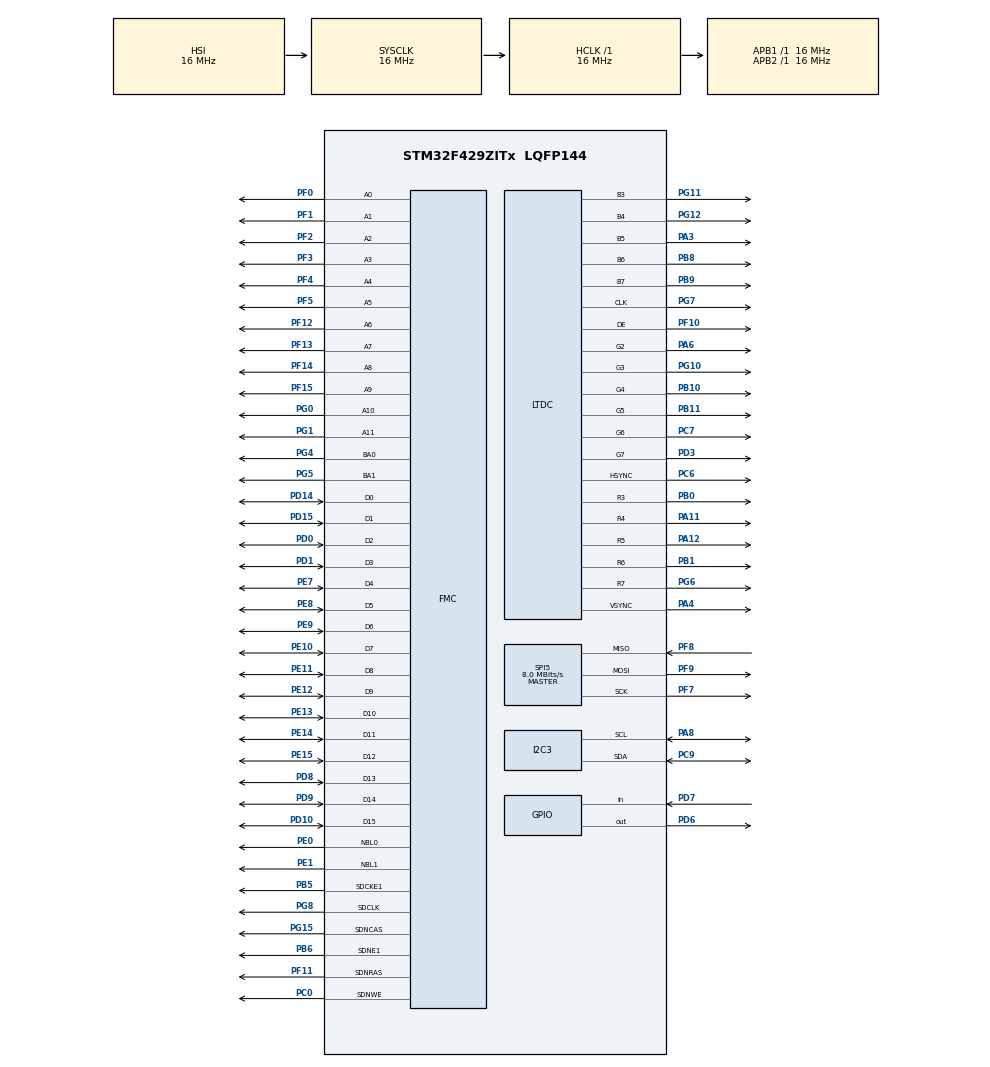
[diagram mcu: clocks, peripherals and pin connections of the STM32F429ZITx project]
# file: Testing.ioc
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DMA2D.ColorMode=DMA2D_OUTPUT_RGB565
LTDC.ActiveH=240
LTDC.ActiveW=320
Mcu.Family=STM32F4
Mcu.Name=STM32F429ZITx
Mcu.Package=LQFP144
NVIC.PriorityGroup=NVIC_PRIORITYGROUP_4
PA11.Mode=RGB565
PA11.Signal=LTDC_R4
PA12.Mode=RGB565
PA12.Signal=LTDC_R5
PA3.Mode=RGB565
PA3.Signal=LTDC_B5
PA4.Mode=RGB565
PA4.Signal=LTDC_VSYNC
PA6.Mode=RGB565
PA6.Signal=LTDC_G2
PA8.Mode=I2C
PA8.Signal=I2C3_SCL
PB0.Mode=RGB565
PB0.Signal=LTDC_R3
PB1.Mode=RGB565
PB1.Signal=LTDC_R6
PB10.Mode=RGB565
PB10.Signal=LTDC_G4
PB11.Mode=RGB565
PB11.Signal=LTDC_G5
PB5.Mode=SdramChipSelect2_1
PB5.Signal=FMC_SDCKE1
PB6.Mode=SdramChipSelect2_1
PB6.Signal=FMC_SDNE1
PB8.Mode=RGB565
PB8.Signal=LTDC_B6
PB9.Mode=RGB565
PB9.Signal=LTDC_B7
PC0.Signal=FMC_SDNWE
PC6.Mode=RGB565
PC6.Signal=LTDC_HSYNC
PC7.Mode=RGB565
PC7.Signal=LTDC_G6
PC9.Mode=I2C
PC9.Signal=I2C3_SDA
PD0.Signal=FMC_D2_DA2
PD1.Signal=FMC_D3_DA3
PD10.Signal=FMC_D15_DA15
PD14.Signal=FMC_D0_DA0
PD15.Signal=FMC_D1_DA1
PD3.Mode=RGB565
PD3.Signal=LTDC_G7
PD6.Signal=GPIO_Output
PD7.Signal=GPIO_Input
PD8.Signal=FMC_D13_DA13
PD9.Signal=FMC_D14_DA14
PE0.Signal=FMC_NBL0
PE1.Signal=FMC_NBL1
PE10.Signal=FMC_D7_DA7
PE11.Signal=FMC_D8_DA8
PE12.Signal=FMC_D9_DA9
PE13.Signal=FMC_D10_DA10
PE14.Signal=FMC_D11_DA11
PE15.Signal=FMC_D12_DA12
PE7.Signal=FMC_D4_DA4
PE8.Signal=FMC_D5_DA5
PE9.Signal=FMC_D6_DA6
PF0.Signal=FMC_A0
PF1.Signal=FMC_A1
PF10.Mode=RGB565
PF10.Signal=LTDC_DE
PF11.Signal=FMC_SDNRAS
PF12.Signal=FMC_A6
PF13.Signal=FMC_A7
PF14.Signal=FMC_A8
PF15.Signal=FMC_A9
PF2.Signal=FMC_A2
PF3.Signal=FMC_A3
PF4.Signal=FMC_A4
PF5.Signal=FMC_A5
PF7.Mode=Full_Duplex_Master
PF7.Signal=SPI5_SCK
PF8.Mode=Full_Duplex_Master
PF8.Signal=SPI5_MISO
PF9.Mode=Full_Duplex_Master
PF9.Signal=SPI5_MOSI
PG0.Signal=FMC_A10
PG1.Signal=FMC_A11
PG10.Mode=RGB565
PG10.Signal=LTDC_G3
PG11.Mode=RGB565
PG11.Signal=LTDC_B3
PG12.Mode=RGB565
PG12.Signal=LTDC_B4
PG15.Signal=FMC_SDNCAS
PG4.Signal=FMC_A14_BA0
PG5.Signal=FMC_A15_BA1
PG6.Mode=RGB565
PG6.Signal=LTDC_R7
PG7.Mode=RGB565
PG7.Signal=LTDC_CLK
PG8.Signal=FMC_SDCLK
ProjectManager.HeapSize=0x200
ProjectManager.StackSize=0x400
ProjectManager.TargetToolchain=STM32CubeIDE
RCC.48MHZClocksFreq_Value=90000000
RCC.AHBFreq_Value=16000000
RCC.APB1Freq_Value=16000000
RCC.APB2Freq_Value=16000000
RCC.CortexFreq_Value=16000000
RCC.HSE_VALUE=25000000
RCC.HSI_VALUE=16000000
RCC.LSE_VALUE=32768
RCC.PLLN=360
RCC.PLLSAIN=432
RCC.SYSCLKFreq_VALUE=16000000
RCC.VCOOutputFreq_Value=360000000
SH.FMC_A0.0=FMC_A0,12b-sda1
SH.FMC_A1.0=FMC_A1,12b-sda1
SH.FMC_A10.0=FMC_A10,12b-sda1
SH.FMC_A11.0=FMC_A11,12b-sda1
SH.FMC_A14_BA0.0=FMC_BA0,FourSdramBanks1
SH.FMC_A15_BA1.0=FMC_BA1,FourSdramBanks1
SH.FMC_A2.0=FMC_A2,12b-sda1
SH.FMC_A3.0=FMC_A3,12b-sda1
SH.FMC_A4.0=FMC_A4,12b-sda1
SH.FMC_A5.0=FMC_A5,12b-sda1
SH.FMC_A6.0=FMC_A6,12b-sda1
SH.FMC_A7.0=FMC_A7,12b-sda1
SH.FMC_A8.0=FMC_A8,12b-sda1
SH.FMC_A9.0=FMC_A9,12b-sda1
SH.FMC_D0_DA0.0=FMC_D0,sd-16b-d1
SH.FMC_D10_DA10.0=FMC_D10,sd-16b-d1
SH.FMC_D11_DA11.0=FMC_D11,sd-16b-d1
SH.FMC_D12_DA12.0=FMC_D12,sd-16b-d1
SH.FMC_D13_DA13.0=FMC_D13,sd-16b-d1
SH.FMC_D14_DA14.0=FMC_D14,sd-16b-d1
SH.FMC_D15_DA15.0=FMC_D15,sd-16b-d1
SH.FMC_D1_DA1.0=FMC_D1,sd-16b-d1
SH.FMC_D2_DA2.0=FMC_D2,sd-16b-d1
SH.FMC_D3_DA3.0=FMC_D3,sd-16b-d1
SH.FMC_D4_DA4.0=FMC_D4,sd-16b-d1
SH.FMC_D5_DA5.0=FMC_D5,sd-16b-d1
SH.FMC_D6_DA6.0=FMC_D6,sd-16b-d1
SH.FMC_D7_DA7.0=FMC_D7,sd-16b-d1
SH.FMC_D8_DA8.0=FMC_D8,sd-16b-d1
SH.FMC_D9_DA9.0=FMC_D9,sd-16b-d1
SH.FMC_NBL0.0=FMC_NBL0,Sd2ByteEnable1
SH.FMC_NBL1.0=FMC_NBL1,Sd2ByteEnable1
SH.FMC_SDCLK.0=FMC_SDCLK,12b-sda1
SH.FMC_SDNCAS.0=FMC_SDNCAS,12b-sda1
SH.FMC_SDNRAS.0=FMC_SDNRAS,12b-sda1
SH.FMC_SDNWE.0=FMC_SDNWE,12b-sda1
SPI5.CalculateBaudRate=8.0 MBits/s
SPI5.Direction=SPI_DIRECTION_2LINES
SPI5.Mode=SPI_MODE_MASTER
SPI5.VirtualType=VM_MASTER
VP_DMA2D_VS_DMA2D.Mode=DMA2D_Activate
board=custom

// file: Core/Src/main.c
/* USER CODE BEGIN Header */
/**
  ******************************************************************************
  * @file           : main.c
  * @brief          : Main program body
  ******************************************************************************
  * @attention
  *
  * <h2><center>&copy; Copyright (c) 2021 STMicroelectronics.
  * All rights reserved.</center></h2>
  *
  * This software component is licensed by ST under BSD 3-Clause license,
  * the "License"; You may not use this file except in compliance with the
  * License. You may obtain a copy of the License at:
  *                        opensource.org/licenses/BSD-3-Clause
  *
  ******************************************************************************
  */
/* USER CODE END Header */
#include "main.h"
#include "stm32f4xx_hal.h"
/* USER CODE BEGIN Includes */
#include "MA_ILI9341.h"
/* USER CODE END Includes */

DMA2D_HandleTypeDef hdma2d;

I2C_HandleTypeDef hi2c3;

LTDC_HandleTypeDef hltdc;

SPI_HandleTypeDef hspi5;

SDRAM_HandleTypeDef hsdram1;

void SystemClock_Config(void);
static void MX_GPIO_Init(void);
static void MX_DMA2D_Init(void);
static void MX_FMC_Init(void);
static void MX_I2C3_Init(void);
static void MX_LTDC_Init(void);
static void MX_SPI5_Init(void);

/* USER CODE BEGIN 0 */
uint8_t myImage[] =
{
	0xff,0xff,0xff,0xff,0xff,0xff,0xff,0xff,0xff,0xff,0xff,0xff,0xff,0xff,0xff,0xff,0xff,0xff,0xff,0xff,0xff,0xff,0xff,0xff,0xff,0xff,0xff,0xff,0xff,0xff,0xff,0xff,0xff,0xff,0xff,0xff,0xff,0xff,0xff,0xff,0xff,0xff,0xff,0xff,0xff,0xff,0xff,0xff,0xff,0xff,0xff,0xff,0xff,0xff,0xff,0xff,0xff,0xff,0xff,0xff,0xff,0xff,0xff,0xff,0xff,0xff,0xff,0xff,0xff,0xff,0xff,0xff,0x9c,0xb1,0x39,0x85,0x39,0xc6,0x39,0xc6,0x39,0xe6,0x4a,0x48,0x42,0x27,0x42,0x27,0x5a,0xe9,0xef,0x9d,0xff,0xff,0xff,0xff,0xff,0xff,0xff,0xff,0xff,0xff,0xff,0xff,0xff,0xff,0xff,0xff,0xff,0xff,0xff,0xff,0xff,0xff,0xff,0xff,0xff,0xff,0xff,0xff,0xff,0xff,0xff,0xff,0xff,0xff,0xff,0xff,0xff,0xff,0xff,0xff,0xff,0xff,0xff,0xff,0xff,0xff,0xff,0xff,0xff,0xff,0xff,0xff,0xff,0xff,0xff,0xff,0xff,0xff,0xff,0xff,0xff,0xff,0xff,0xff,0xff,0xff,0xff,0xff
,0xff,0xff,0xff,0xff,0xff,0xff,0xff,0xff,0xff,0xff,0xff,0xff,0xff,0xff,0xff,0xff,0xff,0xff,0xff,0xff,0xff,0xff,0xff,0xff,0xff,0xff,0xff,0xff,0xff,0xff,0xff,0xff,0xff,0xff,0xff,0xff,0xff,0xff,0xff,0xff,0xff,0xff,0xff,0xff,0xff,0xff,0xff,0xff,0xff,0xff,0xff,0xff,0xff,0xff,0xff,0xff,0xff,0xff,0xff,0xff,0xff,0xff,0xff,0xff,0xff,0xff,0xff,0xff,0xff,0xff,0xff,0xff,0x94,0x70,0x5a,0x88,0x41,0xe7,0x39,0xc6,0x29,0x44,0x31,0x84,0x39,0xa5,0x4a,0x27,0x52,0x68,0xf7,0x7d,0xff,0xff,0xff,0xff,0xff,0xff,0xff,0xff,0xff,0xff,0xff,0xff,0xff,0xff,0xff,0xff,0xff,0xff,0xff,0xff,0xff,0xff,0xff,0xff,0xff,0xff,0xff,0xff,0xff,0xff,0xff,0xff,0xff,0xff,0xff,0xff,0xff,0xff,0xff,0xff,0xff,0xff,0xff,0xff,0xff,0xff,0xff,0xff,0xff,0xff,0xff,0xff,0xff,0xff,0xff,0xff,0xff,0xff,0xff,0xff,0xff,0xff,0xff,0xff,0xff,0xff,0xff,0xff
,0x7e,0x32,0x65,0xb0,0x65,0xb0,0x65,0x90,0x65,0x90,0x65,0x90,0x65,0x90,0x65,0x90,0x6d,0x90,0x6d,0x90,0x6d,0x90,0x6d,0x90,0x6d,0x90,0x6d,0x90,0x6d,0x90,0x6d,0x90,0x6d,0x90,0x6d,0x90,0x6d,0x90,0x6d,0x90,0x65,0x90,0x65,0xb0,0x6d,0x90,0x65,0xb0,0x65,0x90,0x65,0x90,0x65,0x90,0x65,0x90,0x65,0x90,0x65,0x90,0x6d,0x90,0x6d,0x90,0x75,0x90,0xae,0x15,0xbd,0xd5,0xbd,0xb4,0x84,0x0e,0x6b,0x2a,0x4a,0x48,0x4a,0x27,0x31,0x65,0x41,0xe6,0x4a,0x27,0x6b,0x2a,0x5a,0xa8,0xd6,0x78,0xde,0xda,0xc6,0xd8,0x7d,0xd2,0x75,0xd2,0x75,0xd2,0x75,0xd2,0x75,0xf2,0x75,0xf2,0x75,0xf2,0x75,0xf2,0x75,0xf2,0x75,0xd2,0x7d,0xf2,0x7d,0xf2,0x7d,0xf2,0x7d,0xf2,0x7d,0xf2,0x7e,0x12,0x7e,0x12,0x7e,0x12,0x7d,0xf2,0x7d,0xf2,0x7d,0xf2,0x7d,0xf2,0x7d,0xf2,0x7d,0xf2,0x7d,0xf2,0x7d,0xf2,0x7d,0xf2,0x7d,0xf3,0x7d,0xf3,0x7e,0x13,0x7e,0x33,0x8e,0x74
,0x0c,0x68,0x04,0x06,0x03,0xe6,0x03,0xe6,0x03,0xe6,0x03,0xe6,0x03,0xc6,0x03,0xc6,0x03,0xe6,0x03,0xc6,0x03,0xe6,0x03,0xe6,0x03,0xe6,0x03,0xe6,0x03,0xe6,0x03,0xe6,0x03,0xe6,0x03,0xe6,0x03,0xe6,0x03,0xe6,0x03,0xe6,0x03,0xe6,0x03,0xe6,0x04,0x06,0x04,0x06,0x03,0xe6,0x03,0xe6,0x03,0xe6,0x03,0xe6,0x03,0xe6,0x03,0xe6,0x03,0xe6,0x03,0xc6,0x6c,0xee,0xe7,0x1a,0xc5,0xd4,0x83,0xed,0x52,0x68,0x52,0x68,0x6b,0x4b,0x42,0x26,0x6b,0x2a,0x5a,0xc9,0x7b,0xad,0x4a,0x47,0xbd,0xd4,0xef,0x7c,0xa6,0x14,0x03,0xc6,0x03,0xe7,0x03,0xe7,0x03,0xe6,0x03,0xc6,0x03,0xc6,0x03,0xc6,0x03,0xe6,0x03,0xe6,0x03,0xe6,0x03,0xe6,0x03,0xe6,0x03,0xe6,0x03,0xe6,0x03,0xe7,0x03,0xe7,0x03,0xe7,0x03,0xe7,0x03,0xe7,0x03,0xe7,0x03,0xe7,0x03,0xe7,0x03,0xe7,0x03,0xe7,0x03,0xe6,0x03,0xe6,0x03,0xe7,0x03,0xe7,0x03,0xe7,0x03,0xe7,0x04,0x07,0x0c,0x28
,0x04,0x48,0x04,0x07,0x04,0x07,0x03,0xe7,0x03,0xe6,0x03,0xc7,0x03,0xa6,0x03,0x86,0x03,0xa6,0x03,0xc6,0x03,0xc6,0x03,0xc6,0x03,0xc6,0x03,0xc6,0x03,0xc6,0x03,0xe6,0x03,0xe6,0x03,0xe6,0x03,0xc6,0x03,0xe6,0x03,0xe6,0x03,0xe7,0x03,0xc6,0x03,0xe6,0x04,0x06,0x03,0xe6,0x03,0xe6,0x03,0xe6,0x03,0xe6,0x03,0xc6,0x03,0xc6,0x03,0xc6,0x03,0xe6,0x5c,0x6c,0xa5,0x12,0x9c,0x8f,0x7b,0xac,0x5a,0x89,0x42,0x27,0x8c,0x2e,0xce,0x36,0xbd,0xb5,0x4a,0x47,0x73,0xac,0x4a,0x47,0x94,0x90,0xad,0x74,0x95,0x52,0x03,0xa7,0x03,0xc7,0x03,0xc7,0x03,0xe7,0x03,0xe7,0x03,0xe7,0x03,0x86,0x03,0x86,0x03,0xe6,0x03,0xe6,0x03,0xe6,0x03,0xc6,0x03,0xc6,0x03,0xe7,0x03,0xe7,0x03,0xe7,0x03,0xe7,0x03,0xe7,0x03,0xe7,0x03,0xe7,0x03,0xe7,0x03,0xe7,0x03,0xe7,0x03,0xc7,0x03,0xa7,0x03,0xa7,0x03,0xe7,0x03,0xe7,0x03,0xe7,0x03,0xe7,0x03,0xe7,0x0c,0x08
,0x04,0x27,0x03,0xe7,0x03,0xe7,0x03,0xe6,0x03,0xe6,0x03,0xe7,0x33,0x89,0x4b,0xca,0x33,0x69,0x03,0xc6,0x03,0xc6,0x03,0xc6,0x03,0xc6,0x03,0xc6,0x03,0xe6,0x03,0xe6,0x03,0xe6,0x03,0xe6,0x03,0xe6,0x03,0xe6,0x03,0xe6,0x03,0xe6,0x03,0xe6,0x03,0xe6,0x03,0xe6,0x03,0xe6,0x03,0xe6,0x03,0xe6,0x03,0xe6,0x03,0xe5,0x03,0xe6,0x03,0xc6,0x03,0xe6,0x5c,0x6c,0x94,0x90,0x7b,0xab,0x73,0x6b,0x41,0xe6,0x42,0x06,0x5a,0xa8,0x94,0x6f,0x7b,0xcd,0x42,0x06,0x4a,0x88,0x52,0x88,0x94,0x4e,0xa5,0x32,0x95,0x52,0x03,0x87,0x03,0xe7,0x03,0xc7,0x03,0xe7,0x03,0xe7,0x03,0xa6,0x64,0x49,0x6c,0x69,0x03,0xa6,0x03,0xc7,0x03,0xc6,0x03,0xc6,0x03,0xc6,0x03,0xe7,0x03,0xe7,0x03,0xe7,0x03,0xe7,0x03,0xe7,0x03,0xe7,0x03,0xe7,0x03,0xe7,0x03,0xe7,0x03,0xe7,0x23,0x68,0x2b,0x27,0x3b,0x88,0x03,0xa7,0x03,0xe7,0x03,0xe7,0x03,0xe7,0x03,0xe7,0x14,0x08
,0x04,0x27,0x03,0xe7,0x03,0xe7,0x03,0xe7,0x03,0xe7,0x03,0xe7,0x2b,0x07,0x74,0x0a,0x4b,0xca,0x03,0xa6,0x03,0xc6,0x03,0xc6,0x03,0xc6,0x03,0xa5,0x03,0xe6,0x03,0xe6,0x03,0xe6,0x1c,0x28,0x3c,0x4b,0x33,0xa9,0x44,0x2b,0x23,0xe8,0x03,0x45,0x03,0x46,0x03,0x26,0x03,0x46,0x03,0x45,0x03,0x25,0x03,0x45,0x03,0xa6,0x03,0xe6,0x03,0xe6,0x03,0xe6,0x74,0xcf,0xd6,0x98,0xa5,0x31,0x73,0x8b,0x10,0xc2,0x18,0xc2,0x29,0x44,0x29,0x03,0x29,0x44,0x21,0x03,0x20,0xe2,0x4a,0x47,0xad,0x73,0xef,0x5c,0xa5,0xb4,0x03,0x86,0x03,0xe7,0x03,0xa6,0x03,0xe7,0x03,0xe7,0x03,0xc7,0x33,0x66,0x3b,0x87,0x03,0xc6,0x03,0xc7,0x03,0xc7,0x03,0xc6,0x03,0xc6,0x03,0xe7,0x03,0xe7,0x03,0xe7,0x03,0xe7,0x03,0xe7,0x03,0xe7,0x03,0xe7,0x03,0xe7,0x03,0xe7,0x03,0xe7,0x1b,0x07,0x6b,0xca,0x4b,0xeb,0x03,0xa7,0x03,0xe7,0x03,0xe7,0x03,0xc7,0x03,0xe7,0x14,0x08
,0x04,0x27,0x03,0xe7,0x03,0xe7,0x03,0xe7,0x03,0xe7,0x03,0xe7,0x33,0x89,0x4b,0x49,0x4b,0xaa,0x03,0xc6,0x03,0xc6,0x03,0xc6,0x03,0xc6,0x03,0xc6,0x03,0xe6,0x03,0xe6,0x03,0xe6,0x34,0x2a,0x84,0x4f,0x52,0x89,0x8c,0x8f,0x5c,0x6c,0x64,0xee,0x2c,0x49,0x03,0xa6,0x03,0xa6,0x03,0xa6,0x03,0x85,0x0b,0x45,0x03,0x45,0x03,0xc6,0x03,0xe6,0x03,0xe6,0x13,0x47,0x23,0x47,0x3b,0x68,0x63,0x2a,0x10,0xc2,0x10,0xa1,0x52,0x68,0x7b,0xad,0x63,0x0b,0x18,0xe2,0x20,0xe3,0x52,0x27,0x53,0xca,0x23,0x47,0x23,0x67,0x03,0xa7,0x03,0xc7,0x03,0xc7,0x03,0xc7,0x03,0xe7,0x03,0xe7,0x03,0xc6,0x03,0xc6,0x03,0xc7,0x03,0xc6,0x03,0xc7,0x03,0xe7,0x03,0xe7,0x03,0xe7,0x03,0xe7,0x03,0xe7,0x03,0xe7,0x03,0xe7,0x03,0xe7,0x03,0xe7,0x03,0xe7,0x03,0xe7,0x03,0xe7,0x2b,0x69,0x43,0x49,0x4b,0xaa,0x03,0xa7,0x03,0xe7,0x03,0xe7,0x03,0xc7,0x03,0xc7,0x14,0x08
,0x04,0x08,0x03,0xe7,0x03,0xe7,0x03,0xe7,0x03,0xe7,0x03,0xc7,0x03,0x46,0x2b,0x88,0x0b,0x66,0x03,0xc6,0x03,0xc6,0x03,0xc6,0x03,0xc6,0x03,0xe6,0x03,0xe6,0x03,0xc6,0x03,0xc6,0x2c,0x29,0x84,0x6f,0x5b,0x2a,0x7c,0x4e,0x4b,0xcb,0x1b,0xc9,0x13,0xc8,0x03,0x65,0x03,0x65,0x03,0x65,0x03,0x65,0x03,0x65,0x03,0xc6,0x03,0xe6,0x03,0xa6,0x03,0xc6,0x0b,0x46,0x13,0x47,0x4b,0xea,0x63,0x4a,0x10,0xa1,0x18,0xc2,0x63,0x0a,0xad,0x53,0x5a,0xea,0x31,0x64,0x20,0xe2,0x4a,0x47,0x4b,0xea,0x13,0x47,0x0b,0x46,0x03,0xa7,0x03,0xc7,0x1c,0x09,0x0b,0xe8,0x03,0xe7,0x03,0xe7,0x03,0xe7,0x03,0xc6,0x03,0xe6,0x03,0xc7,0x03,0xc7,0x03,0xc7,0x03,0xc6,0x03,0xc6,0x03,0xc6,0x03,0xe7,0x03,0xe7,0x03,0xc7,0x03,0xe7,0x03,0xe7,0x03,0xe7,0x04,0x07,0x04,0x07,0x03,0xa7,0x3b,0xeb,0x0b,0x67,0x03,0xe7,0x03,0xe7,0x03,0xe7,0x03,0xe7,0x03,0xc7,0x13,0xe8
,0x04,0x07,0x03,0xe7,0x03,0xe7,0x03,0xe7,0x03,0xe6,0x03,0xc6,0x13,0x87,0x74,0x6d,0x33,0xc9,0x03,0xa6,0x03,0xc6,0x03,0xc6,0x03,0xc6,0x03,0xc6,0x03,0xe6,0x03,0xc6,0x03,0xc6,0x1b,0xe7,0xbe,0x37,0xb5,0xd5,0xd6,0xb8,0x85,0x50,0x2c,0x49,0x03,0xc6,0x03,0xc6,0x03,0xc6,0x03,0xc6,0x03,0xe6,0x03,0xe6,0x03,0xe6,0x0c,0x07,0x0b,0xe7,0x03,0xe7,0x64,0x8f,0xce,0x98,0x9d,0x32,0x6b,0x4b,0x10,0xa1,0x63,0x0a,0x73,0x6b,0xad,0x33,0x73,0xcd,0x73,0x4c,0x31,0x23,0x52,0x47,0xa5,0x52,0xd6,0x79,0xa5,0x93,0x0b,0xa7,0x13,0xe8,0x65,0x0e,0x3c,0xac,0x03,0xe7,0x03,0xe7,0x03,0xc6,0x03,0xa6,0x03,0xc6,0x03,0xc6,0x03,0xc6,0x03,0xc6,0x03,0xc6,0x03,0xc6,0x03,0xc6,0x03,0xc7,0x03,0xc7,0x03,0xc7,0x03,0xe7,0x03,0xc6,0x03,0xe7,0x03,0xc6,0x03,0xe6,0x23,0xe9,0x63,0xea,0x6c,0xac,0x03,0xc7,0x03,0xe7,0x03,0xe7,0x03,0xe7,0x03,0xe7,0x13,0xe8
,0x04,0x27,0x03,0xe6,0x03,0xe6,0x03,0xc6,0x03,0xc6,0x03,0xc6,0x0b,0x86,0x43,0xa9,0x44,0x4a,0x03,0xa6,0x03,0xc6,0x03,0xc6,0x03,0xc6,0x03,0xa5,0x03,0xa6,0x44,0xec,0x4c,0x8c,0x54,0xac,0xef,0x5b,0xe7,0x3b,0xef,0x5b,0xa5,0xd4,0x3c,0x6b,0x03,0xc6,0x03,0xc7,0x03,0xa6,0x03,0xc6,0x03,0xc6,0x03,0xe6,0x03,0xe6,0x55,0x0d,0x75,0x91,0x3c,0xac,0x6c,0x6d,0xad,0x53,0x83,0xed,0x6b,0x4b,0x10,0xa1,0x5a,0xa9,0x6b,0x4b,0x6b,0x2b,0x6b,0x4b,0x63,0x0a,0x29,0x23,0x4a,0x47,0x8c,0x2e,0xad,0x33,0x8d,0x12,0x03,0xa7,0x44,0x8c,0x74,0xef,0x5c,0x6d,0x02,0xe5,0x03,0xc7,0x03,0xc6,0x03,0xa6,0x03,0xc6,0x03,0xa7,0x03,0x86,0x03,0xa7,0x03,0x87,0x0b,0xa7,0x0b,0xe8,0x03,0xa6,0x0b,0xc7,0x0b,0xa7,0x03,0xa7,0x03,0xc7,0x03,0xe7,0x03,0xe7,0x03,0xe6,0x1b,0xe8,0x54,0x0b,0x4c,0xac,0x03,0xc7,0x03,0xc7,0x03,0xc7,0x03,0xe7,0x03,0xe7,0x14,0x08
,0x04,0x27,0x03,0xe6,0x03,0xe6,0x03,0xc6,0x03,0xc6,0x03,0xc6,0x03,0x85,0x03,0x04,0x03,0x44,0x03,0xa6,0x03,0xc5,0x0b,0xe6,0x0c,0x07,0x03,0xe7,0x03,0xc6,0x24,0x28,0x24,0x29,0x44,0x4b,0xdf,0x1a,0xd6,0xd9,0xde,0xd9,0xa5,0xf4,0x13,0xa7,0x14,0x29,0x14,0x08,0x0c,0x07,0x03,0xc6,0x03,0xc6,0x03,0xc6,0x03,0xe6,0x03,0xe6,0x03,0xc7,0x0b,0xc8,0x6c,0x8e,0xa5,0x53,0x73,0x8b,0x63,0xcd,0x8c,0x6e,0x8c,0x0c,0x7b,0xed,0x73,0xcc,0x7b,0xab,0x83,0xcb,0x84,0x2d,0x6c,0x0d,0x6b,0x6c,0xb5,0x93,0x8d,0x11,0x03,0xa7,0x3b,0xea,0x95,0x12,0x64,0x2d,0x2b,0xaa,0x4c,0x8c,0x24,0x29,0x34,0x49,0x03,0xa7,0x03,0x05,0x33,0xc9,0x2b,0xa9,0x0b,0x46,0x3c,0x2b,0x5c,0xef,0x0b,0x47,0x4c,0x8c,0x5c,0xee,0x03,0x46,0x03,0x46,0x03,0xe7,0x03,0xe7,0x03,0xe7,0x03,0xc7,0x0b,0x66,0x03,0xa7,0x03,0xc7,0x03,0xe7,0x03,0xe7,0x03,0xe7,0x03,0xe7,0x13,0xe8
,0x04,0x07,0x03,0xa6,0x03,0xe6,0x03,0xc6,0x03,0xc6,0x03,0xa6,0x03,0x85,0x03,0x04,0x03,0x45,0x03,0x85,0x03,0xa6,0x2c,0x6a,0x5d,0x0e,0x24,0x49,0x03,0xc6,0x03,0xc6,0x03,0xc6,0x34,0x2a,0xe7,0x5a,0xdf,0x1a,0xe7,0x1a,0xa5,0xd3,0x24,0x29,0x3c,0xac,0x65,0x4f,0x3c,0xab,0x03,0xe6,0x03,0xe6,0x03,0xe6,0x03,0xe6,0x03,0xc6,0x03,0xe6,0x03,0xc7,0x6c,0x6e,0xad,0xb4,0xb5,0x93,0x12,0x64,0x23,0x06,0x42,0xe7,0x42,0xa7,0x3a,0x86,0x3a,0x86,0x3a,0xe7,0x32,0xc7,0x3b,0x89,0x7c,0x4e,0xad,0x52,0x95,0x31,0x03,0x87,0x33,0x89,0x29,0x84,0x3b,0x28,0x12,0xe6,0x5c,0x6d,0x3b,0xa9,0x34,0x09,0x03,0x86,0x13,0x06,0x4c,0x0b,0x43,0x6a,0x44,0x2c,0x0a,0x85,0x1a,0xc6,0x0a,0xc5,0x0b,0x25,0x0b,0x25,0x03,0x25,0x03,0x46,0x03,0xc7,0x03,0xe6,0x03,0xe7,0x03,0xc6,0x03,0xa7,0x03,0xa7,0x03,0xc7,0x03,0xe7,0x03,0xe7,0x03,0xe7,0x03,0xe7,0x13,0xe8
,0x0c,0x07,0x03,0xe6,0x03,0xc6,0x03,0xc6,0x03,0xa5,0x03,0x65,0x13,0x87,0x23,0x87,0x13,0x87,0x03,0x85,0x03,0xa6,0x54,0xad,0x7d,0x0f,0x3c,0x0b,0x2b,0xc9,0x3c,0x6a,0x03,0xc6,0x34,0x29,0xc6,0x57,0xbe,0x36,0xd6,0xb8,0x9d,0x51,0x0b,0x86,0x03,0x85,0x03,0xc6,0x03,0xa5,0x03,0xc5,0x2c,0x4a,0x2c,0x6b,0x3c,0xac,0x44,0xed,0x34,0x2a,0x6d,0x91,0x3b,0xa9,0x64,0x8e,0x4b,0xaa,0x02,0xa4,0x02,0x82,0x0a,0x84,0x09,0xe3,0x09,0xe3,0x09,0xe3,0x0a,0x24,0x3b,0x08,0x3b,0xca,0x33,0x08,0x74,0x8f,0x4b,0xcb,0x03,0x26,0x3b,0x48,0x10,0xe2,0x33,0x08,0x4c,0x2c,0xad,0xb4,0x74,0xcf,0x95,0x93,0x44,0x2b,0x5c,0x2c,0x84,0x6f,0x84,0x8e,0x9d,0x72,0x33,0x28,0x9d,0x31,0x7c,0xef,0x34,0x4a,0x34,0x29,0x03,0x25,0x03,0x46,0x03,0xc7,0x03,0xe7,0x03,0xc7,0x03,0xc6,0x03,0xc7,0x03,0xc7,0x03,0xc7,0x03,0xc6,0x03,0xc7,0x03,0xe7,0x03,0xe7,0x13,0xe8
,0x0c,0x07,0x03,0xc6,0x03,0xc6,0x03,0xc6,0x03,0x85,0x03,0x66,0x3b,0x88,0x5b,0xab,0x3b,0x48,0x03,0x65,0x03,0x65,0x43,0x89,0x9d,0x53,0x54,0x2d,0x64,0x6e,0x44,0x8b,0x03,0xc6,0x03,0x65,0x5c,0x0c,0x4b,0x6a,0x7c,0x8e,0x3b,0x48,0x03,0x66,0x03,0x85,0x03,0x85,0x03,0x85,0x03,0xa5,0x3c,0x6b,0x3c,0xab,0x55,0x0e,0x54,0xee,0x5c,0xee,0x75,0x90,0x0b,0xc6,0x03,0xa6,0x03,0x65,0x03,0x05,0x02,0xa4,0x33,0x68,0x6c,0x6e,0x5b,0xcb,0x64,0x2d,0x43,0x8a,0x23,0x27,0x02,0xa4,0x03,0x05,0x03,0x06,0x03,0x26,0x03,0x26,0x4b,0xea,0x7c,0x2e,0x3b,0x69,0x43,0xca,0x8c,0x2d,0x64,0x0b,0x8c,0x4d,0x53,0xaa,0x53,0x49,0x42,0x26,0x4a,0x46,0x52,0xa8,0x43,0x69,0x7c,0x0c,0x63,0xcb,0x7c,0x8f,0x7c,0xaf,0x02,0xa5,0x03,0x46,0x03,0xc7,0x03,0xc7,0x03,0xc7,0x03,0xc7,0x03,0xc6,0x03,0xc6,0x03,0xc6,0x03,0xc6,0x03,0xc7,0x03,0xe7,0x03,0xc7,0x13,0xe8
,0x0c,0x07,0x03,0xc6,0x03,0xc6,0x03,0xa6,0x03,0xa6,0x13,0x67,0x19,0x83,0x4a,0x67,0x31,0xa4,0x3c,0x09,0x03,0x25,0x22,0x45,0x29,0x84,0x64,0x2c,0xad,0xf5,0x44,0x8b,0x03,0xc6,0x03,0xa6,0x54,0x4c,0x53,0xab,0x64,0x2c,0x43,0xca,0x03,0x66,0x03,0x65,0x03,0x65,0x03,0x65,0x03,0xa5,0x2c,0x49,0x03,0xc7,0x0b,0xa7,0x0b,0xa7,0x0b,0xa6,0x0b,0xc7,0x0b,0x86,0x03,0xa6,0x0b,0x66,0x0a,0xc4,0x4b,0xeb,0x6c,0x6d,0x7c,0x8f,0x8c,0xcf,0x84,0xaf,0x7c,0x6e,0x13,0x47,0x03,0x45,0x03,0x66,0x23,0xc8,0x54,0x6c,0x75,0x30,0x54,0x4b,0x5b,0xec,0x44,0x0b,0x44,0x0b,0x9c,0xd0,0x6c,0x0c,0x6c,0x2d,0x54,0x0b,0x32,0x47,0x21,0x44,0x21,0x24,0x29,0x64,0x43,0x8a,0x84,0x6e,0x74,0x6e,0x95,0x10,0x74,0x8e,0x02,0xc5,0x03,0x66,0x03,0xc7,0x03,0xc7,0x03,0xc7,0x03,0xe7,0x03,0xe7,0x03,0xc6,0x03,0xc6,0x03,0xe7,0x03,0xe7,0x03,0xe7,0x03,0xe7,0x0c,0x08
,0x0c,0x07,0x03,0xc6,0x03,0xc6,0x03,0xa5,0x85,0x90,0x9d,0xb2,0x19,0x02,0x4a,0x46,0x19,0x02,0x3b,0x68,0x02,0x84,0x19,0xc4,0x19,0x23,0x64,0x0c,0x7c,0x6f,0x4b,0xea,0x0b,0xc7,0x44,0xac,0x74,0x0c,0x6c,0x0c,0x63,0x6a,0x5c,0x4c,0x4c,0xcd,0x03,0x66,0x2c,0x09,0x23,0xe8,0x03,0xa6,0x2c,0x4a,0x34,0x8b,0x85,0x30,0x95,0x52,0x95,0x52,0x95,0x93,0x95,0x72,0x7d,0x10,0x95,0x31,0x54,0x0c,0x53,0xab,0x7c,0x2e,0x7c,0x0d,0x84,0x0d,0x7c,0x4e,0x7b,0xcc,0x1c,0x08,0x03,0xa6,0x03,0xa6,0x14,0x08,0x4c,0xcd,0x24,0x09,0x54,0xcd,0xb5,0xf4,0x5c,0xce,0x4c,0x4b,0x8d,0x10,0x53,0xcb,0x2b,0xc9,0x13,0x47,0x3a,0xe8,0x3a,0x06,0x21,0xc4,0x63,0x2a,0x4b,0xeb,0x6c,0x6e,0x64,0x6d,0x64,0x8e,0x54,0x0c,0x02,0xc5,0x03,0x66,0x03,0xc7,0x03,0xe6,0x03,0xe6,0x03,0xe6,0x03,0xe6,0x03,0xe6,0x03,0xe7,0x03,0xe7,0x03,0xe7,0x03,0xe7,0x03,0xe7,0x0b,0xe8
,0x0c,0x07,0x03,0xc6,0x03,0xc6,0x03,0xa5,0x34,0x09,0x43,0xe9,0x29,0xa4,0x18,0xa1,0x21,0x03,0x3b,0x48,0x02,0x24,0x3a,0xe8,0x74,0x2e,0x6c,0x8d,0x84,0xf0,0x4b,0xeb,0x13,0x67,0x75,0x4f,0x8c,0xf0,0x95,0x11,0x84,0x8f,0x74,0xae,0x5c,0xcd,0x1b,0x67,0x5c,0x6c,0x33,0xea,0x03,0x87,0x03,0xc7,0x03,0xc7,0x64,0x2c,0x63,0xcc,0x5b,0x6a,0x7c,0x8f,0x53,0x29,0x6c,0x6e,0x52,0xe8,0x53,0xeb,0x7c,0xaf,0x95,0x31,0x63,0xcc,0x63,0xcc,0x6c,0x0d,0x63,0x6b,0x1c,0x08,0x03,0xa6,0x03,0xc6,0x44,0xac,0x65,0x0f,0x2c,0x49,0x7c,0xef,0xd6,0x75,0x4c,0x2b,0x4c,0x4b,0xa5,0x92,0x8c,0x6e,0x9d,0x52,0x3b,0xa9,0x32,0xe7,0x2a,0xa6,0x0a,0x03,0x5b,0xac,0x03,0x06,0x03,0x87,0x23,0xe9,0x6c,0x8e,0x64,0x6e,0x02,0xc5,0x03,0x66,0x03,0xc7,0x03,0xc7,0x03,0xe7,0x03,0xe7,0x03,0xe6,0x03,0xe6,0x0b,0xc7,0x03,0xe7,0x03,0xe7,0x03,0xe7,0x03,0xe7,0x0b,0xe8
,0x0c,0x07,0x03,0xc6,0x03,0xc6,0x03,0xa5,0x03,0x65,0x0b,0x25,0x21,0xa4,0x39,0x84,0x18,0xe2,0x3b,0x29,0x02,0x24,0x43,0x8a,0x53,0xeb,0x3b,0xc9,0x0b,0x05,0x03,0x05,0x03,0x25,0x13,0x86,0x4c,0x0b,0x4c,0x2b,0x44,0x8c,0x34,0x2a,0x5c,0x4c,0xce,0x77,0xbd,0xd5,0xb6,0x15,0x44,0x0b,0x03,0xc7,0x03,0xc6,0x75,0x0f,0x84,0xf0,0x85,0x10,0x85,0x30,0x84,0xf0,0x74,0xcf,0x7c,0xcf,0x5c,0xcd,0x44,0x2a,0x54,0x2c,0x7c,0x6e,0x94,0xf0,0x8c,0xf0,0x94,0xcf,0x23,0xa8,0x0b,0x46,0x0b,0xa6,0x34,0x6a,0x7d,0x91,0x2c,0x29,0x7c,0xef,0xce,0x14,0x54,0x6c,0x44,0x4b,0x84,0x2d,0x5b,0x09,0x74,0x0d,0x64,0x6e,0x4c,0x4c,0x0b,0x26,0x03,0x65,0x03,0x66,0x03,0x66,0x03,0x86,0x2c,0x09,0x4b,0x2a,0x5b,0xcc,0x4c,0x0b,0x44,0x2b,0x7d,0xb1,0x7d,0x91,0x6d,0x70,0x7d,0x91,0x6d,0x30,0x5d,0x2f,0x75,0x90,0x3c,0xac,0x4c,0xed,0x03,0xe7,0x03,0xc7,0x0c,0x08
,0x0c,0x07,0x03,0xc7,0x03,0xc7,0x03,0x86,0x03,0x45,0x02,0xe4,0x19,0x42,0x6a,0xe8,0x18,0xe2,0x3b,0x08,0x02,0x64,0x3b,0x89,0x74,0x2e,0x74,0x0d,0x5c,0x4c,0x02,0xa4,0x02,0xc4,0x03,0x25,0x03,0x65,0x03,0x86,0x03,0xc6,0x23,0xc7,0xa5,0x11,0x52,0x68,0x39,0x84,0x4a,0x27,0x7c,0x4e,0x13,0xc8,0x03,0xe7,0x1b,0x48,0x1b,0x07,0x33,0x89,0x7c,0xce,0x23,0x47,0x13,0x26,0x13,0x26,0x23,0x67,0x65,0x0f,0x3c,0x0a,0x3b,0xea,0x33,0xc9,0x3b,0xea,0x3b,0xeb,0x2b,0xa9,0x75,0x10,0x2b,0xca,0x34,0x2a,0x54,0xee,0x03,0xc7,0x4c,0x8d,0xa5,0xd4,0x54,0x8d,0x1b,0xe9,0x34,0x0a,0x23,0xc8,0x2b,0xea,0x2b,0xe9,0x1b,0xa9,0x03,0x45,0x03,0x66,0x03,0x86,0x0b,0xa7,0x24,0x09,0x3c,0x0a,0x21,0x64,0x3a,0x68,0x4c,0x0c,0x8d,0x92,0x6d,0x2f,0x85,0x91,0x75,0x70,0x95,0xf3,0x5c,0xee,0x5d,0x2e,0x55,0x0d,0x5d,0x0e,0x6d,0x70,0x03,0xe7,0x03,0xe7,0x0c,0x07
,0x0c,0x08,0x03,0xc7,0x03,0xa7,0x5c,0xcd,0x5c,0xad,0x13,0x26,0x21,0x64,0x10,0xa1,0x18,0xe3,0x3b,0xa9,0x03,0x05,0x44,0x2b,0x6c,0x2d,0x64,0x2c,0x54,0x4b,0x03,0x45,0x13,0x66,0x1b,0x67,0x0b,0xc7,0x24,0x49,0x03,0xc6,0x44,0x2a,0x8c,0x0e,0x39,0xa5,0x39,0xc5,0x42,0x26,0x73,0x8c,0x2b,0xe9,0x0b,0xc7,0x54,0x8d,0x3c,0x0a,0x43,0x8a,0x8c,0x8e,0x2b,0x89,0x0b,0x05,0x13,0x06,0x2b,0x88,0x3b,0xe9,0x2b,0xa8,0x33,0x89,0x23,0x68,0x12,0xe6,0x64,0x6c,0xad,0xd4,0x5c,0x4c,0x23,0x68,0x2b,0x89,0x4c,0xcd,0x03,0xc7,0x44,0x6b,0x95,0x31,0x4c,0x8c,0x2c,0x0a,0x1b,0x47,0x03,0x06,0x03,0x06,0x2b,0x68,0x54,0x0c,0x43,0xea,0x74,0xef,0x4c,0x2b,0x1b,0x47,0x5c,0x6d,0x64,0xad,0x3a,0x47,0x4b,0x2a,0x0a,0xa5,0x0b,0x87,0x0b,0x87,0x14,0x08,0x0b,0xe7,0x14,0x08,0x14,0x08,0x03,0xe7,0x0b,0xe7,0x0b,0xe7,0x0b,0xe7,0x03,0xc7,0x03,0xc6,0x0b,0xe7
,0x0c,0x07,0x03,0xc7,0x03,0xc6,0x64,0xcd,0x54,0x8d,0x1b,0x46,0x29,0xc5,0x18,0xc2,0x19,0x23,0x33,0xa9,0x03,0x45,0x34,0x29,0x6d,0x2e,0x54,0xcc,0x0b,0xa6,0x44,0x8b,0x8d,0x50,0x94,0xf0,0x5c,0x0c,0x8c,0xd0,0x3b,0xc9,0x53,0xaa,0x83,0xed,0x4a,0x47,0x6b,0x4b,0x4a,0x48,0x73,0x8b,0x2b,0xa9,0x03,0xa7,0x13,0x47,0x02,0xc5,0x54,0x0b,0xa5,0x92,0x2b,0x89,0x43,0x6a,0x74,0x6e,0x63,0xab,0x74,0x4d,0x74,0x2d,0x5b,0xcb,0x7c,0x8e,0x43,0x8b,0x4b,0x69,0x94,0x8e,0x2b,0x67,0x02,0xe5,0x02,0xe5,0x02,0xe5,0x03,0x25,0x4c,0x0b,0x4a,0xc8,0x74,0xae,0x5c,0xce,0x4c,0x6c,0x02,0xe6,0x02,0xe6,0x5c,0x0c,0x94,0xf1,0x23,0x08,0x23,0x47,0x33,0xa9,0x03,0x06,0x0b,0x06,0x4c,0x0c,0x64,0x0c,0x64,0x4d,0x03,0x46,0x03,0x26,0x03,0x46,0x03,0x86,0x03,0xe6,0x03,0xe6,0x03,0xc7,0x03,0xc6,0x03,0xe7,0x03,0xe7,0x03,0xe7,0x03,0xe7,0x03,0xc6,0x0b,0xe7
,0x0c,0x07,0x03,0xc7,0x03,0xc6,0x4c,0x8b,0x6d,0x4f,0x0b,0x06,0x19,0x42,0x7b,0x68,0x18,0xc1,0x33,0x87,0x03,0x24,0x03,0x45,0x13,0xa6,0x13,0xe7,0x03,0x85,0x3c,0x4b,0x7c,0xef,0x63,0xab,0x64,0x2c,0x8c,0x6f,0x8d,0x51,0x85,0x10,0x84,0x0d,0x4a,0x27,0x84,0x0e,0x52,0x88,0x73,0x8b,0x2b,0x88,0x03,0xa6,0x03,0x26,0x02,0xc5,0x23,0x47,0x7c,0xef,0x12,0xa5,0x43,0x49,0x74,0x2e,0x63,0x8c,0x7c,0x4e,0x7c,0x0d,0x63,0x8b,0x84,0x4e,0x43,0x4a,0x3b,0x69,0x85,0x11,0x1b,0x67,0x03,0x26,0x03,0x05,0x02,0xe5,0x03,0x26,0x44,0x2b,0x8c,0xf0,0x3c,0x4b,0x03,0x26,0x1b,0x27,0xb6,0x35,0x95,0x12,0x31,0xc6,0x39,0x85,0x42,0x48,0xad,0xf4,0xd6,0xf9,0x4c,0x8d,0x4c,0x4c,0x4c,0x4c,0x75,0x30,0x6d,0x30,0x03,0xa7,0x03,0x66,0x03,0x26,0x03,0x46,0x03,0xa6,0x03,0xe7,0x03,0xe7,0x03,0xe7,0x03,0xe7,0x03,0xc6,0x03,0xe7,0x03,0xe7,0x03,0xe7,0x0c,0x07
,0x0c,0x07,0x03,0xc7,0x03,0xc6,0x54,0xcd,0x6c,0xce,0x13,0x06,0x19,0x23,0x18,0xc1,0x18,0xc1,0x33,0x88,0x03,0x44,0x03,0x65,0x03,0xa5,0x03,0xc6,0x03,0xa6,0x44,0xcc,0x75,0x0f,0x74,0xef,0x54,0x6b,0x8d,0x70,0x54,0xac,0x5c,0x6d,0x84,0x2d,0x4a,0x68,0x73,0xac,0x52,0xa8,0x73,0x8b,0x2b,0x68,0x1c,0x08,0x3b,0xe9,0x2b,0xa8,0x1b,0x27,0x85,0x10,0x3b,0x29,0x31,0xc6,0x31,0xe6,0x31,0xe6,0x31,0xe6,0x3a,0x06,0x32,0x06,0x32,0x06,0x29,0xe6,0x32,0xe8,0x54,0x0c,0x1b,0x68,0x03,0x66,0x03,0x05,0x02,0xe5,0x02,0xe5,0x13,0x07,0x33,0xea,0x13,0x46,0x03,0x26,0x1b,0xa8,0x85,0x51,0x9d,0x52,0x41,0xe6,0x5a,0x46,0x31,0xa5,0xb5,0xf4,0xd6,0xf9,0x54,0xce,0x5d,0x0f,0x2c,0x2a,0x03,0xa6,0x03,0xa6,0x03,0xc6,0x03,0xc6,0x03,0x66,0x03,0x46,0x03,0x46,0x03,0xa6,0x03,0xe7,0x03,0xe7,0x03,0xe7,0x03,0xc6,0x03,0xe7,0x03,0xe7,0x03,0xe7,0x0c,0x07
,0x0c,0x07,0x03,0xa6,0x03,0xc6,0x4c,0x8c,0x54,0x8c,0x13,0x05,0x3a,0x06,0x18,0xc2,0x19,0x01,0x33,0xa9,0x03,0x44,0x03,0x85,0x03,0xa6,0x03,0xa6,0x03,0xc6,0x03,0xc6,0x03,0xc6,0x03,0xa5,0x03,0xa6,0x13,0xa6,0x03,0xa5,0x3b,0xe9,0x8c,0x2e,0x52,0x88,0x7b,0xac,0x5a,0xc9,0x6b,0x6b,0x2a,0xe7,0x13,0x27,0x3b,0xea,0x23,0x68,0x3b,0x8a,0x8c,0x8f,0x63,0x6b,0x29,0x44,0x29,0x64,0x31,0xc6,0x31,0xe6,0x3a,0x07,0x3a,0x06,0x3a,0x06,0x31,0xc5,0x6b,0x6b,0x8c,0xcf,0x4c,0x2c,0x24,0x09,0x03,0x25,0x03,0x05,0x03,0x05,0x02,0xe5,0x02,0xe5,0x23,0xa8,0x23,0xc8,0x23,0xe9,0x85,0x30,0x95,0x52,0x41,0xc5,0x31,0x43,0x31,0xa4,0xad,0xd4,0xd6,0xd9,0x54,0xce,0x7d,0x51,0x3c,0x6b,0x03,0xa6,0x03,0xc6,0x03,0xc6,0x03,0xc6,0x03,0xc7,0x03,0x66,0x03,0x46,0x0b,0x26,0x03,0xa7,0x03,0xe6,0x03,0xe7,0x03,0xe7,0x03,0xe7,0x03,0xe7,0x03,0xe7,0x0c,0x07
,0x0c,0x08,0x03,0xe7,0x03,0xa6,0x65,0x0e,0x54,0x8b,0x23,0x47,0x21,0x43,0x4a,0x47,0x10,0xc1,0x53,0xeb,0x1b,0x26,0x23,0x88,0x64,0xac,0x4b,0xca,0x5c,0xad,0x03,0x04,0x03,0x65,0x03,0xe6,0x0b,0xc6,0x2c,0x29,0x03,0xa6,0x3c,0x09,0x8c,0x4e,0x52,0x88,0x83,0xed,0x63,0x0a,0x6b,0x4a,0x2a,0xc6,0x02,0xc4,0x02,0xe5,0x02,0xc5,0x43,0xeb,0xa5,0x32,0x84,0x2e,0x29,0xa5,0x42,0x27,0x31,0xa6,0x39,0xe6,0x3a,0x07,0x3a,0x27,0x3a,0x06,0x39,0xc5,0x8c,0x2e,0xa5,0x92,0x5c,0x4c,0x0b,0x05,0x03,0x25,0x03,0x25,0x03,0x25,0x03,0x06,0x03,0x05,0x3b,0xea,0x85,0x51,0x23,0xc9,0x7d,0x30,0x95,0x32,0x39,0xa5,0x41,0xe5,0x31,0xc5,0xad,0xb3,0xd6,0xb8,0x54,0xce,0x75,0x71,0x4c,0xcd,0x03,0xa6,0x03,0xc6,0x03,0xc6,0x03,0xc6,0x03,0xc6,0x03,0xc6,0x03,0x46,0x9e,0x14,0x2b,0xa8,0x03,0xa6,0x03,0xe7,0x03,0xe7,0x03,0xe7,0x03,0xe7,0x03,0xe7,0x0c,0x07
,0x04,0x08,0x03,0xe6,0x03,0xc6,0x03,0xa6,0x03,0x45,0x02,0xe5,0x11,0x02,0x21,0x02,0x10,0xa1,0x84,0xae,0x74,0x4d,0x74,0x8e,0x7c,0x4d,0x53,0x49,0x74,0xae,0x0a,0xe5,0x03,0x66,0x03,0xe6,0x44,0x6b,0x8c,0xb0,0x2c,0x2a,0x3c,0x0a,0x8c,0x4e,0x4a,0x27,0x6b,0x2b,0x5a,0xc9,0x63,0x2a,0x23,0x07,0x03,0x05,0x13,0x06,0x33,0xc9,0x4b,0xcb,0x8c,0x4f,0x6b,0x6c,0x31,0xc6,0x42,0x26,0x31,0xe6,0x3a,0x06,0x3a,0x06,0x3a,0x06,0x39,0xe6,0x31,0xa5,0x73,0x6b,0x8c,0xb0,0x43,0xcb,0x03,0x05,0x03,0x25,0x03,0x25,0x03,0x25,0x02,0xe5,0x03,0x05,0x34,0x0a,0x85,0x71,0x23,0xc8,0xa5,0xf3,0x8d,0x32,0x31,0xa5,0x62,0xe8,0x31,0xc5,0x9d,0x72,0xce,0xb7,0x44,0x8c,0x4c,0x8c,0x3c,0x6b,0x03,0xa6,0x03,0xa6,0x03,0xc6,0x03,0xc6,0x03,0xc6,0x03,0xe6,0x54,0xee,0xe7,0x3b,0xa6,0x55,0x0b,0x66,0x03,0xe7,0x03,0xe7,0x03,0xe7,0x04,0x07,0x03,0xe7,0x0c,0x07
,0x04,0x08,0x03,0xe6,0x03,0xc6,0x03,0xa6,0x03,0x65,0x0b,0x05,0x32,0x06,0x18,0xa1,0x11,0x02,0x33,0xa8,0x03,0x24,0x0b,0x85,0x24,0x08,0x24,0x29,0x1c,0x08,0x03,0xc6,0x3c,0x8b,0x6d,0x50,0x54,0x6c,0x8c,0xb0,0x43,0xca,0x43,0x89,0x8c,0x2e,0x4a,0x27,0x84,0x0e,0x5a,0xea,0x63,0x2a,0x22,0xc6,0x12,0xe6,0x64,0x6d,0x85,0x51,0x5c,0x6e,0x9d,0x32,0x7b,0xed,0x31,0xc6,0x3a,0x06,0x39,0xe6,0x31,0xe6,0x3a,0x06,0x42,0x07,0x42,0x27,0x31,0xc6,0x83,0xed,0xa5,0x73,0x54,0x4c,0x1b,0x87,0x03,0x25,0x03,0x25,0x03,0x05,0x02,0xe5,0x03,0x05,0x4c,0x8c,0x85,0x51,0x13,0x87,0x1b,0x67,0x1b,0x07,0x29,0xc6,0x39,0xc6,0x31,0xc6,0x33,0xa9,0x13,0x67,0x03,0x66,0x65,0x2f,0x3c,0x6b,0x03,0xa6,0x03,0xa6,0x03,0xc6,0x03,0xc6,0x03,0xc6,0x13,0xe8,0xc6,0xd8,0xe7,0x3b,0xd7,0x19,0x34,0x6b,0x04,0x07,0x04,0x06,0x04,0x06,0x04,0x06,0x03,0xe6,0x0c,0x07
,0x04,0x08,0x03,0xe7,0x03,0xc6,0x03,0xa6,0x03,0x45,0x02,0xe5,0x11,0x22,0x39,0xe4,0x10,0xa1,0x3b,0xa9,0x02,0xe5,0x0b,0x65,0x44,0x4a,0x3c,0x09,0x3c,0x4a,0x03,0xa6,0x0b,0xe7,0x0c,0x08,0x3c,0x8b,0x5c,0x2d,0x2b,0xe9,0x3b,0xca,0x94,0x6e,0x41,0xe6,0x31,0xc5,0x31,0xa5,0x63,0x0a,0x2a,0xe7,0x12,0xa5,0x8d,0x0f,0x5c,0x6d,0x3b,0xeb,0x94,0xd0,0x73,0xcd,0x31,0xe6,0x42,0x47,0x39,0xe6,0x39,0xe6,0x39,0xe6,0x42,0x27,0x31,0xc5,0x31,0xa5,0x7b,0xac,0x95,0x12,0x43,0xcb,0x0b,0x06,0x03,0x25,0x03,0x25,0x03,0x25,0x02,0xe5,0x03,0x05,0x1b,0x87,0x44,0x2b,0x1b,0xa8,0x03,0x05,0x1b,0x26,0x31,0xe6,0x39,0xe6,0x29,0xa5,0x13,0x06,0x03,0x26,0x0b,0x66,0x54,0xad,0x4c,0xcd,0x03,0xa6,0x03,0xa6,0x03,0xc6,0x03,0xc6,0x03,0xc6,0x6d,0x50,0xa6,0x75,0x54,0xad,0x34,0x2b,0x8d,0xf3,0x0c,0x07,0x03,0xe6,0x03,0xe6,0x03,0xe6,0x03,0xc6,0x0b,0xe7
,0x04,0x28,0x03,0xe7,0x03,0xc6,0x03,0xa5,0x03,0x45,0x02,0xe5,0x11,0x02,0x39,0xc5,0x10,0xa1,0x6c,0x6d,0x43,0x8a,0x64,0x2d,0x8c,0xaf,0x52,0xe8,0x84,0xcf,0x0a,0xe5,0x03,0xc6,0x03,0xe6,0x03,0xc6,0x0b,0xa6,0x03,0xc7,0x3c,0x4a,0x8c,0x8e,0x52,0x88,0x31,0x85,0x29,0x64,0x7b,0xab,0x22,0xc7,0x23,0x47,0x94,0xf0,0x6c,0x6d,0x43,0xca,0x9c,0xf1,0x73,0x8c,0x31,0xc5,0x42,0x06,0x39,0xc6,0x39,0xe6,0x42,0x27,0x3a,0x06,0x29,0xa5,0x29,0x84,0x7b,0x8c,0x95,0x32,0x4c,0x0c,0x03,0x25,0x03,0x25,0x03,0x25,0x03,0x05,0x02,0xe5,0x03,0x05,0x13,0x66,0x3c,0x4b,0x13,0x67,0x7d,0x51,0x64,0x4d,0x29,0xc5,0x42,0x26,0x31,0xa5,0x64,0x2c,0xae,0x35,0x3c,0x2b,0x3c,0x6c,0x3c,0x6c,0x03,0xa6,0x03,0xa6,0x03,0xc6,0x03,0xe6,0x24,0x4a,0xbe,0xb7,0x6d,0x50,0x3c,0x4b,0xb6,0x56,0xe7,0x3a,0x65,0x50,0x04,0x07,0x03,0xe7,0x03,0xe6,0x03,0xe6,0x04,0x07
,0x04,0x28,0x03,0xe7,0x03,0xe6,0x03,0xa6,0x03,0x65,0x03,0x05,0x29,0xc5,0x18,0xc2,0x18,0xe2,0x4c,0x0a,0x33,0xe8,0x3c,0x4a,0x44,0x6b,0x3c,0x2a,0x3c,0x6a,0x0b,0x05,0x03,0x45,0x03,0xe6,0x03,0xe6,0x03,0xc6,0x03,0xc6,0x13,0xc7,0x64,0x6c,0x9c,0xd0,0x7b,0x8c,0x8c,0x8f,0x84,0x4e,0x12,0xe5,0x13,0x06,0x9d,0x93,0x6c,0x8f,0x43,0xaa,0xa5,0x73,0x7c,0x0e,0x31,0xc5,0x31,0xe6,0x31,0xa5,0x31,0xc6,0x39,0xe6,0x39,0xe6,0x31,0x85,0x31,0x85,0x84,0x2e,0x9d,0x94,0x4c,0x2c,0x0b,0x26,0x03,0x05,0x03,0x25,0x03,0x25,0x02,0xe5,0x03,0x05,0x4c,0x8c,0x44,0x6c,0x23,0xa9,0x85,0x10,0x8d,0x11,0x29,0xa5,0x39,0x44,0x42,0x05,0x9d,0x52,0xce,0x98,0x54,0xad,0x4c,0xad,0x4c,0xcd,0x03,0xa6,0x03,0xa6,0x03,0xc6,0x03,0xc7,0x9e,0x34,0xdf,0x1a,0xd6,0xf9,0xdf,0x5a,0xce,0xd8,0xce,0xb8,0xc6,0xd8,0x14,0x08,0x03,0xe7,0x03,0xe6,0x03,0xe6,0x0c,0x07
,0x04,0x28,0x03,0xc6,0x03,0xc6,0x03,0xa6,0x03,0x65,0x03,0x05,0x19,0x42,0x31,0x83,0x10,0xc1,0x3b,0xa9,0x03,0x25,0x03,0x85,0x0b,0x86,0x0b,0x86,0x0b,0xc7,0x03,0x25,0x03,0x45,0x03,0xe6,0x03,0xe6,0x03,0xe6,0x03,0xe6,0x03,0xa6,0x23,0xe9,0x64,0xad,0xa5,0x93,0x8d,0x30,0x33,0xc9,0x34,0x4a,0x4b,0xeb,0x7d,0x30,0x54,0x6e,0x3b,0xec,0x4b,0xec,0x43,0x49,0x3a,0x47,0x42,0x47,0x3a,0x27,0x42,0x48,0x42,0x48,0x3a,0x27,0x42,0x48,0x32,0x06,0x1a,0x04,0x23,0x28,0x12,0xe6,0x33,0xe9,0x03,0x05,0x03,0x05,0x03,0x05,0x02,0xe5,0x03,0x05,0x3c,0x2a,0x4c,0x4b,0x2b,0xa9,0x7d,0x30,0x9d,0x92,0x31,0xe6,0x10,0x40,0x4a,0x68,0xad,0xb3,0xce,0xb8,0x54,0xcd,0x65,0x0e,0x44,0x8c,0x03,0xa6,0x03,0xc6,0x03,0xc6,0x14,0x08,0x96,0x14,0x96,0x14,0x9e,0x14,0x9e,0x14,0x9d,0xf4,0x9d,0xf4,0x7d,0xb2,0x1c,0x49,0x03,0xe6,0x03,0xe6,0x03,0xe6,0x0c,0x08
,0x04,0x07,0x03,0xe7,0x03,0xc6,0x03,0xa6,0x03,0x65,0x03,0x25,0x19,0x42,0x52,0x86,0x10,0xc2,0x7c,0x6e,0x43,0x8a,0x4b,0xaa,0xa5,0x72,0x6b,0xab,0x8d,0x51,0x02,0x84,0x03,0x45,0x04,0x06,0x03,0xe6,0x03,0xe6,0x03,0xe6,0x03,0xc6,0x03,0xa5,0x0b,0x45,0x13,0x26,0x0b,0x05,0x23,0xa7,0x34,0x0a,0x74,0xcf,0x6c,0xce,0x54,0x4d,0x54,0x4d,0x5c,0x2c,0x5b,0xec,0x5b,0xaa,0x8c,0x8f,0x6b,0xcc,0x84,0x6e,0x7c,0x6e,0x63,0x8b,0x84,0xaf,0x4b,0x8a,0x0a,0x65,0x7c,0xef,0x4c,0x4b,0x03,0x46,0x03,0x26,0x03,0x46,0x03,0x46,0x03,0x26,0x03,0x46,0x2c,0x09,0x33,0xc9,0x33,0x88,0x85,0x51,0x95,0x52,0x31,0xe5,0x62,0xc7,0x42,0x26,0xa5,0x73,0xd6,0xd8,0x54,0xcd,0x6d,0x2f,0x4c,0xcd,0x03,0xa7,0x03,0xc7,0x03,0xc7,0x03,0xe7,0x03,0xe7,0x03,0xe7,0x03,0xe7,0x03,0xa7,0x03,0x87,0x03,0x66,0x03,0xe8,0x03,0xc7,0x03,0xe6,0x03,0xe6,0x03,0xe6,0x0c,0x08
,0x04,0x07,0x03,0xe7,0x03,0xe7,0x03,0xc6,0x03,0x85,0x0b,0x66,0x29,0xe5,0x19,0x02,0x21,0x43,0x5c,0x8d,0x2c,0x2a,0x23,0xc8,0x64,0x8d,0x4b,0xca,0x54,0x6c,0x02,0xc4,0x03,0x24,0x03,0xe7,0x03,0xe7,0x03,0xe6,0x03,0xe6,0x03,0xc6,0x03,0xa6,0x03,0x65,0x02,0xa4,0x1a,0xc5,0x8c,0x8e,0x8c,0xef,0x94,0xf1,0x54,0x4c,0x6c,0xae,0xa5,0xb4,0xad,0xb4,0x74,0xf0,0x3b,0x4a,0x6c,0x0d,0x5b,0x8b,0x6c,0x2d,0x5b,0xab,0x5b,0x8b,0x6c,0x2d,0x43,0x48,0x13,0x26,0x94,0xd0,0x5c,0x2c,0x3c,0x6c,0x54,0xad,0x2c,0x0a,0x03,0x46,0x03,0x46,0x03,0x25,0x03,0x25,0x03,0x05,0x1b,0x47,0xa5,0xd4,0x9d,0x73,0x31,0xe6,0x4a,0x47,0x21,0x64,0x95,0x52,0xd6,0xd8,0x54,0xad,0x65,0x2f,0x54,0xee,0x03,0xc7,0x03,0xc7,0x03,0xc7,0x03,0xe7,0x65,0x70,0xa6,0x76,0xa6,0x76,0xae,0x76,0xa6,0x56,0xae,0x75,0xa6,0x55,0x65,0x90,0x03,0xe6,0x03,0xe6,0x03,0xe6,0x0c,0x08
,0x04,0x28,0x03,0xe7,0x03,0xe6,0x03,0xc6,0x03,0xa6,0x03,0x85,0x33,0xc9,0x33,0x67,0x33,0x88,0x1b,0xc7,0x03,0x85,0x0b,0xe7,0x0b,0xe7,0x03,0xe6,0x03,0xc6,0x03,0x45,0x02,0xa4,0x03,0x46,0x03,0x46,0x03,0x45,0x03,0x45,0x03,0x25,0x03,0x25,0x33,0xc9,0x43,0xaa,0x64,0x2d,0x7b,0xec,0x7c,0x4e,0xa5,0x31,0x54,0x8d,0x64,0x4c,0x6b,0xcc,0x74,0x0d,0x6c,0x4d,0x0a,0xc5,0x1b,0x27,0x12,0xe6,0x0a,0xe6,0x0a,0xc6,0x0a,0xa6,0x0a,0xe6,0x0a,0xe5,0x13,0x87,0x8d,0x31,0x64,0xae,0x1c,0x09,0x2c,0x29,0x0b,0xc7,0x03,0xc7,0x03,0xc7,0x03,0xa7,0x03,0xa7,0x03,0x67,0x03,0x26,0x4c,0x0c,0x54,0x4c,0x53,0x4a,0x42,0xa8,0x4a,0xe9,0x44,0x0b,0x44,0x2b,0x0b,0x67,0x0b,0x67,0x0b,0x67,0x03,0x86,0x03,0xa7,0x03,0xc7,0x1c,0x08,0x5d,0x4f,0x34,0x6b,0x44,0xad,0x44,0x8c,0x34,0x2b,0x23,0xc9,0x3c,0xac,0x03,0xe7,0x03,0xe6,0x03,0xe7,0x03,0xe7,0x14,0x08
,0x04,0x28,0x04,0x07,0x04,0x06,0x03,0xe6,0x03,0xa6,0x03,0x85,0x03,0x24,0x0b,0x05,0x03,0x05,0x23,0xc8,0x0b,0x86,0x44,0x6a,0x54,0xcc,0x1b,0xe7,0x03,0xa7,0x03,0x45,0x03,0x66,0x03,0x26,0x03,0x46,0x03,0x46,0x03,0x46,0x03,0x46,0x03,0x46,0x23,0xa8,0x3c,0x4c,0x4c,0x6d,0x9d,0xf4,0x64,0xce,0x6d,0x2f,0x33,0xca,0x75,0x10,0x9d,0xb3,0x9d,0x92,0x85,0x50,0x02,0xc5,0x13,0x26,0x13,0x06,0x0b,0x06,0x13,0x67,0x0b,0x46,0x03,0x26,0x03,0x05,0x0a,0xc5,0x43,0xca,0x23,0xc9,0x03,0xc7,0x03,0x46,0x03,0x46,0x03,0x46,0x03,0x25,0x03,0x25,0x03,0x05,0x03,0x26,0x03,0x26,0x02,0xc6,0x02,0xe5,0x1b,0x26,0x12,0xc5,0x1b,0x26,0x0b,0x05,0x03,0x05,0x03,0x26,0x03,0x26,0x03,0x26,0x03,0x46,0x03,0x26,0x03,0x66,0x7d,0xb1,0x44,0xed,0xa6,0x55,0xe7,0x3a,0xe7,0x3a,0x6d,0x30,0xae,0x15,0x8e,0x13,0x03,0xe7,0x03,0xe6,0x03,0xe7,0x03,0xe7,0x13,0xe8
,0x04,0x08,0x03,0xe7,0x03,0xe6,0x03,0xe6,0x03,0xa6,0x03,0x85,0x03,0x64,0x23,0xe9,0x23,0xa7,0x65,0x2f,0x03,0xa6,0x64,0xad,0x6c,0x0c,0x64,0x0c,0x74,0xcf,0x0b,0x06,0x03,0x05,0x03,0xa6,0x03,0xc6,0x03,0xc6,0x0c,0x28,0x1c,0x29,0x1c,0x09,0x24,0x49,0x24,0x29,0x24,0x29,0x2c,0x09,0x0b,0x26,0x3c,0x2b,0x54,0xcd,0x0b,0x46,0x43,0xea,0x3b,0xca,0x2b,0x89,0x3b,0xea,0x2b,0x88,0x4c,0x2b,0x3b,0xca,0x4c,0x8d,0x2b,0xa9,0x3b,0xeb,0x2b,0x68,0x7c,0xef,0x3b,0xa9,0x64,0x8d,0x75,0x30,0x75,0x30,0x03,0x87,0x2c,0x2a,0x6d,0x30,0x3c,0x6c,0x2b,0xe9,0x2c,0x2a,0x33,0xea,0x23,0x28,0x1a,0xc6,0x2b,0x69,0x23,0x07,0x23,0x47,0x13,0x26,0x03,0x05,0x03,0x25,0x03,0x25,0x03,0x25,0x03,0x25,0x03,0x66,0x1b,0xa8,0xce,0xf9,0xc6,0xd8,0x3c,0x8c,0xc6,0xd8,0xce,0xf9,0x4c,0x8d,0xd7,0x5a,0x2c,0x6b,0x14,0x28,0x03,0xe6,0x03,0xe7,0x03,0xe7,0x0b,0xe8
,0x04,0x08,0x03,0xc6,0x03,0xe6,0x03,0xe6,0x03,0xc6,0x03,0x85,0x03,0xc6,0x24,0x49,0x24,0x08,0x3c,0x8b,0x0b,0xc7,0x85,0x10,0x9c,0xcf,0x8c,0x8e,0x84,0xaf,0x12,0xc6,0x02,0xa4,0x03,0x05,0x03,0x65,0x03,0xc6,0x1c,0x28,0x9e,0x14,0x75,0x50,0x96,0x13,0x85,0xd2,0x85,0xf2,0x9d,0xf4,0x23,0xa9,0x7d,0x31,0x6c,0xcf,0x33,0xca,0x5c,0x4d,0x74,0xce,0x95,0xd2,0x85,0x51,0x6c,0xae,0x4c,0x2c,0x64,0x8d,0x7d,0x0f,0x6c,0xae,0x64,0xad,0x5c,0xcd,0x7d,0x71,0x4c,0x4c,0x54,0x6c,0x7d,0x2f,0xa5,0xf3,0x3c,0x4c,0x6d,0x2f,0x85,0x71,0x7d,0x71,0x7d,0x71,0x4c,0x2c,0x7d,0x30,0x7d,0x51,0x6c,0xae,0x8d,0x51,0x6c,0x8e,0x4c,0x0b,0x4c,0x4c,0x02,0xe5,0x02,0xe5,0x03,0x05,0x03,0x06,0x03,0x86,0x02,0xe5,0x75,0x10,0xd7,0x3a,0xd7,0x19,0x8e,0x33,0x55,0x0e,0x6c,0xef,0x9d,0xf4,0x9e,0x34,0x3c,0xac,0x9e,0x34,0x2c,0x6a,0x03,0xe6,0x03,0xe7,0x0b,0xe8
,0x04,0x08,0x03,0xe7,0x03,0xe6,0x04,0x06,0x03,0xe6,0x03,0xc6,0x03,0xc6,0x0b,0xe7,0x03,0xa6,0x0b,0xc6,0x54,0xcc,0x9d,0x92,0x74,0xce,0x43,0xaa,0x44,0x0a,0x53,0xcb,0x32,0x87,0x19,0xe4,0x4b,0x68,0x4c,0x0b,0x03,0x46,0x1c,0x09,0x44,0xac,0x7c,0xef,0x5c,0xad,0x14,0x29,0x14,0x29,0x24,0x09,0x2b,0xc9,0x24,0x0a,0x13,0x68,0x2b,0xa9,0x23,0x67,0x1b,0x46,0x13,0x46,0x1b,0x05,0x2b,0x88,0x2b,0xa8,0x1b,0x26,0x23,0x07,0x12,0xe5,0x1a,0xe6,0x2b,0x68,0x23,0x68,0x33,0xea,0x23,0x88,0x23,0xe9,0x03,0xe7,0x1c,0x48,0x4c,0xac,0x85,0x71,0x64,0x8d,0x7d,0x71,0x3c,0x6c,0x0b,0xa7,0x13,0x87,0x2c,0x09,0x13,0x87,0x2b,0xe9,0x13,0xc7,0x03,0x66,0x03,0x86,0x03,0x66,0x02,0xa5,0x02,0x84,0x03,0x86,0x03,0x05,0x0b,0x86,0x0b,0xa7,0x14,0x28,0x85,0xf2,0x3c,0x6b,0xd7,0x39,0x3c,0x8b,0x2c,0x6a,0x75,0x70,0x1c,0x29,0x03,0xe6,0x03,0xe7,0x13,0xe8
,0x04,0x08,0x03,0xe7,0x03,0xe6,0x03,0xe6,0x03,0xe6,0x03,0xc6,0x03,0xc6,0x03,0xa6,0x03,0xa6,0x03,0x65,0x5c,0x6c,0xad,0x92,0x54,0x6c,0x54,0x2c,0x0a,0xe5,0x4b,0xcb,0x32,0x05,0x21,0x84,0x42,0x67,0x74,0xaf,0x1b,0x87,0x95,0x50,0x84,0xcf,0xad,0x51,0x74,0x8d,0x65,0x4e,0x24,0x4a,0x75,0x0f,0x1b,0xe9,0x1b,0xa8,0x1b,0xc8,0x7c,0xf0,0x84,0xef,0x8c,0xcf,0x74,0xcf,0x03,0x24,0x03,0x65,0x0b,0x85,0x03,0x04,0x02,0xa4,0x53,0xeb,0x84,0xcf,0x84,0xcf,0x7c,0xcf,0x54,0xcc,0x6c,0xed,0x44,0xac,0x0b,0xe7,0x03,0xe6,0x4c,0x6c,0xc6,0x77,0x6c,0x2d,0xb5,0xd4,0x64,0xce,0x44,0x4b,0x54,0xad,0x03,0x86,0x03,0x65,0x03,0x85,0x03,0x85,0x03,0x85,0x03,0x66,0x02,0xa4,0x02,0xc5,0x02,0xc6,0x03,0x45,0x02,0xe5,0x03,0x46,0x03,0xa6,0x03,0xe6,0x0b,0xc7,0x0b,0x86,0x13,0xa7,0x03,0x25,0x03,0xe7,0x03,0xe7,0x03,0xc7,0x03,0xc7,0x03,0xe7,0x13,0xe8
,0x04,0x07,0x03,0xe6,0x03,0xe6,0x03,0xe6,0x03,0xc6,0x03,0xc6,0x03,0xc6,0x03,0xc6,0x03,0xa5,0x03,0xa5,0x4b,0xe9,0x8c,0x0b,0x74,0x4d,0x7c,0x4d,0x2b,0x68,0x0a,0x85,0x29,0xe5,0x29,0x64,0x52,0x87,0x74,0x4d,0x2b,0xe9,0x94,0x8e,0x84,0x8e,0xa4,0xcf,0x6c,0x2c,0x64,0xac,0x2b,0xe8,0x5c,0x8c,0x3c,0x0a,0x4c,0x8b,0x54,0xac,0x8d,0x30,0x84,0x2d,0x7b,0xec,0x7c,0xae,0x03,0x64,0x03,0x65,0x03,0x04,0x02,0x84,0x02,0x64,0x53,0xab,0x7c,0x0c,0x84,0x4e,0x74,0x2e,0x1b,0xc8,0x54,0xec,0x6d,0x70,0x4c,0xec,0x03,0xe7,0x3c,0x0b,0x64,0x2d,0x4b,0xcb,0x6c,0xce,0x34,0x6c,0x24,0x29,0x24,0x09,0x03,0x66,0x03,0x45,0x03,0x85,0x03,0x85,0x03,0x85,0x03,0x86,0x02,0xa4,0x02,0xa4,0x02,0xc5,0x03,0x66,0x02,0xe5,0x03,0x66,0x03,0xa6,0x03,0xe6,0x03,0xc6,0x03,0xa6,0x03,0x45,0x03,0x45,0x03,0x86,0x03,0x66,0x0b,0x25,0x03,0x66,0x03,0x86,0x13,0xe8
,0x04,0x07,0x03,0xc6,0x04,0x06,0x04,0x06,0x03,0xe6,0x03,0xc6,0x03,0xc6,0x03,0xc6,0x1b,0xe8,0x0b,0xc6,0x5c,0x4b,0x9d,0x10,0x84,0xae,0x94,0xaf,0x33,0xe9,0x8d,0x51,0x42,0x87,0x21,0x84,0x53,0x09,0x8d,0x72,0x5c,0x8c,0x8c,0xce,0x95,0x10,0x94,0xf0,0x64,0x6d,0x33,0xea,0x2b,0xc9,0x3b,0xa9,0x03,0x46,0x03,0x85,0x03,0x85,0x44,0x0a,0x7c,0xae,0x95,0x11,0xad,0x94,0x7d,0x0f,0x85,0x50,0x85,0x10,0x8d,0x11,0x84,0xf0,0xad,0xb4,0xa5,0x93,0x5c,0x0b,0x33,0xa9,0x13,0x06,0x65,0x0f,0x4c,0xee,0x44,0x4b,0x03,0x05,0x33,0x68,0xb5,0xf5,0x2b,0x89,0x03,0xa6,0x03,0xa6,0x03,0xa6,0x03,0x86,0x53,0xeb,0x74,0x6e,0x03,0x25,0x03,0x85,0x03,0x85,0x03,0x65,0x02,0xa4,0x02,0xc5,0x02,0xc5,0x03,0x66,0x02,0xe6,0x03,0x66,0x03,0xa6,0x03,0xc6,0x14,0x07,0x13,0xe7,0x03,0x65,0x03,0x45,0x03,0x45,0x02,0xe5,0x02,0xe5,0x03,0xa7,0x03,0x86,0x0b,0xe8
,0x0c,0x07,0x04,0x06,0x04,0x06,0x03,0xe6,0x5d,0x0e,0x3c,0xab,0x03,0xc5,0x03,0xa6,0x3c,0xab,0x2c,0x69,0x34,0x29,0x3b,0xa9,0x5c,0x8d,0x64,0xce,0x1b,0xe8,0x03,0x45,0x1a,0x84,0x23,0x07,0x1b,0x27,0x03,0x45,0x03,0x45,0x34,0x2a,0x2c,0x29,0x34,0x4a,0x34,0x6b,0x3c,0x6b,0x5c,0xad,0x3b,0xca,0x85,0x0f,0x7c,0xef,0x44,0x0a,0x7c,0xee,0xbd,0xb4,0x9c,0xb1,0x94,0x70,0x8c,0x2e,0x7b,0xcd,0x6b,0x2a,0x6b,0x2a,0x62,0xea,0x5a,0xc9,0x6b,0x4c,0x94,0xf0,0x4c,0x2c,0x74,0xef,0x8c,0xd0,0x7c,0xcf,0x8d,0x31,0x7d,0x10,0x64,0x4c,0xc6,0x15,0x54,0x6d,0x34,0x8b,0x34,0x6b,0x3c,0x4a,0x3c,0x4a,0x74,0x4d,0xa5,0x52,0x4c,0x2c,0x03,0x86,0x03,0x65,0x03,0x04,0x03,0x05,0x02,0xc4,0x0a,0xc5,0x03,0x46,0x8d,0xb2,0x75,0x0f,0x03,0xa6,0x03,0xc6,0x4c,0xcc,0x54,0xed,0x03,0xc6,0x03,0x65,0x03,0x66,0x03,0x46,0x02,0xc5,0x03,0xa7,0x03,0x66,0x0c,0x08
,0x04,0x07,0x04,0x06,0x04,0x06,0x03,0xe6,0x96,0x13,0x75,0x70,0x6c,0xee,0x6c,0xcd,0x6c,0xce,0x54,0x8c,0x5c,0x8c,0x4c,0x8b,0x34,0x6a,0x03,0x65,0x02,0xa4,0x02,0xe5,0x2b,0xe9,0x4c,0x2b,0x24,0x09,0x03,0x85,0x1b,0x86,0x1b,0x86,0x13,0xa6,0x03,0xa5,0x24,0x2a,0x64,0xce,0xad,0x31,0x8c,0x8e,0xdd,0xf0,0xc5,0x8f,0x84,0x8e,0x7b,0xec,0x31,0xa4,0x29,0x64,0x4a,0x47,0x3a,0x06,0x52,0x67,0x4a,0x47,0x52,0x88,0x42,0x06,0x42,0x07,0x21,0x23,0x39,0xc5,0xa5,0x52,0xa5,0x52,0x9c,0xd0,0x53,0x0a,0x9d,0x11,0xa5,0xd4,0x43,0xcb,0xad,0xb5,0x4c,0x2c,0x65,0x4f,0x03,0xc7,0x03,0xa6,0x03,0xa6,0x5c,0x0c,0x9d,0x52,0x3b,0xeb,0x13,0xc8,0x1b,0x68,0x03,0x45,0x03,0x05,0x02,0xc5,0x02,0xc5,0x03,0x65,0x74,0xef,0x74,0xee,0x6c,0xee,0x6c,0xed,0x6c,0xee,0x5c,0xac,0x6c,0xcd,0x54,0xac,0x2b,0xc9,0x03,0x87,0x02,0xe6,0x03,0xa7,0x03,0x86,0x0b,0xe8
,0x0c,0x07,0x34,0x6a,0x4c,0xcc,0x4c,0xcb,0x55,0x0d,0x0b,0xa6,0x9d,0x71,0xa4,0xcf,0x9d,0x51,0x5c,0x8c,0x7c,0x4c,0x54,0x2a,0x4c,0xac,0x44,0x8c,0x5c,0x4c,0x5c,0x6d,0x3c,0x2b,0x1b,0xc8,0x0b,0x86,0x03,0x45,0xa5,0x92,0xce,0x55,0x74,0xae,0x02,0xe5,0x3b,0xea,0x6c,0xae,0x7b,0xec,0x94,0x8d,0xe5,0x6b,0xdd,0x4b,0x84,0x0c,0x63,0x09,0x21,0x64,0x29,0x84,0x73,0x6c,0x4a,0x47,0x6b,0x8c,0x63,0x4a,0x6b,0x4b,0x5a,0xe9,0x63,0x0a,0x29,0x64,0x29,0x64,0x9d,0x11,0xa5,0xd4,0x7c,0x8e,0x5b,0xec,0x7c,0xcf,0xb6,0x15,0x1b,0x28,0x02,0xa6,0x1b,0xc9,0x85,0x91,0x24,0x4a,0x03,0xc6,0x03,0xc6,0x02,0xc6,0x02,0x85,0x3c,0x6b,0x4c,0x6b,0x5c,0xcd,0x03,0x25,0x03,0x86,0x3b,0xa9,0x54,0x4c,0x4c,0x6b,0x54,0x6c,0x2c,0x28,0x8c,0xaf,0x9c,0xed,0x84,0x6e,0x6c,0xed,0x9c,0x8d,0x7c,0xee,0x44,0x2b,0x44,0xab,0x64,0x8d,0x6d,0x2f,0x3c,0x8b,0x0c,0x08
,0x0c,0x07,0x3c,0x8b,0x55,0x0e,0x4c,0xed,0x55,0x0d,0x0b,0xc6,0x95,0x71,0xa4,0xcf,0x95,0x31,0x54,0x4b,0x8c,0x8e,0x5c,0x0a,0x4c,0xac,0x65,0x0d,0x5c,0x8d,0x6c,0xce,0x33,0xaa,0x03,0x66,0x03,0x64,0x0b,0x44,0xd5,0xad,0xe5,0x8b,0x94,0x8c,0x02,0x64,0x2b,0xa8,0x4b,0xcb,0x74,0x6d,0x94,0xcd,0xe5,0x6b,0xdd,0x4a,0x74,0x0b,0x6b,0x2a,0x31,0x84,0x29,0x64,0x42,0x06,0x41,0xe6,0x41,0xe6,0x39,0xc5,0x31,0x65,0x29,0x44,0x31,0x64,0x4a,0x26,0x8c,0x0e,0x94,0xf1,0x8c,0xf1,0xa5,0x11,0x63,0x4b,0xad,0x92,0xad,0xf4,0x5c,0x4c,0xad,0xf4,0x44,0x0b,0x75,0x70,0x0c,0x08,0x03,0xa7,0x03,0xc7,0x5c,0x4d,0x95,0x73,0x3c,0x2b,0x03,0x45,0x03,0x46,0x03,0xc6,0x03,0xc7,0x43,0xca,0x74,0xee,0x54,0x8c,0x54,0x6c,0x2c,0x29,0x84,0x8d,0xa4,0xae,0x7c,0x8e,0x74,0xee,0xa4,0xce,0x7c,0xee,0x44,0x4b,0x6d,0x2e,0x5c,0x6c,0x6d,0x0e,0x3c,0x6b,0x0c,0x08
,0x0c,0x28,0x03,0xc6,0x03,0xe6,0x04,0x06,0x03,0xe6,0x0b,0xc6,0x64,0x8d,0x4b,0x07,0x3b,0x48,0x23,0xc8,0x12,0x85,0x02,0xc5,0x44,0x8a,0x03,0xc5,0x03,0x24,0x03,0x85,0x02,0xa5,0x03,0x46,0x13,0x45,0x13,0x25,0xcd,0x4b,0xe5,0x09,0x94,0x6b,0x74,0x4d,0x7c,0xae,0x53,0xcb,0xa5,0x71,0x9c,0xce,0xdc,0xe9,0xcc,0xaa,0x4b,0x68,0x6b,0xab,0xa4,0xf1,0xa4,0xd1,0x94,0x70,0x94,0x4f,0x8c,0x4e,0x94,0x6f,0x9c,0x90,0x9c,0x90,0xad,0x12,0x9c,0xd0,0x94,0xf0,0x4c,0x0c,0x4b,0xcb,0x74,0x8e,0x53,0x8b,0x7c,0xaf,0x9d,0x93,0x4b,0xaa,0xc6,0x56,0x54,0x2c,0x24,0x4a,0x14,0x08,0x14,0x08,0x13,0xe8,0x74,0x6d,0xb5,0xf6,0x4c,0x4b,0x03,0x45,0x03,0x46,0x03,0xc7,0x03,0xc7,0x02,0xe5,0x02,0xe5,0x03,0x45,0x03,0x04,0x2c,0x49,0x54,0x0c,0x43,0x28,0x43,0x8a,0x1b,0xe8,0x1b,0x05,0x13,0x26,0x44,0x2a,0x03,0xa7,0x02,0xc5,0x03,0xa6,0x03,0x45,0x0c,0x07
,0x0c,0x08,0x1c,0x28,0x3c,0xcb,0x3c,0xcc,0x2c,0x8a,0x0b,0xc6,0x6c,0x6c,0x9c,0xad,0x63,0xeb,0x1a,0xc6,0x84,0x4d,0x4b,0x48,0x54,0x4b,0x24,0x49,0x44,0x8b,0x3c,0x2a,0x1b,0x88,0x44,0x4b,0x84,0xcf,0x7c,0x4d,0xcd,0x4c,0xdd,0x29,0x94,0x4a,0x6b,0xab,0x6b,0xcc,0x5b,0xcc,0x94,0x6e,0x84,0x6e,0xac,0x6c,0xa4,0x8c,0x3b,0xc9,0x12,0xc5,0x53,0x8a,0x6b,0xec,0x6c,0x0d,0x74,0x8e,0x95,0x11,0x9d,0x32,0x84,0xd0,0x9d,0x32,0x84,0x90,0x7c,0x6e,0x4b,0xaa,0x2b,0x68,0x0a,0xc6,0x6c,0x6d,0x6c,0x8e,0x5c,0x2d,0x7c,0xcf,0x64,0x2c,0xb6,0x15,0x6c,0xaf,0x5c,0xee,0x55,0x0d,0x2c,0x8a,0x2c,0x6b,0x6c,0x4d,0x95,0x74,0x23,0x68,0x03,0x45,0x03,0x46,0x03,0xc7,0x03,0xe7,0x33,0xca,0x23,0x67,0x1b,0xc7,0x02,0xe4,0x2c,0x28,0x5b,0xea,0x94,0x8d,0x4b,0xa9,0x33,0x67,0x94,0xad,0x63,0xeb,0x4c,0x8b,0x34,0x09,0x23,0x88,0x03,0xc7,0x03,0x85,0x0c,0x07
,0x0c,0x07,0x44,0xcc,0x5d,0x0d,0x6d,0x4f,0x4c,0xcb,0x0b,0xa5,0x7c,0xce,0xa4,0xaf,0x74,0x2d,0x2a,0xc6,0x8c,0x8e,0x53,0x8a,0x43,0xe9,0x64,0xed,0x6d,0x2f,0x6c,0xce,0x3b,0xca,0x64,0xcd,0x84,0x4d,0x7b,0xca,0xb4,0x6a,0xbb,0xa6,0x8b,0xea,0x73,0xcc,0x63,0xcc,0x6c,0x4c,0x7b,0xec,0x84,0xcf,0x6c,0x4e,0x74,0x8e,0x4c,0x4b,0x5c,0x0c,0x84,0x6e,0x94,0xcf,0x64,0x8d,0x4b,0x89,0x63,0xab,0x73,0xab,0x54,0x0b,0x73,0xab,0x7c,0x4f,0x94,0xce,0x84,0x2c,0x8d,0x31,0x7c,0xae,0x7c,0x2e,0x7c,0x4e,0x8c,0xef,0xa5,0x10,0x3c,0x4b,0x4c,0x0c,0x74,0xf0,0x7d,0x72,0x4c,0xef,0x03,0xc6,0x03,0xa7,0x03,0x05,0x02,0xa5,0x02,0xe5,0x03,0xa5,0x03,0x65,0x03,0xe6,0x03,0xc6,0x4c,0x0a,0x5c,0x8d,0x23,0xe7,0x03,0x04,0x24,0x08,0x6c,0x2b,0x94,0x2a,0x5c,0x2b,0x54,0x09,0x9c,0x8d,0x7c,0x8e,0x44,0x2a,0x4c,0x2a,0x4c,0x8b,0x0b,0xa6,0x03,0xa6,0x0c,0x08
,0x0c,0x27,0x03,0xe7,0x03,0xe6,0x03,0xc6,0x03,0xc5,0x0b,0xa5,0x3c,0x29,0x22,0xe5,0x0a,0xe4,0x03,0x05,0x1a,0x64,0x01,0xe3,0x44,0x09,0x03,0x05,0x03,0xa6,0x03,0x25,0x0b,0x06,0x4c,0x6b,0x6c,0x4d,0x63,0xeb,0x84,0x6d,0x5b,0x49,0x6c,0x0d,0x7c,0x0d,0x7c,0x6e,0x74,0xae,0x95,0x32,0x54,0x2c,0x23,0x28,0x23,0x68,0x02,0x64,0x3b,0x88,0x4b,0xea,0x4b,0xa9,0x23,0x27,0x02,0x84,0x43,0x09,0x4b,0x08,0x5c,0x0b,0x63,0x09,0x43,0x09,0x5c,0x2b,0x54,0x2c,0x5c,0x6d,0x6c,0x8f,0x63,0x8c,0x63,0x8b,0x8c,0x8e,0x7c,0x0c,0x44,0x4b,0xb5,0xd5,0x84,0xf1,0x9d,0x12,0x9d,0x94,0x33,0xc9,0x03,0x66,0x34,0x2a,0x34,0x2b,0x03,0xa6,0x02,0xa4,0x03,0xc6,0x03,0xe6,0x03,0x25,0x0b,0x05,0x02,0xc5,0x03,0x85,0x03,0x05,0x2c,0x49,0x2b,0x07,0x22,0xa5,0x02,0x44,0x02,0x44,0x1a,0x84,0x12,0xa5,0x3b,0xea,0x02,0xe4,0x03,0xa6,0x03,0x45,0x03,0xc7,0x0c,0x08
,0x0c,0x27,0x1c,0x48,0x24,0x69,0x1c,0x08,0x24,0x69,0x0b,0xa6,0x54,0xac,0x7c,0xac,0x4c,0x09,0x1b,0x25,0x74,0x2c,0x2a,0xc6,0x4c,0x2a,0x2b,0xa7,0x2c,0x49,0x23,0xc8,0x2b,0xc9,0x03,0x06,0x13,0x66,0x13,0x46,0x43,0xc9,0x5b,0xeb,0x3b,0xca,0x3c,0x2b,0x4c,0x8c,0x44,0x4c,0x64,0xaf,0x4c,0x4c,0x4c,0x8c,0x3c,0x0a,0x1b,0x67,0x5c,0x6d,0x8d,0x72,0x12,0xe6,0x02,0xa4,0x0a,0xa5,0x7c,0xaf,0x95,0x11,0x54,0x0c,0xa5,0x72,0x6c,0x6e,0x54,0x2b,0x54,0xce,0x5c,0x6d,0x6c,0xcf,0x9d,0x51,0x9d,0x51,0x9d,0x52,0x95,0x10,0x44,0x6c,0x6d,0x0f,0x5c,0x6d,0x74,0xf0,0x7d,0x11,0x5c,0x6d,0x03,0x47,0x4c,0x4c,0x4c,0x6d,0x03,0x45,0x02,0xe5,0x02,0xe5,0x03,0xc7,0x03,0x05,0x23,0xa8,0x1b,0x46,0x0b,0xc6,0x02,0xe4,0x2c,0x29,0x4b,0xaa,0x7c,0x4c,0x33,0x27,0x23,0x06,0x84,0x6c,0x43,0xa9,0x3b,0xca,0x2c,0x09,0x1b,0x87,0x03,0xc6,0x04,0x07,0x0c,0x08
,0x14,0x08,0x4c,0xcd,0x75,0x70,0x7d,0x70,0x65,0x4e,0x0b,0xa6,0x85,0x2f,0x9c,0x6c,0x84,0xee,0x33,0x88,0x94,0xae,0x53,0x49,0x64,0x2b,0x9d,0xb3,0x85,0x91,0x64,0xcf,0x4c,0x6d,0x02,0x84,0x02,0x84,0x02,0xa4,0x22,0xe8,0x43,0x09,0x2b,0x27,0x23,0x48,0x33,0x69,0x23,0x48,0x54,0x8c,0x3b,0xca,0x33,0xc9,0x3b,0xe9,0x03,0x05,0x13,0x46,0x33,0xa9,0x03,0x06,0x03,0x05,0x4c,0x0c,0x8d,0x30,0x8d,0x51,0x7c,0xaf,0x85,0x31,0x95,0x51,0x43,0xea,0x03,0x06,0x03,0x06,0x23,0x68,0x44,0x0c,0x5c,0xce,0x75,0x0f,0x95,0x92,0x2c,0x6a,0x2c,0x4a,0x34,0x4b,0x3c,0x6b,0x4c,0x8d,0x9e,0x13,0x44,0x2b,0x7d,0x90,0x65,0x4f,0x03,0xe6,0x03,0x46,0x0a,0xe5,0x03,0xc6,0x03,0x05,0x4c,0x0a,0x6d,0x2f,0x23,0x87,0x03,0x24,0x24,0x08,0x7c,0xad,0xa4,0x6b,0x64,0x6b,0x54,0x4a,0xac,0xcd,0x7c,0x8d,0x3b,0xc9,0x5c,0xac,0x65,0x4e,0x03,0xe7,0x03,0xe7,0x0c,0x08
,0x0c,0x28,0x13,0xe7,0x0c,0x08,0x0b,0xe8,0x0b,0xe7,0x0b,0xa5,0x44,0x4a,0x54,0x0a,0x23,0x87,0x0b,0x04,0x43,0x49,0x1a,0x66,0x4c,0x2a,0x13,0x45,0x0b,0xc7,0x13,0x66,0x0b,0x25,0x02,0xa5,0x02,0xc4,0x23,0x27,0x32,0xa8,0x3a,0x68,0x3a,0xa7,0x23,0x27,0x02,0xa5,0x02,0xa5,0x03,0x66,0x02,0xc5,0x1b,0x67,0x1b,0x67,0x02,0xe5,0x02,0xc5,0x4b,0xca,0x3b,0x68,0x3b,0xa8,0x53,0xcb,0x7c,0xf0,0x74,0xae,0x64,0x2c,0x7d,0x12,0x6c,0x8e,0x43,0x8a,0x3b,0xab,0x2b,0x29,0x43,0xaa,0x33,0x6a,0x33,0x69,0x64,0xce,0x44,0x8c,0x85,0x92,0x9d,0x52,0xad,0x93,0xad,0xb4,0x9d,0x72,0xad,0x72,0xad,0xb3,0xb6,0x14,0xa6,0x14,0x03,0xe7,0x03,0xa7,0x02,0xe5,0x03,0x46,0x03,0x05,0x13,0x26,0x0b,0xa7,0x02,0xe4,0x03,0x85,0x23,0x68,0x33,0x47,0x43,0x48,0x12,0x85,0x0a,0x84,0x43,0x27,0x22,0xc6,0x3b,0xca,0x13,0xa7,0x0b,0x66,0x03,0xe6,0x03,0xc7,0x0c,0x08
,0x0c,0x28,0x0b,0xe7,0x0c,0x07,0x0c,0x07,0x03,0xc6,0x0b,0xa6,0x4c,0x0a,0x6c,0x0a,0x33,0x47,0x12,0xe5,0x6c,0x2c,0x2a,0xa6,0x4c,0x2a,0x13,0x25,0x0b,0xc7,0x13,0x26,0x0b,0x66,0x02,0xa4,0x02,0xa4,0x33,0x48,0x29,0x85,0x41,0xe6,0x31,0x85,0x54,0x0c,0x2b,0x89,0x43,0xea,0x1b,0x67,0x02,0xc4,0x03,0x05,0x0b,0x05,0x02,0xe4,0x02,0x84,0x8c,0x8e,0x84,0x2b,0x8c,0x4c,0x73,0x89,0x84,0x6d,0x7c,0x2c,0x6b,0xcb,0x84,0xaf,0x6b,0xec,0x6b,0xed,0x74,0x8f,0x63,0xec,0x64,0x2e,0x6c,0x50,0x5b,0xad,0x6c,0x4e,0x75,0x90,0x54,0x8c,0x9d,0x51,0x9d,0x51,0xa5,0x52,0x95,0x72,0x5b,0x4b,0x74,0x4f,0x5b,0xeb,0x5c,0x6d,0x03,0xe7,0x03,0xc6,0x03,0xa6,0x03,0x05,0x03,0x05,0x13,0x26,0x0b,0xa6,0x0b,0x25,0x0b,0x45,0x2b,0x87,0x43,0x69,0x6b,0xea,0x1a,0xc6,0x1b,0x45,0x63,0xea,0x33,0x28,0x3b,0xca,0x13,0xa7,0x13,0x87,0x0b,0xe6,0x04,0x07,0x0c,0x07
,0x0c,0x08,0x5d,0x4d,0x5d,0x2d,0x44,0xeb,0x13,0xe6,0x0b,0xa5,0x8d,0x10,0xac,0xad,0x84,0x6d,0x3b,0x27,0x9c,0x8d,0x63,0xab,0x5c,0x0b,0x85,0x50,0x54,0x4b,0x75,0x70,0x02,0xe5,0x02,0x84,0x02,0xa4,0x2a,0xe7,0x29,0x64,0x6a,0xe8,0x31,0xa4,0x5c,0x0c,0x33,0x89,0x64,0x6d,0x23,0x88,0x03,0x04,0x33,0xe9,0x6c,0xce,0x2c,0x09,0x12,0xc6,0x73,0x6b,0x7b,0xcc,0x7b,0xed,0x63,0x6b,0x74,0x0e,0x6b,0xad,0x63,0x8c,0x6c,0x0f,0x5b,0x8d,0x5b,0x8d,0x6c,0x0f,0x5b,0x8c,0x63,0xad,0x73,0xed,0x63,0x6c,0x43,0x49,0x02,0xa4,0x23,0xa8,0x4c,0x2c,0x6c,0x8f,0x7d,0x31,0x85,0x72,0x94,0xaf,0xad,0xb3,0xb5,0xf5,0x9d,0xb3,0x4c,0xee,0x4c,0xcd,0x55,0x0e,0x03,0x25,0x03,0x05,0x5c,0x8d,0x6d,0x0e,0x7d,0x50,0x44,0x0a,0x24,0x08,0x7c,0x8d,0x9c,0x6c,0x63,0xeb,0x53,0x88,0x9c,0xac,0x84,0xce,0x43,0xea,0x75,0x4f,0x85,0xb0,0x4c,0xcc,0x03,0xe7,0x04,0x28
,0x0c,0x07,0x0c,0x27,0x1c,0x47,0x2c,0x49,0x13,0xe6,0x0b,0xa5,0x4c,0x0b,0x63,0xeb,0x33,0x27,0x0a,0x64,0x6c,0x0c,0x3b,0x49,0x4c,0x4b,0x13,0x45,0x2c,0x09,0x2b,0xc8,0x03,0xa6,0x03,0x05,0x02,0xa4,0x33,0x08,0x21,0x44,0x29,0x03,0x39,0xa4,0x5c,0x2c,0x43,0x89,0x5c,0x4d,0x23,0x88,0x02,0xe5,0x0b,0x05,0x6c,0x8e,0x64,0x2d,0x32,0x27,0x31,0xa5,0x29,0xa5,0x29,0x85,0x31,0xa5,0x29,0xa6,0x29,0xa6,0x29,0xa5,0x29,0xa5,0x29,0xa6,0x29,0xa5,0x29,0xa5,0x29,0xa5,0x31,0xa5,0x31,0xa5,0x31,0xa5,0x31,0xa5,0x53,0x6a,0x74,0xf0,0x33,0xaa,0x23,0xa9,0x54,0x8c,0x75,0x0f,0x64,0x6d,0x64,0x8e,0x4c,0x0c,0x5c,0x8d,0x1b,0x67,0x8d,0x71,0x75,0x30,0x03,0x05,0x03,0x05,0x13,0x26,0x13,0xe7,0x23,0x87,0x1b,0xa7,0x24,0x28,0x33,0x88,0x63,0xc9,0x22,0xa6,0x12,0xa4,0x5b,0xa9,0x33,0x28,0x3b,0xea,0x13,0xa7,0x1b,0xa8,0x1c,0x49,0x04,0x08,0x0c,0x08
,0x0c,0x07,0x03,0xe6,0x03,0xe6,0x03,0xc6,0x03,0xc6,0x03,0xa5,0x44,0x0a,0x43,0x28,0x1a,0xe7,0x02,0x85,0x53,0x8a,0x2b,0x48,0x44,0x6a,0x03,0xa6,0x02,0xe4,0x02,0xe4,0x03,0xa6,0x03,0x25,0x02,0xa4,0x3b,0x28,0x21,0x43,0x5a,0x67,0x31,0xa4,0x84,0x6f,0x95,0x30,0xad,0x72,0x64,0xae,0x02,0xc5,0x02,0xc5,0x6c,0x2d,0x6b,0xed,0x39,0xe6,0x21,0x64,0x29,0x64,0x29,0x85,0x29,0x65,0x29,0x64,0x29,0x85,0x29,0x85,0x29,0x85,0x29,0x85,0x29,0x65,0x29,0x85,0x29,0x85,0x29,0x85,0x21,0x64,0x29,0x64,0x29,0x85,0x63,0x4a,0x6c,0x2e,0x2b,0x88,0x13,0x47,0x4c,0x4b,0x44,0x0b,0x03,0x05,0x03,0x05,0x03,0x05,0x03,0x05,0x02,0xe5,0x6c,0x2d,0x64,0x4d,0x0b,0x05,0x03,0x06,0x0b,0x05,0x03,0xa6,0x02,0xe5,0x03,0x45,0x24,0x49,0x2b,0xa8,0x3b,0x27,0x0a,0x84,0x02,0x84,0x43,0x28,0x1a,0xc6,0x3b,0xca,0x03,0x65,0x03,0x45,0x03,0xc6,0x03,0xe7,0x0c,0x08
,0x0c,0x27,0x55,0x2e,0x5d,0x0d,0x3c,0xab,0x24,0x49,0x03,0xa5,0x85,0x0f,0x94,0x4c,0x7c,0x6d,0x3b,0x48,0x9c,0xaf,0x74,0x2d,0x54,0x2b,0x75,0x70,0x3c,0xab,0x44,0xcc,0x03,0xa6,0x54,0xad,0x5c,0x4c,0x3b,0x28,0x21,0x64,0x5a,0xc9,0x29,0x64,0x8c,0x8f,0x8c,0xae,0xa5,0x10,0x5c,0x0c,0x03,0x05,0x0b,0x05,0x7d,0x11,0x84,0x8f,0x42,0x27,0x29,0x64,0x21,0x64,0x29,0x85,0x29,0x85,0x29,0x85,0x29,0x85,0x29,0x64,0x29,0x65,0x29,0x85,0x29,0x65,0x29,0x64,0x29,0x85,0x29,0x85,0x19,0x03,0x21,0x44,0x29,0xa5,0x7b,0xcc,0x8d,0x33,0x3b,0xeb,0x03,0x05,0x2b,0xa8,0x23,0xa8,0x03,0x26,0x03,0x26,0x03,0x26,0x03,0x05,0x03,0x05,0x7c,0x8f,0x85,0x31,0x0b,0x05,0x03,0x05,0x64,0xad,0x5c,0xed,0x3b,0xea,0x4c,0x8b,0x4c,0xab,0x7c,0x8d,0x94,0x8d,0x5c,0x0b,0x4b,0xa9,0x9c,0x4a,0x7c,0xae,0x43,0xca,0x75,0x4f,0x44,0xac,0x44,0x8b,0x55,0x2e,0x14,0x08
,0x0c,0x27,0x1c,0x28,0x2c,0x4a,0x2c,0x4a,0x14,0x27,0x03,0xa5,0x5c,0x2b,0x7c,0x4c,0x43,0x89,0x12,0xa5,0x8c,0xae,0x5c,0x0c,0x4c,0x6b,0x1b,0xe8,0x34,0x6a,0x3c,0xab,0x03,0x46,0x33,0x88,0x23,0x67,0x43,0x69,0x21,0xc5,0x32,0x27,0x32,0x26,0x95,0x51,0x84,0xaf,0x84,0xf0,0x5c,0x6c,0x1b,0x67,0x3b,0xea,0x84,0xaf,0x7c,0x2d,0x3a,0x06,0x29,0x85,0x31,0xa5,0x39,0xe6,0x3a,0x06,0x3a,0x06,0x39,0xe6,0x39,0xc6,0x29,0x85,0x29,0x85,0x29,0x85,0x29,0x85,0x31,0xc5,0x29,0x85,0x29,0x85,0x29,0x85,0x29,0xa5,0x63,0x49,0x74,0x6f,0x2b,0x89,0x03,0x05,0x03,0x05,0x03,0x05,0x23,0x88,0x23,0xa9,0x03,0x06,0x02,0xe5,0x02,0xe5,0x44,0x0b,0x44,0x2c,0x03,0x06,0x0b,0x06,0x1b,0x88,0x2c,0x29,0x2b,0xc9,0x2b,0xe9,0x3c,0x8b,0x4b,0xa9,0x84,0x4d,0x33,0x27,0x1a,0xe6,0x74,0x0b,0x43,0x89,0x3b,0xca,0x23,0xc8,0x34,0x2a,0x34,0x8a,0x2c,0x8b,0x14,0x08
,0x0c,0x08,0x03,0xc5,0x03,0xe7,0x03,0xc6,0x03,0xc6,0x0b,0xa5,0x3c,0x0a,0x22,0xa6,0x0a,0x85,0x02,0xa5,0x1a,0xa5,0x0a,0x84,0x3c,0x4a,0x03,0xa5,0x03,0xa5,0x03,0x45,0x0a,0xc5,0x02,0xe4,0x02,0xe4,0x2b,0x48,0x43,0x49,0x43,0x49,0x3b,0x68,0x2b,0x88,0x1b,0x26,0x1b,0x46,0x0b,0x25,0x02,0xe5,0x0a,0xe5,0x7c,0xcf,0x8c,0xaf,0x42,0x07,0x29,0x85,0x3a,0x06,0x52,0xa8,0x42,0x47,0x4a,0x47,0x4a,0x47,0x4a,0x47,0x31,0xc5,0x31,0xa5,0x29,0x85,0x42,0x27,0x5a,0xc9,0x52,0x87,0x5a,0xc9,0x29,0x85,0x29,0xa5,0x6b,0x8b,0x7c,0xd0,0x4c,0x2c,0x13,0x67,0x02,0xe5,0x13,0x26,0xb5,0xd4,0xa5,0xb3,0x33,0x89,0x23,0x68,0x03,0x26,0x03,0x65,0x02,0xe5,0x03,0x05,0x03,0x05,0x03,0x05,0x03,0xa7,0x03,0x05,0x03,0x45,0x24,0x28,0x23,0xa8,0x22,0xa5,0x02,0x64,0x02,0x64,0x1a,0xa5,0x0a,0x84,0x3b,0xea,0x03,0x65,0x03,0x45,0x03,0xe6,0x03,0xc6,0x14,0x08
,0x0c,0x07,0x44,0xcb,0x44,0xed,0x34,0x8a,0x1c,0x07,0x03,0xa5,0x7c,0xae,0xa4,0xcd,0x7c,0x4c,0x2a,0xe7,0xa4,0xad,0x84,0xce,0x5c,0x4c,0x64,0xee,0x44,0x6b,0x64,0x8d,0x0a,0xe5,0x03,0x04,0x02,0xe4,0x1b,0x06,0x53,0xeb,0x53,0xec,0x2b,0x88,0x02,0xa4,0x02,0xc4,0x02,0xe5,0x03,0x05,0x02,0xe5,0x0a,0xe5,0x85,0x10,0x8c,0xaf,0x42,0x27,0x29,0xa5,0x4a,0x88,0x52,0xc9,0x4a,0x47,0x52,0x88,0x42,0x27,0x4a,0x47,0x42,0x27,0x4a,0x27,0x29,0x85,0x4a,0x68,0x4a,0x88,0x52,0xc9,0x42,0x27,0x29,0x85,0x29,0xa5,0x6b,0x8b,0x94,0xf1,0x3b,0xca,0x03,0x05,0x03,0x05,0x0b,0x06,0x74,0x4e,0x63,0xcc,0x8c,0xf0,0x8d,0x31,0x54,0x6c,0x0b,0x86,0x03,0x46,0x03,0x05,0x02,0xe5,0x44,0x2b,0x64,0xee,0x4c,0x4b,0x13,0x66,0x24,0x08,0x6c,0x2c,0x9c,0x8c,0x53,0xc9,0x43,0x68,0xac,0x8c,0x74,0x6d,0x3b,0xc9,0x5c,0xcc,0x3c,0x6a,0x34,0x6a,0x3c,0xcc,0x14,0x08
,0x0c,0x27,0x34,0x8b,0x3c,0xab,0x44,0xcb,0x24,0x48,0x03,0xa5,0x6c,0x8d,0x94,0xae,0x74,0x8d,0x1a,0xa5,0x94,0x8d,0x8c,0xaf,0x5c,0x0b,0x3b,0xaa,0x5c,0x8d,0x64,0xad,0x0b,0x05,0x02,0xe4,0x02,0xe4,0x13,0x05,0x54,0x2b,0x53,0xeb,0x23,0x47,0x02,0xc4,0x02,0xe4,0x02,0xe5,0x02,0xe5,0x02,0xe5,0x2b,0x89,0x74,0x4e,0x84,0x2e,0x3a,0x06,0x29,0x85,0x29,0xa5,0x31,0xa5,0x31,0xa5,0x39,0xe6,0x31,0xa5,0x31,0xa5,0x31,0xa5,0x31,0xa5,0x29,0x85,0x31,0xc6,0x39,0xe6,0x39,0xe6,0x29,0x85,0x29,0x85,0x29,0x84,0x63,0x29,0x74,0x4e,0x23,0x68,0x02,0xe5,0x03,0x05,0x13,0x46,0x9d,0x51,0x9d,0x32,0x84,0xb0,0x74,0x8e,0x7d,0x71,0x13,0xa7,0x03,0x66,0x03,0x06,0x02,0xe5,0x33,0xc9,0x44,0x8b,0x44,0x2a,0x23,0xa7,0x24,0x27,0x5c,0x0b,0x9c,0xce,0x43,0x68,0x33,0x27,0x9c,0x8c,0x5c,0x0b,0x3b,0xca,0x34,0x49,0x44,0x8b,0x3c,0xab,0x4c,0xcc,0x14,0x08
,0x0c,0x27,0x03,0xe7,0x03,0xe7,0x03,0xc6,0x03,0xc5,0x0b,0xa5,0x44,0x2a,0x12,0x86,0x0a,0xa5,0x02,0x84,0x12,0x43,0x3b,0x69,0x4b,0xca,0x02,0xa4,0x02,0xe4,0x03,0x05,0x02,0xe4,0x02,0xe4,0x02,0xc4,0x02,0xc4,0x02,0xa4,0x02,0xa4,0x02,0xa4,0x1b,0x07,0x23,0x47,0x0a,0xe6,0x03,0x05,0x02,0xe5,0x0a,0xe5,0x95,0x51,0x94,0xd0,0x42,0x48,0x29,0x85,0x29,0x85,0x29,0x85,0x29,0x85,0x29,0x85,0x29,0x85,0x29,0x85,0x29,0x85,0x29,0x85,0x29,0x85,0x29,0x85,0x29,0x85,0x29,0x85,0x29,0x85,0x21,0x64,0x29,0x64,0x7b,0xec,0x9d,0x72,0x54,0x6d,0x3c,0x2a,0x02,0xc5,0x0b,0x06,0x74,0xcf,0x74,0xef,0x84,0xf0,0x7c,0xf0,0x5c,0xae,0x0b,0x46,0x03,0x45,0x03,0x06,0x02,0xe5,0x03,0x05,0x03,0xa6,0x03,0x04,0x03,0x45,0x24,0x28,0x23,0xc7,0x0a,0x23,0x02,0x43,0x02,0x83,0x0a,0x43,0x0a,0x63,0x3b,0xca,0x03,0x86,0x03,0x46,0x03,0xe6,0x03,0xe7,0x14,0x07
,0x0c,0x07,0x34,0x6b,0x34,0x8b,0x24,0x49,0x1c,0x28,0x03,0xa5,0x6c,0x6c,0x9c,0xcf,0x64,0x2b,0x1a,0xc6,0x74,0x0b,0x74,0x8d,0x54,0x0b,0x43,0xea,0x3b,0xe9,0x34,0x09,0x03,0x04,0x02,0xe4,0x02,0xc4,0x03,0x04,0x03,0x04,0x13,0x47,0x23,0x47,0x84,0xaf,0x94,0xf1,0x23,0x68,0x02,0xa4,0x02,0xe5,0x02,0xe5,0x7c,0x6e,0x7c,0x0d,0x3a,0x07,0x29,0x85,0x29,0x85,0x29,0x85,0x29,0x85,0x29,0x85,0x29,0x85,0x29,0x85,0x29,0x85,0x29,0x85,0x29,0x85,0x29,0x85,0x29,0x85,0x29,0x85,0x29,0x64,0x29,0x85,0x29,0x85,0x63,0x09,0x7c,0x4e,0x2b,0x69,0x03,0x05,0x03,0x25,0x02,0xe5,0x5c,0x2d,0x33,0xca,0x23,0x88,0x5c,0x2c,0x54,0x0b,0x54,0x8d,0x23,0xe9,0x1b,0x68,0x03,0x05,0x33,0xc8,0x3c,0x8c,0x23,0xa8,0x0b,0x66,0x1c,0x08,0x5c,0x0a,0x9c,0xee,0x43,0x89,0x33,0x27,0x94,0xee,0x64,0x0c,0x3b,0xc9,0x44,0x6a,0x44,0x4a,0x2c,0x69,0x04,0x06,0x14,0x07
,0x04,0x07,0x4c,0xec,0x4c,0xcc,0x5d,0x2e,0x34,0xaa,0x03,0xa5,0x7c,0xce,0x9c,0x8e,0x7c,0xae,0x1a,0xc6,0x84,0x2c,0x7c,0xae,0x5c,0x2c,0x64,0xae,0x7d,0x50,0x64,0xee,0x03,0x05,0x02,0xe4,0x02,0xe4,0x03,0x24,0x0b,0x04,0x64,0x4d,0x8c,0xd0,0x63,0xac,0x4b,0x2a,0x2b,0x68,0x02,0xe4,0x1b,0x67,0x33,0xea,0x8d,0x11,0x94,0xd0,0x42,0x27,0x29,0x85,0x29,0x85,0x39,0xe6,0x31,0xe6,0x31,0xe6,0x31,0xe6,0x42,0x27,0x3a,0x07,0x3a,0x07,0x42,0x48,0x31,0xe6,0x31,0xe6,0x3a,0x27,0x29,0x85,0x29,0x65,0x29,0x85,0x73,0xac,0x9c,0xf0,0x33,0xca,0x03,0x25,0x03,0x25,0x0b,0x05,0x54,0x4d,0x2b,0xca,0x3b,0xea,0x7c,0x8e,0x6c,0x0c,0xa5,0xd4,0x7d,0x30,0x6d,0x10,0x0b,0x26,0x44,0x2b,0x5d,0x0e,0x5c,0x6c,0x23,0xc7,0x24,0x08,0x6c,0x2c,0x9c,0xad,0x54,0x0a,0x43,0x67,0x9c,0xcd,0x74,0x8e,0x3b,0xea,0x4c,0x8b,0x6d,0x2e,0x4d,0x0d,0x04,0x07,0x14,0x28
,0x0c,0x07,0x03,0xc6,0x03,0xe6,0x03,0xc6,0x03,0xc5,0x03,0xa5,0x44,0x0a,0x22,0xc6,0x12,0xc6,0x02,0x64,0x12,0x44,0x33,0x48,0x54,0x2b,0x03,0x05,0x03,0x05,0x02,0xe4,0x03,0x04,0x03,0x04,0x03,0xa5,0x02,0xe4,0x02,0xe5,0x53,0x8a,0x6b,0xec,0x9d,0x11,0x7c,0xb0,0x2b,0x88,0x03,0x05,0x02,0xe5,0x0a,0xc5,0x84,0xd0,0x84,0x6e,0x3a,0x27,0x29,0x85,0x29,0x85,0x31,0xe6,0x31,0xe6,0x42,0x27,0x3a,0x07,0x39,0xe6,0x31,0xe6,0x42,0x68,0x42,0x48,0x39,0xe6,0x31,0xc6,0x3a,0x27,0x29,0x85,0x29,0x85,0x29,0x85,0x63,0x4a,0x94,0xaf,0x4c,0x0b,0x1b,0x67,0x03,0x25,0x03,0x05,0x4c,0x6c,0x1b,0x67,0x0b,0x26,0x2b,0xc9,0x2b,0xe9,0x1b,0xa8,0x03,0x25,0x02,0xe5,0x03,0x25,0x02,0xe5,0x03,0xc6,0x03,0x05,0x03,0x45,0x24,0x28,0x23,0x89,0x22,0xa5,0x02,0x64,0x02,0x64,0x1a,0xa5,0x12,0x85,0x33,0xea,0x03,0x66,0x03,0x45,0x03,0xc6,0x03,0xe6,0x14,0x07
,0x04,0x07,0x24,0x49,0x1c,0x48,0x1c,0x29,0x0c,0x07,0x03,0xa5,0x5c,0x2b,0x84,0x4c,0x4b,0x8a,0x0a,0x64,0x5b,0x8a,0x43,0x49,0x5b,0xeb,0x33,0xc8,0x1b,0x67,0x23,0x67,0x0a,0xe4,0x03,0xa5,0x03,0x25,0x02,0xa4,0x02,0xc5,0x6c,0x8d,0x7c,0xaf,0x8d,0x0f,0x74,0x8e,0x2b,0xa8,0x02,0xe5,0x03,0x05,0x03,0x05,0x6c,0x4d,0x84,0x4e,0x3a,0x07,0x29,0xa5,0x29,0x85,0x31,0xa5,0x29,0xa5,0x39,0xe6,0x31,0xc6,0x31,0xa5,0x31,0xe6,0x31,0xe6,0x31,0xc6,0x31,0xe6,0x31,0xe6,0x39,0xe6,0x29,0x85,0x29,0x85,0x29,0x85,0x63,0x4a,0x8c,0x4e,0x2b,0x68,0x03,0x05,0x03,0x25,0x03,0x25,0x03,0x25,0x03,0x25,0x03,0x05,0x03,0x05,0x03,0x25,0x03,0x45,0x03,0x25,0x03,0x05,0x03,0x25,0x2b,0xa8,0x34,0x49,0x23,0xa8,0x0b,0x66,0x24,0x08,0x4b,0xca,0x8c,0x6c,0x33,0x07,0x22,0xe6,0x84,0x4b,0x4b,0xa9,0x3b,0xca,0x2c,0x09,0x2c,0x09,0x1c,0x49,0x03,0xe6,0x14,0x08
,0x04,0x27,0x55,0x0d,0x6d,0x4e,0x65,0x2e,0x34,0x69,0x0b,0xa5,0x8d,0x0f,0x9c,0x4c,0x84,0xae,0x12,0xa5,0x84,0x2c,0x6c,0x2c,0x64,0x2c,0x6c,0xce,0x8d,0x91,0x95,0xb2,0x03,0x05,0x03,0x25,0x02,0xe4,0x02,0xc4,0x2b,0xa8,0x8d,0x30,0x95,0x92,0x85,0x70,0x7c,0xae,0x54,0x4c,0x02,0xe5,0x03,0x05,0x1b,0x67,0x8d,0x31,0x94,0xb0,0x42,0x47,0x29,0x85,0x29,0x85,0x29,0x85,0x29,0x85,0x29,0x85,0x29,0x85,0x29,0x85,0x29,0x85,0x29,0x85,0x29,0x85,0x29,0x85,0x29,0x85,0x29,0x85,0x29,0x85,0x29,0x85,0x29,0xa5,0x73,0xcc,0x9d,0x11,0x3c,0x0a,0x03,0x26,0x03,0x25,0x03,0x25,0x03,0x25,0x03,0x05,0x0b,0x25,0x02,0xa4,0x02,0xe5,0x03,0x45,0x03,0x25,0x03,0x06,0x03,0x05,0x5c,0x8c,0x6d,0x0e,0x43,0xea,0x1b,0xa7,0x24,0x08,0x7c,0x8d,0xa4,0x6b,0x64,0x0b,0x4b,0xa9,0x94,0x2b,0x84,0x8e,0x43,0xca,0x64,0xed,0x65,0x2e,0x55,0x2d,0x04,0x07,0x14,0x08
,0x04,0x27,0x04,0x07,0x04,0x07,0x0b,0xe7,0x0b,0xc6,0x03,0xa5,0x44,0x0a,0x4b,0x8a,0x23,0x67,0x02,0x84,0x22,0xc6,0x22,0xc7,0x54,0x0b,0x0b,0x05,0x0b,0x05,0x0b,0x05,0x02,0xa4,0x02,0xc5,0x02,0xc5,0x03,0x04,0x03,0x05,0x13,0x26,0x0a,0xe5,0x0b,0x05,0x13,0x26,0x0b,0x06,0x02,0xe5,0x03,0x05,0x1b,0x47,0x6c,0x0d,0x73,0xcc,0x3a,0x06,0x29,0xa5,0x29,0x85,0x29,0x85,0x29,0x85,0x29,0x85,0x29,0x85,0x29,0xa5,0x29,0x85,0x29,0x85,0x29,0x85,0x29,0x85,0x29,0x85,0x29,0x85,0x29,0x85,0x29,0x85,0x29,0xa5,0x5a,0xe9,0x7c,0x2d,0x43,0xca,0x33,0xea,0x03,0x25,0x03,0x05,0x02,0xe5,0x02,0xe5,0x02,0xe5,0x02,0xe5,0x03,0x04,0x03,0x45,0x03,0x05,0x03,0x05,0x03,0x05,0x02,0xe5,0x0b,0xc7,0x13,0x26,0x03,0x66,0x24,0x29,0x2b,0x88,0x3b,0x47,0x12,0x65,0x0a,0x84,0x3b,0x67,0x1a,0xc6,0x3b,0xea,0x0b,0x85,0x13,0x87,0x14,0x07,0x03,0xe7,0x14,0x08
,0x04,0x07,0x0b,0xe7,0x0b,0xe7,0x0b,0xe7,0x0b,0xc6,0x03,0xa6,0x4c,0x0b,0x63,0xeb,0x33,0x27,0x0a,0xa5,0x64,0x0c,0x43,0x49,0x54,0x2b,0x13,0x26,0x0b,0x05,0x13,0x25,0x03,0x04,0x02,0xe5,0x03,0x04,0x03,0x04,0x02,0xe5,0x03,0x04,0x03,0x04,0x03,0x04,0x03,0x04,0x02,0xe4,0x03,0x04,0x0b,0x05,0x0b,0x06,0x85,0x10,0x8c,0xaf,0x42,0x68,0x29,0x85,0x29,0x85,0x29,0x85,0x29,0x85,0x29,0x85,0x29,0x85,0x29,0x85,0x29,0x85,0x29,0x85,0x29,0x85,0x29,0x85,0x29,0x85,0x29,0x85,0x29,0x85,0x29,0x85,0x29,0xa5,0x73,0xcc,0x9d,0x11,0x3b,0xca,0x03,0x05,0x03,0x05,0x02,0xe5,0x02,0xe5,0x02,0xe5,0x02,0xe4,0x03,0x05,0x02,0xe5,0x03,0x25,0x03,0x05,0x02,0xe5,0x03,0x05,0x13,0x26,0x13,0xc7,0x13,0x46,0x03,0x65,0x24,0x28,0x3b,0xa9,0x6b,0xeb,0x22,0xe6,0x12,0xa5,0x64,0x0b,0x3b,0x49,0x3b,0xca,0x13,0xa6,0x13,0x86,0x0b,0xe6,0x03,0xe7,0x0c,0x08
,0x04,0x07,0x65,0x2d,0x65,0x4e,0x44,0xcc,0x2c,0x8a,0x03,0xc6,0x95,0x30,0xa4,0x6b,0x84,0xae,0x2b,0x48,0x8c,0x2d,0x7c,0x8e,0x64,0x2b,0x7d,0x30,0x8d,0xb2,0x8d,0x71,0x0a,0xe5,0x03,0x05,0x03,0x04,0x02,0xe5,0x02,0xe5,0x02,0xe5,0x02,0xe4,0x02,0xe4,0x02,0xe4,0x0b,0x04,0x03,0x04,0x03,0x05,0x0a,0xc5,0x6c,0x4e,0x7c,0x0d,0x3a,0x27,0x29,0x85,0x29,0x85,0x29,0x85,0x29,0x85,0x29,0x85,0x29,0x85,0x29,0x85,0x29,0x85,0x29,0x85,0x29,0x85,0x29,0x85,0x29,0x85,0x29,0x85,0x29,0x85,0x29,0x85,0x29,0xa5,0x63,0x4a,0x7c,0x4d,0x2b,0x68,0x02,0xe5,0x02,0xe5,0x0a,0xe5,0x02,0xe5,0x02,0xe5,0x03,0x05,0x02,0xe5,0x03,0x45,0x03,0x05,0x02,0xe5,0x02,0xc5,0x03,0x05,0x64,0x8c,0x6d,0x2f,0x54,0x6c,0x2b,0xe8,0x1c,0x07,0x7c,0x6c,0x9c,0x6b,0x64,0x2b,0x53,0xa9,0x9c,0x6c,0x7c,0xce,0x43,0xca,0x75,0x4e,0x65,0x0e,0x3c,0xab,0x03,0xe7,0x0c,0x08
,0x04,0x07,0x13,0xe7,0x13,0xe7,0x1c,0x28,0x03,0xc5,0x03,0xa5,0x4c,0x0b,0x6c,0x0b,0x3b,0xa9,0x0a,0x85,0x53,0xeb,0x2b,0x28,0x4c,0x0b,0x13,0x46,0x1b,0x67,0x2b,0xc9,0x0a,0xe5,0x03,0x05,0x02,0xe4,0x02,0xe5,0x02,0xc4,0x02,0xc4,0x0a,0xa4,0x33,0x48,0x3b,0xa9,0x13,0x05,0x02,0xc4,0x23,0x47,0x33,0xa9,0x5c,0x6d,0x53,0xcb,0x32,0x25,0x31,0xc5,0x31,0xa6,0x31,0xa5,0x31,0xa5,0x31,0xa5,0x31,0xa5,0x31,0xc6,0x31,0xc6,0x31,0xa6,0x31,0xa6,0x31,0xa6,0x31,0xc6,0x31,0xc6,0x29,0xa6,0x29,0xa6,0x29,0xc6,0x5b,0x8a,0x5c,0x4d,0x1b,0x68,0x02,0xc4,0x02,0xe5,0x02,0xc5,0x02,0xa4,0x02,0xa4,0x02,0xa4,0x03,0x25,0x03,0x24,0x03,0x65,0x02,0xe5,0x0a,0xe5,0x0b,0x05,0x13,0x26,0x24,0x08,0x23,0x88,0x0b,0x66,0x24,0x08,0x3b,0xa9,0x63,0xeb,0x1a,0xc6,0x12,0xa5,0x5b,0xaa,0x33,0x48,0x3b,0xea,0x0b,0xa6,0x24,0x09,0x1c,0x8a,0x03,0xe7,0x14,0x08
,0x0c,0x07,0x03,0xc6,0x03,0xe6,0x03,0xc6,0x03,0xc5,0x03,0xa5,0x43,0xe9,0x4b,0x68,0x1a,0xa5,0x02,0x84,0x3b,0x48,0x22,0xc6,0x4b,0xeb,0x02,0xe5,0x02,0xe5,0x02,0xe5,0x02,0xe5,0x0a,0xe5,0x02,0xe5,0x02,0xc4,0x02,0xc4,0x13,0x06,0x1a,0x64,0x3b,0x07,0x3b,0x27,0x22,0xc5,0x1a,0xc5,0x0a,0xc3,0x23,0x27,0x4c,0x2c,0x0b,0x66,0x23,0x06,0x73,0xcc,0x73,0xac,0x7b,0xcd,0x63,0x6b,0x73,0xed,0x6b,0xcd,0x5b,0x6c,0x74,0x0e,0x63,0xad,0x5b,0x8c,0x6c,0x0e,0x63,0x8c,0x63,0x8c,0x73,0xcd,0x6b,0x6b,0x43,0x0a,0x1a,0xa5,0x12,0xa5,0x23,0x48,0x02,0xa4,0x02,0x84,0x02,0xa4,0x03,0x25,0x03,0x25,0x13,0x67,0x13,0x66,0x03,0x86,0x03,0xa6,0x02,0xe5,0x03,0x87,0x02,0xe5,0x02,0xc4,0x0b,0x87,0x02,0xe5,0x03,0x45,0x1c,0x28,0x2b,0xa8,0x43,0x48,0x12,0x85,0x0a,0x85,0x3b,0x67,0x1a,0xe5,0x3b,0xea,0x0b,0x66,0x03,0x45,0x03,0xc7,0x03,0xc6,0x0c,0x08
,0x0c,0x07,0x55,0x0d,0x54,0xed,0x4c,0xec,0x1c,0x08,0x0b,0xa5,0x84,0xee,0xa4,0x8c,0x7c,0x8d,0x33,0x28,0xa5,0x32,0x74,0x8e,0x5c,0x0c,0x85,0x50,0x4c,0x2b,0x6c,0xef,0x02,0xe5,0x02,0xe5,0x02,0xe4,0x02,0xe4,0x12,0xe6,0xa5,0x51,0xd5,0x8c,0xd5,0x8b,0xd5,0x6b,0xbc,0xcc,0x95,0x11,0x43,0xe9,0x64,0x4c,0x84,0xaf,0x1b,0xc8,0x02,0xe5,0x74,0x2e,0x6c,0x0c,0x74,0x0d,0x5b,0x8c,0x6c,0x2f,0x5c,0x0d,0x4b,0xac,0x6c,0x6f,0x4b,0xac,0x53,0xcc,0x6c,0x4f,0x5b,0xac,0x63,0xec,0x6c,0x2e,0x63,0x8a,0x5c,0x2c,0x03,0x05,0x74,0xef,0x95,0x71,0x44,0x2b,0x5c,0xad,0x34,0x2a,0x03,0x05,0x02,0xc4,0x54,0x2b,0x7d,0x30,0x34,0x6b,0x03,0x66,0x02,0xc4,0x03,0x86,0x03,0x05,0x54,0x6c,0x75,0x50,0x7d,0x30,0x33,0xe9,0x23,0xe8,0x7c,0x6c,0xa4,0x6b,0x64,0x2b,0x4b,0x89,0x94,0x4c,0x7c,0x8d,0x43,0xea,0x6d,0x4e,0x85,0x90,0x6d,0x6f,0x03,0xc7,0x0b,0xe7
,0x0c,0x27,0x1c,0x48,0x24,0x69,0x24,0x6a,0x14,0x08,0x03,0xa5,0x5c,0x4b,0x8c,0x8d,0x5c,0x2b,0x12,0xa5,0x74,0x2d,0x2b,0x08,0x4b,0xeb,0x23,0x47,0x3b,0xea,0x33,0xea,0x02,0xe5,0x02,0xe5,0x02,0xe4,0x02,0xc4,0x1a,0xe5,0xbd,0xb3,0xed,0x8a,0xe5,0x29,0xe5,0x2a,0xc4,0x4a,0x84,0xaf,0x75,0x0f,0x64,0x2c,0x8c,0xae,0x23,0x47,0x02,0xa4,0x33,0x49,0x33,0xaa,0x43,0xca,0x2b,0x49,0x3b,0xca,0x3b,0xa9,0x23,0x49,0x33,0xa9,0x23,0x28,0x23,0x29,0x33,0x6a,0x33,0x28,0x3b,0xaa,0x33,0x49,0x2b,0x48,0x23,0x68,0x03,0x25,0x6c,0x4c,0x84,0x6e,0x23,0x87,0x1b,0x47,0x13,0x46,0x03,0x66,0x4b,0xea,0x6c,0x0c,0x7c,0x4e,0x3b,0x8a,0x02,0xa5,0x03,0x45,0x03,0x66,0x03,0x05,0x1b,0x67,0x2c,0x0a,0x44,0x8b,0x1b,0xc8,0x23,0xe7,0x4b,0xca,0x84,0x6d,0x33,0x27,0x22,0xe6,0x74,0x4c,0x4b,0x8a,0x3b,0xea,0x1b,0xc7,0x44,0x6a,0x2c,0x69,0x03,0xe7,0x0c,0x08
,0x0c,0x07,0x03,0xe6,0x03,0xe6,0x03,0xe6,0x03,0xc5,0x0b,0xa5,0x3c,0x0a,0x22,0xa5,0x0a,0x84,0x02,0x84,0x1a,0xc5,0x0a,0x85,0x4c,0x0b,0x02,0xc4,0x03,0x05,0x02,0xe5,0x02,0xe5,0x0a,0xe5,0x02,0xe5,0x02,0xe4,0x12,0xc5,0x74,0xad,0x94,0x6a,0x94,0x49,0x8c,0x28,0x7b,0xa9,0x64,0x4c,0x2c,0x08,0x33,0xe9,0x5c,0x0c,0x33,0x88,0x54,0x2c,0x0b,0x05,0x03,0x05,0x1b,0x67,0x13,0x26,0x03,0x05,0x23,0x88,0x1b,0x68,0x02,0xe5,0x13,0x06,0x1b,0x26,0x02,0xc4,0x1b,0x47,0x33,0xc9,0x02,0xa5,0x23,0x87,0x3c,0x29,0x1b,0x46,0x54,0x0b,0x6c,0x4c,0x03,0x24,0x23,0x88,0x33,0xc9,0x23,0xc8,0x4b,0xca,0x63,0xcc,0x6b,0xec,0x3b,0x89,0x03,0x46,0x03,0x65,0x02,0xc5,0x02,0xe5,0x02,0xc5,0x03,0x65,0x03,0xa6,0x03,0x25,0x24,0x28,0x2b,0xa8,0x22,0xa5,0x02,0x63,0x02,0x64,0x22,0xa5,0x12,0x64,0x43,0xca,0x03,0x66,0x03,0x45,0x03,0xe6,0x03,0xe7,0x0c,0x07
,0x04,0x27,0x4c,0xac,0x65,0x2e,0x3c,0xcb,0x0b,0xe6,0x0b,0xa5,0x7c,0xae,0x9c,0x8d,0x74,0x6c,0x1a,0xc6,0x94,0xaf,0x6c,0x4d,0x5c,0x2b,0x74,0xee,0x7d,0x30,0x64,0xee,0x02,0xe5,0x02,0xe5,0x02,0xe5,0x2b,0x68,0x3b,0xea,0x33,0xa9,0x3b,0x27,0x3a,0x65,0x2a,0x04,0x4b,0x29,0x2b,0x47,0x5c,0xad,0x43,0xeb,0x0a,0xa4,0x2b,0x68,0x44,0x0b,0x03,0x05,0x0a,0xe5,0x03,0x05,0x03,0x05,0x2b,0xc8,0x2b,0xa9,0x3c,0x0b,0x9d,0x52,0x5b,0xac,0x8d,0x11,0x44,0x0b,0x0a,0xe5,0x0b,0x05,0x0a,0xe5,0x5c,0x6d,0x64,0x8d,0x74,0x8d,0x33,0x46,0x33,0x46,0x23,0xa8,0x3b,0xaa,0x5c,0x4d,0x2b,0x68,0x0a,0x84,0x0a,0xa5,0x0b,0x46,0x03,0x66,0x03,0x46,0x02,0xc4,0x02,0xc4,0x6c,0xee,0x4c,0x4b,0x5c,0xcd,0x44,0x6a,0x5c,0xcb,0x64,0xed,0x74,0x6c,0xa4,0xad,0x5c,0x0a,0x43,0x68,0x9c,0xad,0x7c,0xcf,0x4c,0x4b,0x44,0x8a,0x54,0xac,0x44,0xcb,0x24,0x69,0x0c,0x08
,0x0c,0x08,0x34,0x6b,0x44,0xac,0x44,0xec,0x14,0x07,0x0b,0xa6,0x6c,0x6d,0x9c,0xae,0x6c,0x8d,0x12,0x85,0x74,0x2c,0x43,0x89,0x54,0x2b,0x44,0x09,0x75,0x2f,0x5c,0xad,0x03,0x04,0x03,0x05,0x03,0x04,0x23,0x67,0x43,0xca,0x3b,0x68,0x64,0x0c,0x7b,0xaa,0x62,0xc7,0x74,0x0d,0x3a,0xe7,0x7c,0x2d,0x63,0xcb,0x02,0x63,0x1b,0x47,0x33,0xa8,0x0a,0xe5,0x7d,0x30,0x0b,0x26,0x03,0x25,0x54,0x8d,0x5c,0xae,0x64,0xce,0x7c,0x6e,0x4a,0xe8,0x84,0x8f,0x4c,0x0c,0x0a,0xe5,0x03,0x06,0x3c,0x6b,0xad,0xb3,0xc4,0x8b,0xe5,0x6c,0xe5,0x4b,0xd5,0x8c,0x8c,0xae,0x7c,0x6e,0x6c,0x0c,0x7c,0xaf,0x8c,0xf0,0x84,0x8e,0x8c,0xef,0x44,0x2b,0x3b,0xa8,0x33,0x68,0x03,0x65,0x54,0xed,0x54,0x8c,0x54,0xcd,0x3c,0x6a,0x3c,0x69,0x5c,0xed,0x5c,0x0b,0x94,0x8d,0x43,0xa9,0x33,0x07,0x9c,0xcf,0x6c,0x2c,0x44,0x2a,0x44,0x6a,0x4c,0xcc,0x4c,0xcb,0x24,0x69,0x0c,0x28
,0x0c,0x07,0x03,0xa6,0x03,0xe7,0x03,0xc6,0x03,0xc6,0x03,0xa6,0x3c,0x4a,0x12,0xc4,0x0a,0xc4,0x02,0x64,0x0a,0x43,0x0a,0x64,0x4c,0x2b,0x03,0x04,0x03,0x24,0x03,0x04,0x03,0x25,0x03,0x25,0x03,0x05,0x02,0xa4,0x0a,0xa5,0x33,0x48,0x53,0xab,0x4b,0x08,0x4b,0x28,0x6b,0xec,0x43,0x29,0x52,0xe8,0x4b,0x49,0x0a,0x84,0x13,0x05,0x2b,0xa8,0x33,0xa9,0x85,0x50,0x13,0x46,0x03,0x25,0x03,0x05,0x03,0x25,0x0b,0x46,0x2b,0x88,0x7d,0x30,0x6c,0xce,0x4c,0xcd,0x6d,0x50,0x5c,0xee,0x65,0x2e,0xad,0xb3,0xcc,0x49,0xe5,0x6a,0xe5,0x6a,0xe5,0x8b,0x8c,0x6d,0x64,0x0c,0x3a,0xc8,0x4b,0x29,0x5b,0xeb,0x42,0xc7,0x63,0xcb,0x43,0xaa,0x43,0xca,0x23,0xc9,0x03,0xc6,0x03,0xc7,0x03,0x46,0x03,0x66,0x03,0xa6,0x03,0x45,0x24,0x29,0x2b,0xc9,0x12,0x44,0x02,0x43,0x02,0x63,0x0a,0x24,0x0a,0xc4,0x3c,0xab,0x03,0xc5,0x03,0xc6,0x03,0xe6,0x03,0xe6,0x14,0x28
,0x0c,0x27,0x2c,0x69,0x3c,0xab,0x2c,0x4a,0x3c,0xcb,0x03,0xc6,0x64,0xcd,0x9c,0xee,0x6c,0xad,0x12,0xc5,0x84,0x8e,0x53,0xcb,0x54,0x2b,0x4c,0x6c,0x54,0x4c,0x44,0x2a,0x03,0x05,0x44,0x0a,0x54,0x2c,0x54,0x6c,0x2b,0xe9,0x8c,0x8f,0x4a,0xe8,0x7c,0x4e,0x6b,0xab,0x63,0x69,0x6b,0xec,0x52,0xe9,0x53,0x6a,0x02,0x64,0x2b,0x68,0x54,0x4d,0x7d,0x31,0x64,0xcf,0x0b,0x05,0x5c,0xce,0x54,0xaf,0x3c,0x6c,0x13,0x46,0x95,0x71,0xad,0x91,0xad,0xb2,0x75,0x4f,0x14,0x08,0x14,0x08,0x24,0x29,0x6c,0xcd,0x74,0x0a,0x7b,0xe9,0x7b,0xc8,0x73,0xe8,0x3b,0x28,0x12,0xe6,0x53,0xcb,0x32,0xc7,0x01,0xe3,0x02,0x03,0x02,0x23,0x02,0x64,0x03,0x05,0x03,0xc7,0x03,0xc6,0x03,0xe7,0x34,0x2a,0x4c,0xac,0x3c,0x8b,0x13,0x87,0x2c,0x29,0x64,0x2b,0xa4,0xcd,0x4b,0xaa,0x33,0x27,0x94,0xad,0x64,0x0c,0x3c,0x8a,0x3c,0x8a,0x3c,0xaa,0x34,0x8a,0x03,0xe6,0x0c,0x07
,0x0c,0x27,0x44,0xcb,0x6d,0x4f,0x65,0x2f,0x65,0x4e,0x0b,0xa6,0x7d,0x2f,0x9c,0xad,0x85,0x0f,0x12,0xe6,0x74,0x0c,0x53,0xeb,0x5c,0x2c,0x54,0x6d,0x85,0x92,0x64,0xad,0x03,0x05,0x1b,0x67,0x44,0x0c,0x95,0x32,0x5c,0x2c,0x74,0x2c,0x8c,0xaf,0x95,0x10,0x84,0x8e,0x7c,0x4e,0x84,0x6f,0x84,0x6f,0x74,0x2c,0x43,0x69,0x85,0x10,0x8d,0x52,0x64,0x6d,0x0b,0x26,0x43,0xea,0x3b,0xaa,0x4c,0x0c,0x3c,0x2c,0x13,0x47,0x85,0x10,0xa5,0x71,0x95,0x31,0x64,0x8e,0x03,0xe7,0x03,0xc7,0x03,0xe6,0x03,0xa6,0x0a,0xe5,0x42,0xe8,0x32,0x85,0x32,0x85,0x4b,0x68,0x4b,0x8a,0x64,0x0c,0x63,0xcb,0x4b,0x49,0x4b,0x49,0x4b,0x8a,0x4b,0x69,0x64,0x8d,0x64,0xef,0x33,0xea,0x03,0xe7,0x44,0xac,0x65,0x2e,0x7d,0x6f,0x34,0x6b,0x24,0x08,0x74,0x4c,0xa4,0xad,0x53,0xca,0x3b,0x68,0x94,0x6c,0x7c,0x6e,0x44,0x8b,0x3c,0xab,0x6d,0x8f,0x2c,0x6a,0x04,0x07,0x0c,0x28
,0x0c,0x07,0x03,0xe6,0x03,0xe6,0x03,0xc7,0x03,0xc6,0x0b,0xa6,0x3c,0x4a,0x33,0x88,0x13,0x26,0x02,0x84,0x12,0x64,0x0a,0x85,0x4c,0x0b,0x02,0xe5,0x03,0x05,0x0b,0x25,0x03,0x05,0x03,0x05,0x33,0x89,0xce,0x16,0xb5,0x51,0x9c,0xaf,0x5a,0xe9,0x4a,0x48,0x19,0x65,0x22,0x08,0x3a,0x28,0x42,0x08,0x5a,0xe9,0x73,0xcd,0xb5,0xb4,0xad,0x12,0x5c,0x2c,0x1b,0x67,0xad,0x92,0x63,0x8c,0x94,0xf1,0x6c,0xae,0x1b,0x26,0x2b,0x06,0x22,0x45,0x2a,0xa5,0x43,0xc9,0x44,0xac,0x14,0x08,0x03,0xe6,0x03,0xc6,0x13,0x47,0xad,0x52,0xad,0x30,0x8c,0x6e,0x6b,0x6a,0x52,0x88,0x3a,0x06,0x42,0x47,0x31,0xe6,0x42,0x47,0x52,0xe9,0x84,0x2d,0xce,0x36,0xbd,0xf5,0x7c,0xcf,0x03,0xc6,0x03,0x46,0x03,0x66,0x03,0xa6,0x03,0x46,0x24,0x28,0x2b,0xa8,0x1a,0x85,0x02,0x63,0x02,0x63,0x1a,0x65,0x12,0xe5,0x3c,0xab,0x03,0xc6,0x03,0xa6,0x03,0xe7,0x04,0x07,0x0c,0x28
,0x0c,0x27,0x24,0x69,0x2c,0x69,0x24,0x49,0x0b,0xe6,0x03,0xc6,0x5c,0x2b,0x84,0x4c,0x54,0x0a,0x0a,0x64,0x64,0x0c,0x3b,0x69,0x54,0x0b,0x33,0xc8,0x33,0xc9,0x34,0x09,0x03,0x05,0x03,0x05,0x23,0x48,0x95,0x93,0x7c,0xae,0x74,0x2d,0x52,0xaa,0x19,0x87,0x0b,0x11,0x0b,0xb4,0x0b,0x93,0x0a,0x0a,0x3a,0x07,0x5b,0x6b,0x63,0xec,0x74,0x6e,0x3b,0xca,0x13,0x47,0x64,0x6d,0x4b,0xca,0x6c,0x4d,0x74,0xcf,0x6c,0xee,0x42,0x88,0x3a,0x47,0x42,0x68,0x53,0x4a,0x44,0x4b,0x4c,0xcd,0x5d,0x0e,0x0b,0xe7,0x13,0x47,0x8d,0x52,0x6c,0x2d,0x63,0xcb,0x5a,0xe9,0x21,0x02,0x19,0x02,0x29,0x64,0x21,0x44,0x10,0xc1,0x39,0xe6,0x73,0xcc,0x7c,0x8e,0x84,0xef,0x54,0x2c,0x03,0xc7,0x2b,0xe9,0x34,0x29,0x24,0x08,0x13,0x86,0x24,0x08,0x53,0xca,0x84,0x8c,0x33,0x27,0x22,0xe5,0x84,0x4c,0x4b,0x89,0x3c,0xaa,0x2c,0x49,0x2c,0x6a,0x1c,0x49,0x04,0x07,0x04,0x28
,0x0c,0x07,0x4d,0x0d,0x6d,0x4f,0x3c,0xaa,0x0c,0x06,0x03,0xa6,0x85,0x10,0x84,0x0c,0x7c,0x8d,0x1a,0xa5,0x84,0xae,0x64,0x2c,0x64,0x4c,0x6c,0xee,0x6c,0xef,0x95,0xb2,0x02,0xe5,0x03,0x05,0x02,0xc4,0x02,0xe5,0x02,0x64,0x3b,0x28,0x31,0xe6,0x02,0xf1,0x03,0x76,0x03,0x56,0x03,0x55,0x03,0x95,0x09,0x87,0x2a,0x45,0x02,0x43,0x02,0xc4,0x02,0xe4,0x03,0x05,0x0b,0x05,0x4c,0x2b,0x33,0xea,0x02,0xc4,0x2b,0xa9,0x3a,0x27,0x3a,0x27,0x3a,0x28,0x4a,0x89,0x1a,0xe6,0x3c,0xab,0x85,0x70,0x44,0x8b,0x03,0x86,0x03,0x87,0x03,0x26,0x22,0xe6,0x31,0xe6,0x18,0xe2,0x18,0xe2,0x10,0xa2,0x10,0xa2,0x19,0x03,0x18,0xe2,0x53,0x6a,0x0b,0x05,0x03,0x86,0x03,0xc7,0x03,0xe7,0x54,0xcd,0x85,0x71,0x7d,0x71,0x3c,0x8b,0x24,0x28,0x7c,0x6d,0x94,0x4b,0x6c,0x6d,0x4b,0xa9,0xac,0x8b,0x7c,0x8e,0x44,0x8b,0x5c,0xed,0x85,0xb1,0x55,0x0e,0x03,0xe7,0x0c,0x28
,0x0c,0x08,0x03,0xc7,0x0c,0x07,0x03,0xe7,0x03,0xc6,0x03,0xa5,0x3c,0x0a,0x43,0x48,0x1a,0xa5,0x02,0x64,0x22,0xc6,0x0a,0x85,0x4c,0x2b,0x0a,0xc5,0x13,0x26,0x13,0x46,0x02,0xe5,0x54,0x4b,0x2b,0x6a,0x03,0x05,0x02,0xc5,0x43,0x69,0x32,0x28,0x03,0x95,0x03,0x55,0x03,0x55,0x03,0x55,0x03,0x76,0x0a,0x6d,0x32,0xc7,0x02,0x84,0x13,0x06,0x2b,0xa9,0x33,0xea,0x64,0x4c,0x74,0xae,0x7c,0xcf,0x3b,0xca,0x2b,0xa9,0x3a,0x27,0x42,0x69,0x42,0x48,0x42,0xc8,0x13,0x87,0x75,0x10,0x95,0x10,0x8d,0x30,0x54,0x8d,0x0b,0xa8,0x0b,0x86,0x23,0x68,0x29,0xa5,0x11,0x02,0x10,0xa2,0x10,0xa2,0x10,0xc2,0x10,0xa1,0x19,0x03,0x5b,0xcb,0x03,0x25,0x03,0xa6,0x03,0xa6,0x03,0xc7,0x03,0x46,0x0b,0x87,0x0b,0xa7,0x03,0x66,0x24,0x28,0x33,0xa9,0x43,0x47,0x0a,0x85,0x0a,0x84,0x3b,0x28,0x23,0x07,0x3c,0xac,0x03,0xe7,0x0b,0xc6,0x0b,0xe8,0x03,0xe7,0x0c,0x28
,0x0c,0x07,0x13,0xe7,0x14,0x07,0x14,0x07,0x03,0xc6,0x0b,0xa6,0x4b,0xea,0x6b,0xea,0x33,0xa7,0x0a,0x64,0x64,0x2c,0x2b,0x28,0x53,0xea,0x1b,0x26,0x1b,0x67,0x0b,0x26,0x13,0x26,0x2b,0xaa,0x1b,0x48,0x02,0xe5,0x02,0xc5,0x3b,0x08,0x32,0x28,0x0b,0x75,0x03,0x56,0x03,0x55,0x03,0x55,0x03,0x76,0x12,0x6c,0x32,0xc8,0x02,0x44,0x2b,0x47,0x3c,0x0a,0x54,0x4c,0x84,0xae,0xce,0x13,0xad,0x94,0x5c,0x4d,0x2b,0x89,0x32,0x06,0x31,0xe7,0x31,0xe7,0x42,0xa8,0x13,0x26,0xad,0xd3,0xce,0x34,0xce,0x55,0x74,0xaf,0x85,0x71,0x6c,0xee,0x2b,0x28,0x29,0xa5,0x21,0x23,0x10,0xa2,0x10,0xa2,0x10,0xc2,0x10,0xa2,0x18,0xe2,0x63,0xcb,0x03,0x46,0x03,0x86,0x03,0xa6,0x03,0xe7,0x13,0x87,0x13,0x88,0x13,0xc8,0x13,0x87,0x24,0x28,0x3b,0xc9,0x6c,0x0b,0x22,0xe6,0x12,0xa5,0x6b,0xeb,0x33,0x48,0x44,0xac,0x13,0xc8,0x13,0xe7,0x14,0x07,0x03,0xc7,0x0c,0x08
,0x0c,0x08,0x5d,0x2f,0x6d,0x50,0x65,0x0e,0x2c,0x69,0x03,0xa6,0x8d,0x2f,0x94,0x4b,0x7c,0x8d,0x22,0xe7,0x8c,0x4d,0x7c,0xae,0x64,0x6d,0x8d,0x71,0x6c,0xce,0x6c,0x6d,0x7d,0x30,0x03,0x06,0x33,0x48,0xa5,0xb3,0x8d,0x10,0x6b,0xeb,0x42,0x48,0x12,0xae,0x03,0x96,0x03,0x56,0x03,0x76,0x0b,0x74,0x19,0xa6,0x52,0xe9,0x95,0x10,0xad,0xd3,0x54,0x6d,0x3c,0x0b,0x7c,0xcf,0x33,0x48,0x4b,0xec,0x33,0xca,0x2b,0x48,0x42,0x47,0x42,0x47,0x42,0x68,0x42,0xa8,0x12,0xa6,0xa5,0x91,0x73,0xeb,0x73,0xcb,0x7c,0x6e,0xa5,0x93,0x9d,0x31,0x4b,0x29,0x4a,0x27,0x21,0x64,0x10,0xc2,0x10,0xc2,0x10,0xc2,0x18,0xc2,0x21,0x24,0x73,0x8b,0x9d,0x32,0xad,0xf5,0x5c,0x6d,0x03,0xe7,0x64,0xed,0x75,0x0f,0x4c,0x8c,0x3c,0x8b,0x24,0x28,0x84,0x6e,0x94,0x4b,0x6c,0x4c,0x53,0xaa,0x9c,0x2b,0x84,0x8e,0x54,0x8c,0x6d,0x4f,0x85,0xb0,0x54,0xec,0x03,0xe7,0x0c,0x08
,0x0c,0x07,0x0c,0x27,0x1c,0x68,0x24,0x69,0x0b,0xc6,0x0b,0xa6,0x54,0x0a,0x64,0x0b,0x2b,0x27,0x02,0x44,0x43,0x69,0x22,0xc6,0x54,0x2b,0x13,0x26,0x2b,0xa8,0x2b,0xa9,0x23,0xa9,0x03,0x45,0x3b,0xea,0xce,0x78,0xb5,0xd3,0x9c,0xf0,0x52,0xa8,0x29,0xe7,0x12,0x8d,0x1b,0x74,0x13,0x31,0x22,0x09,0x42,0x07,0x7c,0x0e,0xb5,0x92,0xa4,0xd0,0x7c,0xcf,0x3b,0xca,0x54,0x4e,0x7c,0xd0,0x8c,0x8f,0x64,0xce,0x2b,0x48,0x3a,0x26,0x42,0x47,0x42,0x68,0x42,0xa8,0x0a,0x85,0x9d,0x52,0x7c,0x2e,0x73,0xcd,0x64,0x2d,0xb5,0x53,0xb5,0x93,0x8c,0x8f,0x4a,0x68,0x31,0xa6,0x21,0x64,0x21,0x44,0x29,0x64,0x29,0x64,0x42,0x07,0x83,0xcd,0xc5,0xd3,0xbd,0x93,0x7d,0x10,0x03,0xe7,0x13,0xa7,0x1b,0xe8,0x1b,0xe8,0x0b,0x66,0x1c,0x28,0x3b,0xa9,0x5b,0xeb,0x1a,0xc6,0x12,0x85,0x63,0xea,0x33,0x49,0x3c,0xac,0x14,0x08,0x24,0x49,0x1c,0x4a,0x04,0x07,0x0c,0x08
,0x0c,0x08,0x03,0xe7,0x03,0xe7,0x03,0xc6,0x03,0xc6,0x0b,0xc6,0x44,0x09,0x43,0x67,0x1b,0x26,0x02,0x64,0x3b,0x69,0x1a,0xa6,0x54,0x2a,0x0a,0xe5,0x02,0xe5,0x0b,0x26,0x03,0x26,0x03,0xc6,0x13,0x88,0x4c,0x6d,0x4c,0x0b,0x53,0xea,0x74,0x8d,0x6c,0x6d,0x63,0xeb,0x5b,0xec,0x5b,0xcb,0x5b,0x6a,0x63,0xeb,0x5c,0x2c,0x43,0x8a,0x43,0xeb,0x23,0x48,0x33,0xc9,0x3b,0xea,0x7d,0x0f,0x7c,0xae,0x7d,0x10,0x4c,0x2b,0x63,0x8b,0x53,0x4a,0x4b,0x2a,0x4b,0x8a,0x13,0x06,0x74,0x6e,0x5c,0x0b,0x4b,0xeb,0x2b,0x68,0x3b,0xca,0x23,0x28,0x3b,0x69,0x7c,0x6e,0x6b,0xcc,0x43,0x08,0x4b,0x29,0x3a,0xa7,0x42,0xc9,0x63,0xcc,0x74,0xae,0x33,0xa9,0x3c,0x0a,0x23,0xa9,0x03,0xe7,0x03,0x46,0x03,0x66,0x0b,0x86,0x03,0x45,0x1c,0x28,0x33,0xc8,0x43,0x48,0x12,0xa5,0x0a,0x64,0x43,0x48,0x23,0x26,0x3c,0xac,0x03,0xa6,0x03,0xc6,0x03,0xc7,0x03,0xe7,0x0c,0x08
,0x04,0x08,0x5d,0x2e,0x6d,0x6f,0x44,0xec,0x34,0x8a,0x13,0xa6,0x8c,0xef,0x9c,0x4c,0x7c,0xae,0x1a,0xc6,0x8c,0x8e,0x74,0x8e,0x64,0x0c,0x85,0x50,0x6c,0xcd,0x4c,0x4c,0x44,0xac,0x03,0xc6,0x03,0xc6,0x03,0xc6,0x03,0xa6,0x03,0x45,0x03,0x24,0x2b,0x88,0x54,0x0b,0x43,0xe9,0x33,0xa8,0x02,0xc3,0x02,0xc4,0x02,0xc4,0x02,0xa4,0x03,0x05,0x03,0x05,0x54,0x4c,0x1b,0xc8,0x03,0xa7,0x2b,0xc8,0x33,0xea,0x54,0xac,0xa5,0xb2,0x43,0x28,0x3b,0x29,0x3b,0x49,0x1b,0x47,0x8d,0x30,0x95,0x10,0x6c,0xae,0x13,0x47,0x03,0x06,0x23,0x89,0x64,0xaf,0x64,0x6d,0x2a,0xe7,0x33,0x48,0x3b,0xea,0x1b,0x47,0x13,0x46,0x13,0x26,0x1b,0xa8,0x03,0x66,0x03,0xa6,0x03,0xa6,0x03,0xa7,0x54,0xad,0x75,0x0f,0x64,0xed,0x3c,0x4a,0x23,0xc7,0x7c,0x8c,0x94,0x2b,0x64,0x2c,0x53,0xaa,0xa4,0xac,0x84,0x8e,0x74,0xee,0x7d,0x4f,0x6d,0x2e,0x75,0x4f,0x0c,0x08,0x0c,0x29
,0x0c,0x07,0x1c,0x48,0x2c,0x69,0x2c,0xaa,0x24,0x6a,0x13,0xc7,0x64,0x4c,0x7c,0x6c,0x43,0x89,0x0a,0x64,0x5b,0xeb,0x2a,0xe7,0x53,0xeb,0x23,0x47,0x33,0xc9,0x43,0xeb,0x3c,0x6b,0x03,0xc6,0x03,0xc5,0x03,0xa5,0x03,0x85,0x03,0x65,0x03,0x44,0x23,0x47,0x33,0x07,0x3b,0x28,0x1a,0xa5,0x02,0x43,0x02,0x63,0x02,0xa4,0x02,0xc4,0x2b,0x48,0x2b,0x68,0x64,0xef,0x34,0x4c,0x3c,0x6b,0x3c,0x0b,0x3c,0x2c,0x1c,0x29,0xa5,0x93,0xb5,0xb2,0xbd,0xd3,0x7c,0xcf,0x54,0x2d,0x9c,0xf0,0x6b,0x8b,0x9d,0x52,0x33,0xca,0x02,0xc5,0x1b,0x27,0x74,0x8f,0x54,0x0c,0x53,0x6a,0x6b,0x8c,0x7c,0xaf,0x6c,0xae,0x6c,0xcd,0x6c,0xee,0x44,0x6c,0x03,0x25,0x03,0x45,0x03,0x45,0x03,0x85,0x1b,0xc9,0x2b,0xc9,0x2c,0x4a,0x23,0xe8,0x23,0xa8,0x4b,0xaa,0x84,0x6c,0x33,0x27,0x23,0x07,0x84,0x8d,0x53,0xca,0x4c,0xcd,0x1b,0xe8,0x3c,0xab,0x34,0x8b,0x0c,0x08,0x0c,0x29
,0x04,0x27,0x03,0xc6,0x04,0x07,0x03,0xe6,0x03,0xc6,0x03,0xa6,0x3c,0x0a,0x22,0x85,0x12,0xa4,0x02,0x64,0x1a,0xc5,0x0a,0x85,0x4b,0xeb,0x02,0xc4,0x02,0xe5,0x02,0xe5,0x03,0x25,0x03,0xa6,0x03,0x05,0x02,0xe5,0x02,0xc5,0x02,0xa4,0x02,0x84,0x02,0x23,0x02,0x03,0x01,0xe2,0x02,0x22,0x02,0x23,0x02,0x43,0x0a,0x83,0x2b,0x48,0x84,0xd0,0x95,0x71,0x9d,0x73,0x8c,0xd1,0x8d,0x10,0x5c,0x8d,0x3b,0xeb,0x13,0xa8,0x85,0x31,0x6c,0x2d,0x74,0x8e,0x5c,0x4d,0x54,0x0c,0x7c,0x6e,0x5b,0x8a,0x74,0xaf,0x33,0xea,0x02,0xe5,0x24,0x09,0x73,0xac,0x4c,0x0b,0x43,0x09,0x4a,0x88,0x4b,0xaa,0x2b,0x68,0x23,0x07,0x02,0xc5,0x03,0x05,0x03,0x26,0x03,0x26,0x03,0x26,0x03,0x26,0x03,0x25,0x03,0xa6,0x03,0x45,0x03,0xc6,0x23,0xa8,0x2b,0x48,0x2a,0xc6,0x02,0x64,0x02,0x84,0x22,0x85,0x12,0xc5,0x3c,0xac,0x03,0xc7,0x03,0xe6,0x03,0xe7,0x03,0xe7,0x0c,0x08
,0x0c,0x07,0x4c,0xcc,0x5d,0x0d,0x3c,0xcb,0x34,0x69,0x13,0xe7,0x7c,0xce,0xac,0xcd,0x7c,0x8d,0x1a,0x85,0x94,0xcf,0x64,0x4d,0x5c,0x0b,0x64,0x8d,0x54,0x4c,0x43,0xeb,0x44,0x6b,0x03,0x05,0x02,0x84,0x02,0x84,0x02,0x84,0x02,0x63,0x02,0x43,0x0a,0x23,0x02,0x02,0x02,0x02,0x02,0x22,0x02,0x43,0x02,0x64,0x1a,0x84,0x74,0x8f,0x8c,0x8e,0x95,0x10,0x94,0xaf,0x8c,0xb0,0x8c,0x8e,0x2c,0x0a,0x64,0xce,0x8d,0x92,0x6d,0x0f,0x6d,0x10,0x44,0x4b,0x23,0xe8,0x9d,0xd3,0xa6,0x14,0x2b,0xc9,0x0b,0x87,0x0b,0x46,0x54,0xae,0x6c,0xce,0x84,0xb0,0x43,0x8a,0x63,0xcc,0x8c,0x6f,0x64,0x2d,0x54,0x4c,0x4c,0x0b,0x03,0x05,0x03,0x25,0x03,0x25,0x03,0x25,0x03,0x45,0x03,0x46,0x44,0x4a,0x5c,0xac,0x44,0x8b,0x34,0x8a,0x23,0x87,0x6c,0x4c,0x9c,0x8c,0x5c,0x0b,0x4b,0x68,0xa4,0x8c,0x7c,0x4d,0x4c,0x8c,0x6d,0x0e,0x65,0x2e,0x54,0xac,0x0b,0xc7,0x0c,0x08
,0x04,0x07,0x34,0x8a,0x3c,0xab,0x3c,0xcb,0x34,0x8a,0x1c,0x07,0x6c,0x6c,0x9c,0xad,0x5b,0xec,0x12,0x64,0x6b,0xeb,0x4b,0x8a,0x53,0xeb,0x33,0xa9,0x4b,0xea,0x4c,0x0b,0x4c,0x0a,0x02,0x84,0x02,0x83,0x02,0x83,0x02,0xc3,0x02,0xa3,0x02,0x83,0x02,0x83,0x02,0x63,0x02,0x03,0x01,0xe2,0x02,0x23,0x02,0x63,0x0a,0x64,0x53,0xeb,0x5b,0xec,0x64,0x0b,0x74,0xae,0x5c,0x2d,0x74,0xae,0x23,0x69,0x6c,0xae,0x8c,0x8f,0x9d,0x30,0x7d,0x11,0x64,0x8e,0x95,0x93,0x9d,0x11,0x94,0xb0,0x6d,0x10,0x44,0xad,0x4c,0x4c,0x6c,0x4d,0x2a,0xc7,0x6c,0x0e,0x33,0x69,0x44,0x2b,0x54,0x0c,0x2b,0x68,0x02,0xc4,0x02,0xe5,0x02,0xc4,0x03,0x86,0x03,0x85,0x03,0xa6,0x03,0xa6,0x03,0xc6,0x34,0x6a,0x34,0x6b,0x34,0x8b,0x2c,0x6a,0x23,0x68,0x5b,0xea,0x84,0x6d,0x43,0x8a,0x33,0x27,0x8c,0x6c,0x64,0x0c,0x44,0xac,0x34,0x4a,0x5d,0x0d,0x4c,0xcd,0x0c,0x08,0x0c,0x29
,0x04,0x07,0x04,0x07,0x03,0xe7,0x03,0xe6,0x03,0xc6,0x03,0xa5,0x3c,0x2a,0x12,0x23,0x02,0x63,0x02,0x63,0x0a,0x24,0x02,0x24,0x43,0xea,0x02,0xa4,0x02,0xa4,0x02,0xa4,0x02,0xa4,0x02,0xa4,0x02,0x84,0x02,0xe4,0x0b,0x24,0x23,0x66,0x23,0x86,0x02,0xe3,0x02,0xc3,0x02,0x23,0x02,0x23,0x02,0x23,0x02,0x23,0x01,0xc2,0x1a,0x24,0x12,0x04,0x09,0xc3,0x12,0x24,0x12,0x44,0x63,0xeb,0x5b,0xec,0x74,0x8f,0x6c,0x2c,0x64,0x0c,0x8d,0x72,0x5b,0xca,0x84,0x8f,0x9d,0x73,0x95,0x11,0x84,0xf0,0x95,0x52,0x8c,0xf1,0x6b,0x8c,0x11,0x63,0x4a,0xa8,0x22,0xa6,0x03,0x65,0x1b,0xa8,0x13,0x46,0x02,0xe5,0x03,0x05,0x03,0x05,0x02,0xc5,0x02,0xe5,0x03,0x05,0x03,0x06,0x03,0x26,0x03,0x26,0x03,0x26,0x03,0x26,0x03,0x05,0x23,0x87,0x2b,0xc8,0x12,0x44,0x02,0x64,0x02,0x84,0x0a,0x43,0x0a,0xc5,0x44,0xcc,0x03,0xc7,0x03,0xc7,0x03,0xe7,0x04,0x08,0x0c,0x08
,0x04,0x07,0x34,0x8b,0x3c,0xcc,0x2c,0x89,0x24,0x6a,0x0b,0xa6,0x6c,0x6d,0x9c,0xad,0x64,0x4b,0x0a,0x64,0x74,0x2c,0x43,0x89,0x4b,0xea,0x43,0xea,0x44,0x0a,0x23,0x47,0x3b,0xa9,0x02,0x83,0x02,0x63,0x02,0xc4,0x0b,0x25,0x23,0x47,0x2b,0xa9,0x43,0xca,0x5b,0xaa,0x7c,0x6e,0x2a,0xc6,0x02,0x43,0x09,0xe3,0x11,0x63,0x29,0xc5,0x29,0xc5,0x29,0xc5,0x32,0x06,0x3a,0x06,0x31,0xe5,0x32,0x67,0x95,0x12,0x63,0xcd,0x9d,0xb4,0xa5,0x72,0xac,0xef,0xad,0x31,0xa5,0x93,0x9d,0x11,0x63,0x4b,0x84,0x4e,0x74,0x2d,0x19,0x03,0x21,0x23,0x19,0x03,0x32,0x86,0x23,0x27,0x8c,0xf1,0x84,0xf0,0x33,0x49,0x1a,0xe7,0x02,0x64,0x03,0x25,0x03,0x05,0x03,0x25,0x03,0x45,0x03,0x66,0x34,0x0a,0x44,0x4b,0x2c,0x09,0x1b,0xc7,0x1c,0x08,0x64,0x2b,0xa4,0xcd,0x4b,0xaa,0x33,0x27,0x9c,0xed,0x6c,0x2b,0x44,0x8b,0x4c,0xab,0x4c,0xcc,0x34,0x6a,0x04,0x27,0x0c,0x08
,0x04,0x07,0x4c,0xcc,0x5d,0x2e,0x4d,0x0c,0x44,0xcb,0x24,0x08,0x7c,0xad,0x94,0x8c,0x74,0x4c,0x12,0x64,0x73,0xeb,0x53,0xaa,0x4c,0x0b,0x44,0x0b,0x6c,0xef,0x3b,0xca,0x5c,0x4d,0x02,0x64,0x02,0x43,0x02,0xa3,0x0a,0xe5,0x23,0x47,0x33,0x87,0x43,0x8a,0x5b,0x6a,0x7c,0x4d,0x2a,0xe6,0x02,0x23,0x12,0x44,0x21,0x84,0x21,0x44,0x29,0x64,0x31,0xc6,0x31,0xc6,0x31,0xa5,0x29,0x85,0x3a,0x67,0x6c,0x6e,0x4b,0x6a,0x63,0xec,0x7c,0x6f,0x7c,0x6d,0x74,0x2d,0x85,0x30,0x6c,0x6d,0x4b,0x49,0x7c,0x6e,0x64,0x4e,0x52,0x88,0x4a,0x68,0x42,0x27,0x53,0x4a,0x84,0xf0,0x53,0x09,0x53,0x6b,0x7c,0x70,0x54,0x6d,0x1b,0x27,0x23,0xe9,0x13,0xc7,0x03,0xa6,0x03,0xa6,0x03,0xc6,0x44,0xac,0x4c,0xcc,0x44,0x8b,0x3c,0xaa,0x1c,0x28,0x74,0x4d,0x9c,0x8b,0x5b,0xea,0x3b,0x47,0x9c,0x6c,0x74,0x2c,0x4c,0x6b,0x4c,0xab,0x65,0x4e,0x55,0x2e,0x0c,0x28,0x0c,0x28
,0x04,0x26,0x03,0xc6,0x03,0xe6,0x03,0xe6,0x03,0xc5,0x03,0xa6,0x3c,0x09,0x22,0x84,0x0a,0x63,0x02,0x63,0x12,0x65,0x0a,0x44,0x43,0xea,0x02,0x84,0x02,0xa3,0x02,0x84,0x02,0x84,0x02,0x63,0x02,0x43,0x02,0xa3,0x0a,0xc4,0x1b,0x06,0x23,0x48,0x53,0xca,0x73,0x8b,0x84,0x6e,0x32,0xe7,0x02,0x84,0x09,0xe2,0x21,0x84,0x21,0x44,0x21,0x64,0x29,0x85,0x29,0x85,0x29,0xa5,0x29,0x85,0x32,0x67,0x6c,0x6d,0x94,0xf1,0x95,0x11,0x95,0x51,0x9d,0xd3,0x95,0x52,0x85,0x11,0x7c,0xd0,0x8d,0x30,0x9d,0xb3,0x23,0x07,0xa5,0x93,0x94,0xf0,0x8c,0xb0,0x4b,0xab,0x95,0x31,0x7c,0x2d,0x84,0x8f,0x74,0x0d,0x54,0x0c,0x43,0xaa,0x64,0xee,0x44,0x8b,0x03,0xc6,0x03,0xc5,0x03,0xc6,0x03,0xc6,0x03,0xe6,0x03,0xe6,0x03,0xc6,0x1c,0x28,0x2b,0xa9,0x22,0x85,0x02,0x64,0x02,0x85,0x1a,0x65,0x12,0xc5,0x3c,0xcc,0x03,0xe7,0x03,0xe6,0x03,0xe6,0x03,0xe7,0x14,0x08
,0x04,0x27,0x24,0x49,0x24,0x49,0x1c,0x48,0x14,0x07,0x0b,0xa6,0x5c,0x2a,0x7c,0x2b,0x54,0x0a,0x0a,0x44,0x63,0xcb,0x32,0xe8,0x4b,0xaa,0x33,0x68,0x33,0x87,0x23,0x06,0x23,0x27,0x02,0x63,0x02,0xa3,0x02,0xc4,0x02,0xa3,0x02,0xa3,0x02,0xa3,0x22,0xe5,0x32,0x86,0x43,0x69,0x1b,0x06,0x02,0x63,0x09,0xe3,0x21,0xa5,0x29,0xa5,0x31,0xa6,0x29,0x85,0x31,0xc6,0x31,0xc6,0x31,0xc6,0x32,0x66,0x6c,0x2d,0x7c,0x2e,0x7c,0x4d,0x7c,0x8f,0x75,0x51,0xa5,0xb3,0x8d,0x32,0x8d,0x32,0x9d,0x93,0x8d,0x92,0x0a,0x85,0x3b,0xaa,0x33,0x69,0x43,0x49,0x3a,0xe8,0x53,0xaa,0x6c,0x4d,0x74,0xaf,0x6c,0x8e,0x43,0xeb,0x02,0xa5,0x03,0xa6,0x03,0xc6,0x03,0xc6,0x03,0xc6,0x03,0xc6,0x24,0x49,0x24,0x69,0x24,0x69,0x24,0x28,0x34,0x6a,0x4b,0xea,0x84,0x2b,0x3b,0x48,0x22,0xe6,0x8c,0x4c,0x53,0xaa,0x44,0x8b,0x3c,0x4a,0x34,0x6a,0x34,0x49,0x03,0xe7,0x14,0x08
,0x04,0x07,0x55,0x0d,0x75,0x6f,0x5d,0x4f,0x3c,0xab,0x1c,0x08,0x84,0xce,0x8b,0xea,0x7c,0x6d,0x12,0x64,0x7c,0x0b,0x4b,0x49,0x53,0xea,0x6c,0x6c,0x8d,0x70,0x5c,0x0a,0x4c,0x0a,0x02,0xc3,0x02,0xe4,0x02,0xc3,0x02,0xa3,0x02,0xa3,0x02,0x83,0x33,0x27,0x3a,0xc6,0x43,0x08,0x3b,0x49,0x02,0xe4,0x01,0xc2,0x21,0xa5,0x29,0x85,0x29,0xa5,0x31,0xc6,0x29,0x85,0x31,0xc6,0x29,0x85,0x32,0x46,0x7c,0x8f,0x94,0xd0,0x94,0x90,0xa5,0xb3,0xae,0x14,0xad,0xd4,0x8d,0x11,0x95,0x73,0xb6,0x15,0x95,0x51,0x3b,0xaa,0x5c,0x6d,0x23,0x06,0x53,0x69,0x6b,0xcb,0x43,0x48,0x22,0xc6,0x13,0x05,0x03,0x45,0x03,0x04,0x02,0xc5,0x03,0x45,0x03,0xc6,0x03,0xc6,0x03,0xc6,0x03,0xc6,0x4c,0xcc,0x5d,0x0e,0x3c,0xab,0x4c,0xed,0x44,0xac,0x7c,0x8d,0x94,0x2b,0x6c,0x2c,0x43,0x88,0x9c,0x4c,0x7c,0x6d,0x4c,0x8b,0x64,0xcd,0x75,0x6f,0x75,0x4f,0x1c,0x69,0x14,0x08
,0x04,0x06,0x0c,0x07,0x14,0x27,0x14,0x07,0x14,0x07,0x0b,0xc6,0x3b,0xe9,0x3b,0x48,0x1a,0xa5,0x02,0x43,0x1a,0x84,0x0a,0x04,0x43,0xc9,0x0a,0xc5,0x0b,0x66,0x0b,0x65,0x0b,0x65,0x03,0x04,0x02,0xe3,0x02,0xc3,0x2b,0x87,0x3b,0xc9,0x1a,0xc4,0x63,0xcb,0x83,0xec,0x84,0x0d,0x74,0x4e,0x0a,0x23,0x09,0xe3,0x21,0xa4,0x21,0x64,0x29,0x64,0x31,0xa5,0x29,0x85,0x29,0x85,0x21,0x64,0x32,0x26,0x63,0xec,0x84,0x90,0x84,0xd1,0x84,0xcf,0x85,0x71,0x8d,0x32,0x53,0x2a,0x7c,0xb0,0x7d,0x52,0x64,0xd0,0x4c,0x2d,0xa5,0x72,0xb4,0xed,0xc4,0xca,0xc5,0x0a,0xc5,0x0b,0xad,0x0e,0x3c,0x4b,0x03,0xa5,0x03,0xa5,0x03,0x25,0x03,0x25,0x03,0xc6,0x03,0xc6,0x03,0xc6,0x03,0xc6,0x03,0xe6,0x0b,0xc7,0x0c,0x07,0x0c,0x07,0x24,0x28,0x2b,0xc9,0x43,0x68,0x0a,0x85,0x02,0x64,0x3b,0x27,0x1a,0xe6,0x44,0xcc,0x03,0xe7,0x0b,0xe7,0x0c,0x07,0x04,0x07,0x0c,0x08
,0x04,0x07,0x04,0x06,0x04,0x06,0x03,0xc6,0x03,0xa5,0x0b,0xa6,0x4c,0x0a,0x6b,0xea,0x33,0x07,0x0a,0x64,0x5b,0xeb,0x32,0xe7,0x43,0xa9,0x12,0xe5,0x13,0x86,0x0b,0x65,0x0b,0x45,0x03,0x04,0x03,0x03,0x02,0xc3,0x02,0x84,0x02,0x62,0x02,0x62,0x43,0x09,0x3a,0x25,0x3a,0x86,0x4b,0xcb,0x02,0x44,0x09,0xe4,0x21,0x84,0x21,0x24,0x21,0x44,0x31,0xe5,0x31,0xa5,0x21,0x64,0x21,0x44,0x3a,0x67,0x4b,0xaa,0x6c,0x0d,0x74,0x4e,0x84,0xf0,0x8c,0xef,0x7c,0x4d,0x95,0x51,0x8c,0xf0,0x8c,0xd0,0x74,0x4d,0xa5,0x93,0x9d,0x72,0xcd,0x6e,0xe5,0x4a,0xe5,0x2a,0xdd,0x49,0xc5,0xd0,0x3c,0x6b,0x03,0xc6,0x03,0xa5,0x03,0x45,0x03,0x06,0x03,0xe6,0x03,0xe6,0x03,0xe6,0x03,0xe6,0x14,0x27,0x14,0x08,0x14,0x28,0x14,0x07,0x24,0x29,0x43,0xca,0x6b,0xeb,0x22,0xe6,0x12,0xa5,0x6b,0xea,0x3b,0x68,0x44,0xab,0x13,0xe7,0x14,0x07,0x13,0xe7,0x0c,0x07,0x0c,0x28
,0x0c,0x28,0x5d,0x4e,0x7d,0x90,0x5d,0x2e,0x34,0x6a,0x2c,0x29,0x8c,0xef,0x8b,0xea,0x7c,0x6d,0x22,0xa7,0x84,0x0c,0x6c,0x0d,0x53,0xaa,0x74,0xce,0x7d,0x2f,0x44,0x4b,0x65,0x2e,0x03,0x24,0x03,0x04,0x02,0xc3,0x12,0xe6,0x23,0x27,0x12,0xc4,0x5b,0xab,0x73,0xab,0x73,0xcb,0x64,0x0c,0x02,0x64,0x02,0x23,0x21,0xe5,0x31,0xc6,0x31,0xc6,0x31,0xc5,0x31,0xe5,0x31,0xe5,0x29,0xc5,0x2a,0xe7,0x54,0x0b,0x5b,0x4a,0x6c,0x0d,0x9d,0x52,0x9d,0x31,0x9d,0x10,0x8c,0xf0,0x95,0x72,0xa5,0x32,0x8c,0xae,0x84,0xaf,0x85,0x31,0x84,0x8d,0x8c,0x8b,0x94,0x8c,0xa4,0xac,0x84,0x6d,0x4c,0x2b,0x4c,0xcc,0x34,0x6a,0x0b,0x66,0x03,0x26,0x03,0xc6,0x03,0xe6,0x03,0xc6,0x03,0xe6,0x5d,0x0d,0x65,0x6f,0x3c,0xcb,0x65,0x0e,0x5c,0xed,0x8c,0x8e,0x9c,0x0b,0x6c,0x2c,0x4b,0x89,0x9c,0x4b,0x84,0xae,0x54,0x6b,0x75,0x2e,0x4c,0xac,0x44,0xac,0x44,0xed,0x0c,0x08
,0x0c,0x07,0x14,0x29,0x24,0x6a,0x2c,0x6a,0x1c,0x69,0x13,0xc7,0x4b,0xea,0x64,0x0b,0x2b,0x27,0x02,0x44,0x3a,0xe7,0x1a,0x65,0x4b,0xaa,0x12,0xc5,0x23,0xc8,0x1b,0xe8,0x0b,0x66,0x03,0x24,0x02,0xe4,0x02,0xa4,0x1a,0xe6,0x23,0x26,0x1a,0xc5,0x43,0x09,0x3a,0x25,0x3a,0x66,0x53,0xcb,0x02,0x44,0x02,0x44,0x12,0x44,0x2a,0x66,0x22,0x44,0x1a,0x65,0x2a,0x86,0x1a,0x65,0x3b,0x49,0x33,0xe9,0x54,0xcd,0x6d,0x2f,0x55,0x0e,0x54,0x6c,0x43,0x49,0x4b,0x6a,0x53,0xcb,0x4b,0xcb,0x43,0x6a,0x3b,0x49,0x4b,0xab,0x43,0xca,0x7c,0x6d,0x43,0x68,0x22,0x65,0x32,0x85,0x33,0x48,0x2b,0x89,0x4c,0x4d,0x5c,0xcf,0x13,0xa7,0x03,0x05,0x03,0x45,0x03,0x45,0x03,0x66,0x03,0x66,0x13,0x87,0x1b,0xa7,0x24,0x4a,0x24,0x6a,0x2c,0x69,0x3b,0xca,0x5b,0xca,0x1b,0x06,0x12,0x85,0x63,0xeb,0x33,0x48,0x4c,0xac,0x0b,0xe7,0x24,0x49,0x1c,0x69,0x1c,0x6a,0x0c,0x08
,0x04,0x07,0x03,0xc7,0x03,0xe6,0x03,0xc6,0x03,0xa6,0x0b,0xa6,0x3b,0xea,0x43,0x48,0x12,0xa5,0x02,0x44,0x2a,0xe6,0x12,0x65,0x43,0xa9,0x0a,0x84,0x03,0x45,0x03,0x65,0x03,0x45,0x0b,0x46,0x13,0x25,0x12,0xa4,0x02,0x63,0x02,0x63,0x02,0x43,0x43,0x49,0x63,0x6a,0x6b,0xab,0x32,0xc7,0x3b,0x89,0x3b,0x89,0x3b,0x6a,0x64,0x2e,0x5c,0x0c,0x53,0xec,0x7c,0xcf,0x43,0xca,0x43,0xeb,0x3b,0xea,0x44,0x8c,0x65,0x0f,0x5d,0x2f,0x7d,0x10,0x8c,0x8f,0x7c,0x0d,0x95,0x31,0x8d,0x31,0x8c,0x4f,0x73,0xcc,0x9d,0x52,0x64,0x6e,0x4a,0xe8,0x4b,0x8b,0x4b,0x0b,0x53,0x2b,0x13,0x05,0x1b,0xc7,0x44,0x0b,0x13,0x67,0x03,0x86,0x02,0xe5,0x02,0xc5,0x02,0xc5,0x02,0xc5,0x02,0xe5,0x02,0xe5,0x02,0xe6,0x03,0x45,0x03,0xc6,0x1c,0x28,0x33,0xca,0x43,0x68,0x12,0x84,0x0a,0x85,0x4b,0x28,0x23,0x06,0x44,0xab,0x03,0xa6,0x03,0xc6,0x03,0xe6,0x03,0xc6,0x0c,0x07
,0x0c,0x07,0x5d,0x2e,0x7d,0x90,0x4d,0x0d,0x4c,0xab,0x23,0xe8,0x84,0xef,0x9c,0x2b,0x7c,0x6d,0x12,0x86,0x73,0xec,0x5b,0xab,0x4b,0xaa,0x7c,0xcf,0x64,0xee,0x6d,0x2f,0x0b,0x25,0x23,0x67,0x33,0x68,0x3b,0x27,0x02,0x63,0x02,0x43,0x02,0x43,0x3b,0x07,0x42,0x25,0x4b,0x08,0x3b,0x07,0x2b,0x27,0x43,0xca,0x84,0x8e,0x9d,0x31,0x33,0x08,0x8c,0xd0,0x95,0x11,0x54,0x0b,0x6c,0x4d,0x53,0xca,0x43,0xc9,0x7c,0xcf,0x74,0xce,0x74,0x6e,0x7c,0x2e,0x63,0x8b,0x5b,0xab,0x74,0x6e,0x6b,0xcc,0x63,0x8a,0x84,0xd0,0x74,0xcf,0x7c,0x4e,0x5b,0xec,0x53,0x6c,0x53,0x8d,0x12,0xe6,0x2b,0x88,0x64,0xaf,0x23,0x27,0x13,0x67,0x13,0x06,0x02,0xe5,0x02,0xe4,0x02,0xe4,0x03,0x05,0x64,0x8d,0x6c,0xcf,0x4c,0x4c,0x5c,0xce,0x65,0x2e,0x84,0x8e,0xa4,0xed,0x64,0x0b,0x43,0x69,0x9c,0x4c,0x84,0x6d,0x54,0x6b,0x6d,0x6e,0x6d,0x4e,0x4c,0x8b,0x55,0x4e,0x0c,0x29
,0x0c,0x07,0x1c,0x49,0x2c,0x8a,0x34,0xab,0x24,0x48,0x1b,0xc7,0x54,0x0a,0x7c,0x2b,0x43,0x89,0x0a,0x44,0x43,0x08,0x12,0x45,0x4b,0xa9,0x1b,0x06,0x3b,0xa9,0x3b,0xc9,0x03,0x45,0x02,0xc5,0x32,0xe7,0x42,0xe7,0x2a,0xc7,0x32,0xc6,0x32,0xa6,0x4b,0x08,0x5a,0xc8,0x5b,0x2a,0x53,0x49,0x3b,0x28,0x33,0xea,0x73,0xec,0x73,0xec,0x2b,0x07,0x7c,0x2c,0x6b,0xab,0x84,0x8e,0xad,0x72,0x8c,0xcf,0xa5,0x93,0x95,0x30,0x7d,0x11,0x9d,0x93,0x4b,0xab,0x74,0x4e,0x29,0xe5,0x7c,0x2e,0x74,0x8f,0x9d,0x93,0xad,0xf4,0x4c,0x4c,0x4c,0x2b,0x2b,0x48,0x0a,0x65,0x0a,0xa5,0x13,0x05,0x8d,0x31,0x85,0x51,0x75,0x2f,0x4d,0x2f,0x85,0xd1,0x03,0xc7,0x03,0xc6,0x03,0xc6,0x03,0xc6,0x1b,0x88,0x1b,0x68,0x2b,0xc9,0x2b,0xc9,0x44,0x2b,0x5c,0x0b,0x84,0x8c,0x33,0x07,0x1a,0xa4,0x74,0x2b,0x43,0x28,0x4c,0x8b,0x1c,0x07,0x2c,0x8a,0x3c,0xaa,0x2c,0xaa,0x0c,0x08
,0x0c,0x07,0x04,0x06,0x03,0xe6,0x03,0xc6,0x03,0xc6,0x0b,0x85,0x33,0xe9,0x22,0x85,0x0a,0x44,0x02,0x44,0x1a,0x65,0x0a,0x03,0x43,0xa9,0x02,0xa4,0x02,0x43,0x02,0xa4,0x03,0x25,0x0a,0x65,0x10,0xc2,0x10,0xa1,0x08,0xa1,0x10,0xc2,0x10,0xa1,0x10,0xa2,0x10,0xc2,0x10,0xc2,0x10,0xc1,0x09,0x02,0x1b,0x27,0x7c,0x0c,0x7b,0xec,0x2b,0x48,0x74,0x0c,0x73,0xec,0x94,0x0b,0xcc,0x49,0xa4,0x09,0x8c,0xae,0x8c,0x8e,0x74,0x4d,0xa5,0x10,0x53,0x8b,0x94,0xd0,0x31,0x84,0x3a,0xa7,0x54,0x2d,0x7c,0xd0,0x85,0x11,0x74,0xcf,0xa5,0xb4,0x43,0xeb,0x0a,0xa5,0x95,0x52,0x6c,0x0c,0x9d,0x71,0x23,0x68,0x23,0x88,0x23,0xa8,0x1b,0x88,0x1c,0x08,0x03,0xe6,0x03,0xc6,0x03,0xe6,0x03,0xa6,0x03,0x46,0x03,0x05,0x02,0xe5,0x23,0x68,0x33,0x89,0x22,0xe5,0x0a,0x84,0x02,0x83,0x2a,0xc5,0x12,0x84,0x4c,0x6b,0x03,0xc6,0x04,0x06,0x04,0x06,0x03,0xe6,0x0c,0x28
,0x0c,0x06,0x44,0xcb,0x4c,0xec,0x54,0xed,0x2c,0x69,0x0b,0xa5,0x74,0x8d,0x9c,0x6d,0x6c,0x2c,0x12,0x85,0x7c,0x6d,0x53,0x8a,0x4b,0x89,0x54,0x2c,0x4c,0x0b,0x33,0xa9,0x3c,0x09,0x1a,0x04,0x19,0x23,0x10,0xa1,0x10,0x81,0x10,0x81,0x10,0x81,0x10,0x81,0x10,0xa1,0x10,0x81,0x10,0x81,0x08,0xe2,0x13,0x27,0x84,0xb0,0x84,0x8f,0x33,0x68,0x7c,0x6d,0x7c,0x6d,0x94,0x2b,0xe5,0x4a,0xbc,0xaa,0x8c,0x8d,0x8c,0x6d,0x7c,0x6d,0xad,0x10,0x53,0xab,0x6c,0x0c,0x29,0x84,0x42,0x88,0x64,0x6e,0x7c,0xd0,0x95,0x73,0x74,0x8e,0x6b,0xed,0x7c,0xf0,0x5c,0x6d,0xbe,0x35,0x7c,0x8f,0x8d,0x10,0x0a,0xe6,0x74,0x8f,0x84,0x0d,0x7b,0xac,0x9d,0x73,0x0b,0xe7,0x03,0xe6,0x03,0xe6,0x44,0xcc,0x5d,0x0e,0x4b,0xea,0x54,0x4c,0x5c,0x4c,0x8c,0xce,0xac,0xae,0x5b,0xeb,0x3b,0x27,0xac,0xad,0x74,0x4c,0x4b,0xea,0x54,0xcc,0x3c,0xaa,0x34,0x8a,0x3c,0xec,0x0c,0x08
,0x0c,0x07,0x34,0xaa,0x3c,0xaa,0x44,0xcc,0x2c,0x6a,0x03,0xa5,0x6c,0x4b,0x9c,0xad,0x53,0xea,0x0a,0x65,0x73,0xcb,0x22,0x45,0x4b,0xa9,0x33,0x48,0x4b,0xeb,0x43,0xca,0x3b,0xc9,0x1a,0x25,0x21,0x03,0x10,0xa1,0x08,0x60,0x08,0x60,0x08,0x61,0x10,0x81,0x10,0x81,0x10,0x81,0x08,0x81,0x08,0xe1,0x1b,0x27,0x8c,0xb0,0x8c,0xd0,0x33,0x68,0x84,0x8f,0x8c,0x8f,0x8c,0x0b,0xdd,0x2a,0xbc,0x89,0x8d,0x2f,0x8d,0x10,0x8d,0x31,0x9d,0x92,0x43,0x89,0x74,0x6e,0x32,0x26,0x5b,0x4a,0x64,0x6d,0x95,0x52,0x9d,0x93,0x74,0x8f,0x63,0xac,0x7c,0xcf,0x74,0xae,0xb5,0xf4,0x63,0xac,0x85,0x11,0x02,0x84,0x64,0x0b,0x63,0x2a,0x6b,0x4a,0x84,0x8e,0x0b,0x87,0x03,0xe6,0x04,0x06,0x2c,0x8a,0x34,0xab,0x4c,0xab,0x54,0xed,0x54,0x8c,0x74,0x8d,0xb5,0x4f,0x4b,0x89,0x2a,0xc6,0x94,0x8d,0x53,0xaa,0x4c,0x0a,0x2c,0x49,0x45,0x0c,0x3c,0xab,0x44,0xac,0x0c,0x28
,0x0c,0x07,0x03,0xc6,0x03,0xe6,0x03,0xe6,0x03,0xc6,0x0b,0xa5,0x33,0xe9,0x12,0x03,0x02,0x63,0x02,0x43,0x0a,0x24,0x02,0x23,0x43,0xa9,0x02,0xa4,0x02,0x43,0x02,0xa5,0x03,0x04,0x12,0x24,0x21,0x24,0x10,0x81,0x08,0x61,0x08,0x60,0x08,0x61,0x08,0x81,0x10,0x81,0x08,0x61,0x08,0x81,0x08,0xe1,0x1b,0x07,0x6b,0xcc,0x53,0x08,0x33,0x68,0x63,0xca,0x52,0xe7,0x94,0x6b,0xe5,0x8b,0xbc,0xca,0x6c,0xcd,0x3c,0x4b,0x4c,0xcd,0x1b,0xe8,0x3c,0x0a,0x4b,0xeb,0x13,0x46,0x03,0x45,0x2c,0x4a,0x3c,0x6b,0x24,0x6a,0x5c,0x8d,0x84,0xd0,0x64,0x6e,0x33,0xea,0x7c,0xcf,0x5b,0xec,0x5c,0xad,0x0a,0xe5,0x1a,0x45,0x19,0xc4,0x19,0xa4,0x1a,0x24,0x03,0x66,0x03,0xe6,0x03,0xe7,0x03,0xe7,0x03,0xe6,0x03,0xe6,0x03,0xe6,0x24,0x28,0x33,0xe8,0x0a,0x43,0x02,0x43,0x02,0x64,0x12,0x23,0x0a,0x64,0x4c,0x4b,0x03,0xe6,0x04,0x06,0x04,0x07,0x03,0xe7,0x04,0x07
,0x0c,0x07,0x2c,0x8a,0x34,0xaa,0x24,0x48,0x1c,0x28,0x1b,0xc6,0x64,0x2b,0x9c,0x8d,0x64,0x2b,0x0a,0x64,0x74,0x4d,0x4b,0x69,0x43,0xa9,0x43,0xca,0x3b,0xa9,0x2b,0x48,0x23,0x87,0x0a,0x45,0x19,0x23,0x10,0x81,0x08,0x60,0x08,0x60,0x08,0x60,0x08,0x81,0x10,0x81,0x08,0x60,0x10,0x81,0x08,0xe1,0x1b,0x06,0x74,0x0c,0x84,0x4e,0x33,0x68,0x7c,0x4d,0x84,0xaf,0x63,0xab,0x9c,0xef,0x7c,0x4e,0x85,0x50,0x34,0x4a,0x5c,0xed,0x13,0xa7,0x13,0x26,0x24,0x09,0x13,0xe7,0x24,0x29,0x3c,0xcc,0x2c,0x4a,0x44,0xcc,0x1b,0x87,0x2b,0xc9,0x1b,0xa7,0x03,0x05,0x5c,0xcd,0x7d,0x50,0x85,0x92,0x5b,0xab,0x5a,0xe9,0x42,0x47,0x3a,0x07,0x4a,0x87,0x12,0xe6,0x03,0xa6,0x03,0x05,0x3c,0x2a,0x34,0xab,0x34,0x8b,0x2c,0x69,0x24,0x08,0x6c,0x4c,0x9c,0xad,0x53,0xca,0x2b,0x07,0x9c,0xad,0x6c,0x6c,0x4c,0x8a,0x3c,0xaa,0x2c,0x69,0x3c,0xab,0x04,0x07,0x0c,0x08
,0x0c,0x07,0x44,0xec,0x4c,0xcd,0x44,0xcc,0x44,0xcc,0x34,0x69,0x74,0x8d,0x9c,0x6b,0x6c,0x4c,0x12,0x44,0x63,0x8a,0x2a,0x45,0x53,0xaa,0x53,0xeb,0x5c,0x6e,0x43,0xcb,0x3b,0xe9,0x0a,0x44,0x19,0x03,0x10,0xa1,0x08,0x60,0x08,0x60,0x10,0x81,0x08,0x81,0x10,0x81,0x10,0x81,0x10,0x81,0x08,0xe1,0x1b,0x26,0x5c,0x2c,0x53,0xab,0x2b,0x47,0x54,0x0b,0x54,0x0b,0x2b,0x27,0x2b,0xa7,0x2b,0xe8,0x3c,0x4a,0x2c,0x4a,0x3c,0x8b,0x0b,0x06,0x03,0x65,0x03,0xe6,0x2c,0x6b,0x65,0x4f,0x55,0x0e,0x34,0xab,0x54,0xad,0x03,0x05,0x03,0xa6,0x03,0x05,0x0a,0xe6,0x1b,0xa8,0x1b,0x47,0x23,0x07,0x42,0xc8,0x52,0x89,0x3a,0x06,0x3a,0x06,0x5a,0xe9,0x12,0xe6,0x84,0xf0,0x54,0x8c,0x4c,0x8c,0x44,0xcd,0x75,0x90,0x3c,0xec,0x1c,0x28,0x74,0x4d,0xac,0xcd,0x5c,0x0a,0x3b,0x47,0x9c,0xad,0x74,0x2c,0x44,0x6a,0x44,0xcb,0x65,0x4e,0x5d,0x4e,0x0b,0xe8,0x0c,0x08
,0x0c,0x07,0x04,0x06,0x03,0xe6,0x03,0xe6,0x03,0xc6,0x0b,0xa5,0x33,0xc9,0x22,0xa5,0x0a,0x64,0x02,0x63,0x0a,0x03,0x02,0x03,0x3b,0x88,0x03,0x04,0x02,0xc4,0x02,0xa4,0x02,0xe4,0x0a,0x44,0x19,0x03,0x10,0xa1,0x08,0x60,0x08,0x60,0x08,0x61,0x10,0x81,0x10,0x81,0x08,0x61,0x10,0x81,0x00,0xc1,0x1a,0xc6,0x43,0x8a,0x5b,0xec,0x3b,0x49,0x3b,0xc9,0x2b,0x88,0x1b,0x07,0x33,0xe9,0x5c,0xcd,0x34,0x4a,0x03,0x87,0x02,0xe5,0x03,0x65,0x03,0xe6,0x03,0xe6,0x03,0xc7,0x03,0xe7,0x03,0xe7,0x0b,0x66,0x13,0x26,0x03,0xa7,0x03,0xa7,0x02,0xe5,0x2b,0x89,0x9d,0x52,0xa5,0x93,0x84,0xf1,0x53,0x4b,0x42,0x28,0x3a,0x27,0x3a,0x27,0x3a,0x27,0x1a,0xa6,0x94,0x8e,0x5c,0x2c,0x03,0x66,0x04,0x07,0x03,0xe6,0x03,0xe6,0x1c,0x47,0x2b,0xc9,0x1a,0xa5,0x02,0x64,0x02,0x84,0x1a,0xa5,0x12,0xe5,0x3c,0xcb,0x03,0xe6,0x03,0xe6,0x04,0x06,0x04,0x07,0x04,0x08
,0x04,0x06,0x0c,0x27,0x14,0x07,0x0b,0xc6,0x0b,0xe6,0x13,0xc6,0x53,0xea,0x7c,0x2b,0x4b,0xc9,0x12,0x85,0x6c,0x0c,0x1a,0x45,0x43,0xc9,0x23,0xc8,0x2b,0x68,0x1b,0x06,0x13,0x46,0x1a,0x25,0x19,0x03,0x10,0xa1,0x08,0x60,0x08,0x61,0x08,0x61,0x10,0x81,0x10,0x81,0x10,0x81,0x10,0x81,0x08,0xc1,0x1a,0xc5,0x1b,0x27,0x2b,0x68,0x23,0x07,0x54,0x8c,0x54,0x4c,0x13,0x88,0x1b,0xe9,0x24,0x29,0x13,0xe8,0x03,0x05,0x03,0x66,0x03,0xc6,0x03,0xa5,0x03,0xc6,0x03,0xa6,0x0b,0xc7,0x0b,0x06,0x12,0xc6,0x03,0x46,0x03,0xa7,0x03,0xa7,0x02,0xe5,0x2b,0x68,0x53,0x09,0x84,0xaf,0x53,0x29,0x53,0x4b,0x42,0x68,0x42,0x68,0x42,0x47,0x3a,0x27,0x1b,0x07,0x8c,0xd0,0x5c,0xcd,0x24,0x89,0x2c,0x8a,0x2c,0x8a,0x14,0x48,0x1c,0x28,0x54,0x0b,0x84,0x4c,0x3b,0x48,0x22,0xe6,0x7c,0x2c,0x4b,0xa9,0x3c,0x8a,0x2c,0x69,0x24,0x49,0x2c,0x8a,0x04,0x07,0x04,0x08
,0x04,0x27,0x5d,0x2e,0x5c,0xed,0x54,0xed,0x3c,0x8b,0x44,0x8b,0x84,0xce,0x9c,0x4b,0x74,0x4c,0x2b,0x07,0x63,0x69,0x2a,0x66,0x4b,0xea,0x54,0x8c,0x64,0xce,0x4b,0xca,0x64,0x8c,0x1a,0x04,0x19,0x23,0x08,0xa1,0x08,0x60,0x08,0x60,0x08,0x61,0x08,0x61,0x10,0x81,0x10,0x81,0x10,0x81,0x00,0xc1,0x13,0x26,0x13,0x05,0x02,0x63,0x02,0xe4,0x03,0x65,0x03,0x25,0x03,0x66,0x03,0x86,0x03,0xa6,0x02,0xe5,0x03,0x46,0x03,0x86,0x03,0x65,0x03,0x24,0x03,0x04,0x0b,0x05,0x43,0xaa,0x74,0x6e,0x4b,0xcb,0x02,0x84,0x03,0x25,0x03,0x66,0x02,0xe5,0x2b,0xa8,0x7d,0x10,0x95,0x72,0x8d,0x71,0x53,0x4a,0x4a,0x68,0x4a,0x48,0x4a,0x89,0x4a,0x69,0x13,0x27,0x3c,0x6b,0x2c,0x49,0x4c,0xed,0x5d,0x2e,0x5d,0x0e,0x3c,0xcc,0x1c,0x29,0x7c,0xae,0xac,0xab,0x6c,0x2b,0x43,0x68,0x9c,0x2b,0x7c,0x4c,0x44,0x6a,0x5c,0xed,0x4c,0xcc,0x75,0x8f,0x03,0xe7,0x04,0x28
,0x04,0x27,0x0c,0x08,0x14,0x49,0x14,0x28,0x1c,0x49,0x1b,0xc7,0x43,0xc9,0x4b,0x89,0x1a,0xa6,0x02,0x44,0x2a,0xa6,0x12,0xa5,0x3c,0x09,0x03,0x45,0x0a,0xe5,0x12,0xc5,0x02,0xe4,0x0a,0x24,0x21,0x44,0x08,0x81,0x08,0x60,0x08,0x61,0x08,0x81,0x10,0x81,0x08,0x81,0x10,0x81,0x10,0x81,0x00,0xe1,0x1b,0x26,0x12,0xa5,0x02,0xc4,0x03,0x65,0x03,0x86,0x03,0x05,0x03,0x66,0x03,0x46,0x02,0xe5,0x03,0x45,0x03,0xa6,0x03,0x65,0x02,0xe4,0x02,0x82,0x02,0x83,0x02,0x44,0x2a,0xc7,0x1a,0x66,0x22,0x86,0x02,0x43,0x02,0xc4,0x03,0x26,0x02,0xc5,0x1b,0xa8,0x34,0x4b,0x0a,0xc5,0x6d,0x0f,0x43,0x69,0x52,0xe9,0x4a,0xe9,0x4a,0xe9,0x4a,0xe9,0x3c,0x2b,0x65,0x50,0x6d,0xb1,0x0c,0x08,0x0c,0x08,0x0c,0x08,0x03,0xe7,0x1c,0x29,0x33,0xe9,0x43,0x88,0x0a,0xa5,0x02,0x84,0x43,0x28,0x1b,0x06,0x3c,0xab,0x03,0xe6,0x0c,0x07,0x0c,0x07,0x04,0x07,0x04,0x28
,0x04,0x27,0x13,0xe8,0x13,0xe8,0x0b,0xe7,0x0b,0xe7,0x13,0xa7,0x4b,0xc9,0x63,0xaa,0x2a,0xe6,0x02,0x44,0x3b,0x08,0x1a,0x85,0x3c,0x0a,0x0b,0x45,0x13,0x05,0x0a,0xa4,0x02,0xe4,0x0a,0x25,0x21,0x44,0x10,0x81,0x08,0x60,0x08,0x61,0x08,0x61,0x08,0x60,0x08,0x40,0x10,0x81,0x08,0x81,0x08,0xc2,0x1a,0x86,0x33,0x69,0x2b,0xc8,0x23,0xe8,0x03,0x05,0x03,0x47,0x02,0xe5,0x02,0xc4,0x03,0x26,0x03,0xa7,0x03,0xa6,0x03,0x86,0x0a,0xc5,0x32,0x86,0x63,0xaa,0x74,0x4e,0x7c,0x6f,0x74,0x6f,0x6c,0x0d,0x6b,0xec,0x22,0xa5,0x0a,0xe6,0x02,0xc6,0x2b,0xe9,0x5c,0xce,0x0b,0x26,0x85,0xb2,0x0b,0x46,0x23,0x47,0x5c,0x8c,0x1a,0xe5,0x0a,0x64,0x03,0xa7,0x0b,0xe8,0x0c,0x08,0x14,0x48,0x14,0x28,0x14,0x28,0x0c,0x07,0x1c,0x28,0x4c,0x0a,0x63,0xeb,0x22,0xe6,0x12,0xa5,0x5b,0xaa,0x33,0x47,0x3c,0x8b,0x14,0x07,0x0c,0x06,0x14,0x48,0x03,0xe7,0x04,0x28
,0x04,0x27,0x65,0x2e,0x5c,0xee,0x5d,0x0d,0x55,0x0d,0x34,0x29,0x8c,0xef,0x94,0x0c,0x7c,0x2c,0x12,0x65,0x6b,0xaa,0x32,0xa7,0x43,0xea,0x85,0x50,0x53,0xea,0x12,0x84,0x02,0xc5,0x0a,0x65,0x21,0x65,0x08,0x81,0x08,0x81,0x08,0x81,0x08,0x81,0x08,0x61,0x08,0x40,0x08,0x60,0x08,0x61,0x08,0xa1,0x1a,0xa5,0x33,0xca,0x4c,0x6d,0x54,0xad,0x44,0x2b,0x33,0xca,0x1b,0x28,0x4b,0xeb,0x44,0xcc,0x03,0xa7,0x03,0xa7,0x0b,0x87,0x74,0xae,0xbe,0x15,0xad,0x73,0x94,0xb1,0xbe,0x16,0xbe,0x16,0x84,0x2f,0xc6,0x16,0xbe,0x36,0x5c,0x2d,0x03,0x06,0x34,0x6b,0x55,0x2e,0x03,0x66,0x44,0x8d,0x02,0xe5,0x13,0xc7,0x1b,0xa7,0x03,0x86,0x03,0x86,0x03,0xe7,0x03,0xe7,0x04,0x07,0x55,0x0d,0x6d,0x4f,0x5d,0x0e,0x2c,0x8a,0x1c,0x27,0x8c,0x8e,0x9c,0x0b,0x74,0x4c,0x4b,0x89,0x9c,0x09,0x84,0x8d,0x44,0x6a,0x65,0x2e,0x44,0xca,0x44,0xcc,0x04,0x07,0x04,0x08
,0x04,0x27,0x0c,0x28,0x24,0x69,0x24,0x48,0x2c,0x69,0x1b,0xe7,0x4b,0xea,0x6b,0xeb,0x33,0x67,0x02,0xe4,0x3a,0xe7,0x1a,0x85,0x3c,0x0a,0x1b,0xc7,0x23,0xa6,0x02,0xc4,0x02,0xa4,0x0a,0x64,0x29,0x85,0x08,0x81,0x10,0x81,0x08,0x81,0x08,0x61,0x08,0x60,0x08,0x60,0x08,0x61,0x08,0x61,0x08,0xc1,0x13,0x26,0x2b,0xa9,0x2b,0xc9,0x4c,0x2b,0x75,0x10,0x5c,0x8e,0x23,0x28,0x64,0x4e,0x2c,0x49,0x03,0xc6,0x03,0x86,0x1b,0x87,0x7c,0x8e,0xa5,0x73,0x8c,0x90,0x9d,0x32,0xbe,0x16,0xb5,0xb5,0x9d,0x12,0xa5,0x53,0xbe,0x36,0x6c,0x8d,0x13,0xa7,0x3c,0x8b,0x55,0x0d,0x3c,0x2a,0x2b,0xea,0x1b,0x47,0x34,0x4a,0x1b,0xa8,0x03,0x87,0x03,0x87,0x03,0xa7,0x03,0xa7,0x03,0xc7,0x14,0x48,0x14,0x48,0x24,0x89,0x14,0x27,0x1c,0x28,0x3b,0xc9,0x64,0x0b,0x23,0x27,0x13,0x05,0x74,0x0a,0x33,0x68,0x3c,0xab,0x0c,0x07,0x24,0x69,0x0c,0x48,0x04,0x07,0x0c,0x08
,0x04,0x27,0x04,0x06,0x04,0x06,0x03,0xe6,0x03,0xc6,0x0b,0xa6,0x44,0x49,0x43,0xc8,0x23,0xc8,0x03,0x46,0x22,0xc6,0x0a,0xc4,0x34,0x4a,0x03,0x65,0x03,0x44,0x02,0xc3,0x02,0x83,0x0a,0x45,0x21,0x44,0x08,0x81,0x10,0x81,0x10,0x81,0x10,0x81,0x08,0x81,0x08,0x61,0x08,0x61,0x08,0x61,0x08,0xc1,0x1b,0x26,0x73,0xec,0x7c,0x6f,0x6c,0x4e,0x8c,0xd0,0x43,0xaa,0x3b,0x8a,0xa5,0x73,0x4c,0x4d,0x03,0xc7,0x1b,0x87,0x8c,0xd0,0x9d,0x11,0xad,0x94,0xad,0xb4,0xad,0xb4,0xa5,0x33,0x9c,0xd1,0xb5,0xf5,0xbe,0x16,0xbe,0x15,0x9d,0x52,0x6c,0xaf,0x3c,0x4b,0x65,0x0e,0xad,0xb3,0x9d,0x71,0x5c,0x2c,0xbe,0x14,0x5c,0xce,0x03,0xa7,0x03,0xc7,0x03,0xa7,0x03,0xa7,0x03,0x87,0x03,0x86,0x03,0xe6,0x04,0x07,0x03,0xe7,0x1c,0x28,0x34,0x69,0x44,0x09,0x13,0xa6,0x0b,0xa6,0x4b,0xe9,0x23,0xa7,0x3c,0xcb,0x03,0xe6,0x03,0xe6,0x04,0x07,0x04,0x07,0x0c,0x28
,0x04,0x27,0x4c,0xcb,0x65,0x4e,0x65,0x0e,0x65,0x2e,0x0b,0xc6,0x95,0x70,0x9c,0xad,0x85,0x2f,0x13,0x87,0x5b,0x68,0x33,0x48,0x4c,0x8b,0x54,0xac,0x5c,0xad,0x4c,0x0a,0x22,0xe6,0x0a,0x65,0x29,0xa5,0x10,0xa2,0x08,0x61,0x08,0x61,0x08,0x61,0x10,0x81,0x10,0x81,0x08,0x61,0x08,0x61,0x08,0xc1,0x1b,0x07,0x53,0x2a,0x3a,0xa8,0x5b,0xab,0x63,0x09,0x64,0x4e,0x7c,0xcf,0xc5,0xf3,0x3b,0xc9,0x03,0xc6,0x23,0x88,0xa5,0x32,0xa5,0x32,0xad,0x94,0xad,0x94,0xad,0x94,0x94,0xd1,0x7c,0x0e,0x94,0xd1,0xad,0x93,0xbd,0xf5,0xc6,0x56,0x8d,0x30,0x03,0x86,0x85,0x70,0xb5,0xb1,0xad,0xb2,0x53,0xeb,0x73,0x8a,0x4b,0xea,0x6d,0x0f,0x64,0xcf,0x34,0x4a,0x03,0x86,0x03,0x86,0x4c,0xab,0x75,0x4f,0x6d,0x4f,0x6d,0x6f,0x24,0x48,0x8d,0x4f,0x94,0x2a,0x75,0x2e,0x54,0xab,0xa4,0x4c,0x8d,0x0f,0x3c,0xab,0x5d,0x2d,0x64,0xed,0x6d,0x6f,0x3c,0xec,0x0c,0x28
,0x04,0x27,0x34,0x6a,0x44,0xcb,0x3c,0xab,0x3c,0xcb,0x0b,0xc6,0x6c,0xed,0xad,0xf3,0x5c,0xee,0x1c,0x08,0x7c,0xad,0x3b,0xc9,0x44,0x6b,0x3c,0x8a,0x2b,0xe8,0x33,0xa8,0x1b,0x26,0x0a,0x65,0x29,0xa5,0x10,0xa1,0x08,0x60,0x08,0x40,0x08,0x60,0x10,0x81,0x10,0x81,0x08,0x61,0x08,0x81,0x08,0xc1,0x1b,0x06,0x6c,0x0c,0x63,0xcc,0x6c,0x2d,0x84,0x8e,0x5c,0x6d,0x64,0x6d,0xad,0x93,0x4c,0x6b,0x03,0xe6,0x23,0x87,0xb5,0xb4,0x94,0xf1,0xad,0xb4,0xad,0xb5,0xa5,0x74,0xa5,0x74,0x9d,0x12,0xa5,0x53,0xb5,0x74,0xb5,0xf5,0xb5,0x94,0x95,0x72,0x03,0xc6,0x44,0x8b,0xad,0xd2,0xad,0xd2,0x74,0xad,0x9c,0xd0,0x54,0xad,0x1c,0x49,0x24,0x4a,0x0c,0x27,0x04,0x06,0x04,0x07,0x24,0x6a,0x3c,0xcc,0x2c,0x8a,0x44,0xec,0x1c,0x28,0x64,0xed,0x9d,0x30,0x44,0x8c,0x2c,0x29,0xa5,0x0f,0x5c,0x8c,0x3c,0xab,0x44,0xca,0x2c,0x49,0x4d,0x0c,0x2c,0x8a,0x0c,0x28
,0x04,0x27,0x03,0xc6,0x03,0xe7,0x04,0x07,0x03,0xe6,0x03,0xc6,0x4c,0xac,0x4c,0x6b,0x44,0xab,0x44,0xab,0x3c,0x2a,0x3c,0x4a,0x2c,0x29,0x03,0xa5,0x03,0x65,0x03,0x24,0x03,0x04,0x1a,0xa6,0x29,0x85,0x10,0xa2,0x08,0x81,0x08,0x81,0x08,0x61,0x10,0x81,0x10,0x81,0x08,0x61,0x08,0x81,0x08,0xe2,0x2b,0x47,0x5c,0x8c,0x54,0x4b,0x64,0xcd,0x64,0xad,0x34,0x09,0x3c,0x4a,0x5c,0x8c,0x34,0x4a,0x03,0xa6,0x0b,0xa6,0x2b,0xe9,0x8d,0x10,0xb5,0xb4,0xb5,0xb4,0xad,0xb4,0xad,0x94,0xad,0xb4,0xad,0x94,0xb5,0xb5,0xbd,0xf5,0x7c,0xef,0x1b,0xc8,0x03,0xe6,0x0c,0x07,0x64,0xee,0x64,0xad,0x4c,0xcd,0x6c,0xef,0x44,0xac,0x04,0x06,0x04,0x07,0x04,0x07,0x04,0x07,0x03,0xe7,0x04,0x28,0x04,0x07,0x04,0x07,0x04,0x27,0x0c,0x28,0x55,0x0d,0x4c,0xcc,0x44,0xcc,0x4c,0xcc,0x4c,0xac,0x44,0xcc,0x24,0x8a,0x04,0x07,0x04,0x07,0x04,0x07,0x03,0xe7,0x0c,0x28
,0xbe,0xd8,0xb6,0x97,0xae,0x77,0xae,0x77,0xae,0x77,0xa6,0x76,0xa6,0x56,0xa6,0x56,0xa6,0x56,0xa6,0x56,0xa6,0x56,0xa6,0x35,0xa6,0x56,0xa6,0x56,0xa6,0x35,0xa6,0x35,0xa6,0x35,0x9d,0x73,0x18,0xe2,0x10,0xa1,0x10,0x81,0x10,0x81,0x10,0x61,0x10,0x61,0x10,0x81,0x10,0xa1,0x18,0xc2,0x31,0xe6,0xc6,0xb8,0xae,0x56,0xa6,0x56,0xa6,0x56,0xa6,0x36,0xa6,0x36,0xa6,0x56,0xa6,0x56,0xa6,0x56,0xa6,0x76,0xa6,0x56,0xae,0x77,0xd6,0xd9,0xf7,0x9d,0xef,0x5c,0xef,0x7c,0xef,0x7c,0xef,0x7c,0xef,0x7c,0xf7,0x9d,0xef,0x5c,0xd6,0xfa,0xa6,0x56,0xa6,0x56,0xa6,0x56,0xa6,0x76,0xa6,0x76,0xa6,0x76,0xa6,0x76,0xa6,0x76,0xae,0x76,0xa6,0x77,0xa6,0x56,0x9e,0x76,0x9e,0x76,0x9e,0x76,0xa6,0x76,0xa6,0x76,0x9e,0x76,0x9e,0x56,0x9e,0x56,0x9e,0x55,0x9e,0x55,0x9e,0x55,0x9e,0x56,0x9e,0x55,0x9e,0x56,0xa6,0x56,0xa6,0x56,0xa6,0x76,0xae,0x77,0xae,0x77
,0xff,0xff,0xff,0xff,0xff,0xff,0xff,0xff,0xff,0xff,0xff,0xff,0xff,0xff,0xff,0xff,0xff,0xff,0xff,0xff,0xff,0xff,0xff,0xff,0xff,0xff,0xff,0xff,0xff,0xff,0xff,0xff,0xff,0xff,0xff,0xdf,0x7b,0xcd,0x31,0x85,0x29,0x64,0x10,0x81,0x10,0xa2,0x29,0x64,0x39,0xe6,0xce,0x58,0xf7,0xbe,0xf7,0xbe,0xff,0xff,0xff,0xff,0xff,0xff,0xff,0xff,0xff,0xff,0xff,0xff,0xff,0xff,0xff,0xff,0xff,0xff,0xff,0xff,0xff,0xff,0xff,0xff,0xff,0xff,0xff,0xff,0xff,0xff,0xff,0xff,0xff,0xff,0xff,0xff,0xff,0xff,0xff,0xff,0xff,0xff,0xff,0xff,0xff,0xff,0xff,0xff,0xff,0xff,0xff,0xff,0xff,0xff,0xff,0xff,0xff,0xff,0xff,0xff,0xff,0xff,0xff,0xff,0xff,0xff,0xff,0xff,0xff,0xff,0xff,0xff,0xff,0xff,0xff,0xff,0xff,0xff,0xff,0xff,0xff,0xff,0xff,0xff,0xff,0xff,0xff,0xff,0xff,0xff,0xff,0xff,0xff,0xff,0xff,0xff,0xff,0xff,0xff,0xff,0xff,0xff,0xff,0xff
,0xff,0xff,0xff,0xff,0xff,0xff,0xff,0xff,0xff,0xff,0xff,0xff,0xff,0xff,0xff,0xff,0xff,0xff,0xff,0xff,0xff,0xff,0xff,0xff,0xff,0xff,0xff,0xff,0xff,0xff,0xff,0xff,0xff,0xff,0xff,0xff,0x84,0x0e,0x31,0xa5,0x29,0x44,0x08,0x81,0x08,0x81,0x29,0x64,0x3a,0x07,0xd6,0x99,0xff,0xff,0xff,0xff,0xff,0xff,0xff,0xff,0xff,0xff,0xff,0xff,0xff,0xff,0xff,0xff,0xff,0xff,0xff,0xff,0xff,0xff,0xff,0xff,0xff,0xff,0xff,0xff,0xff,0xff,0xff,0xff,0xff,0xff,0xff,0xff,0xff,0xff,0xff,0xff,0xff,0xff,0xff,0xff,0xff,0xff,0xff,0xff,0xff,0xff,0xff,0xff,0xff,0xff,0xff,0xff,0xff,0xff,0xff,0xff,0xff,0xff,0xff,0xff,0xff,0xff,0xff,0xff,0xff,0xff,0xff,0xff,0xff,0xff,0xff,0xff,0xff,0xff,0xff,0xff,0xff,0xff,0xff,0xff,0xff,0xff,0xff,0xff,0xff,0xff,0xff,0xff,0xff,0xff,0xff,0xff,0xff,0xff,0xff,0xff,0xff,0xff,0xff,0xff,0xff,0xff,0xff,0xff
,0xff,0xff,0xff,0xff,0xff,0xff,0xff,0xff,0xff,0xff,0xff,0xff,0xff,0xff,0xff,0xff,0xff,0xff,0xff,0xff,0xff,0xff,0xff,0xff,0xff,0xff,0xff,0xff,0xff,0xff,0xff,0xff,0xff,0xff,0xff,0xff,0x84,0x0f,0x31,0xa5,0x29,0x44,0x08,0x81,0x10,0xa1,0x29,0x64,0x3a,0x06,0xd6,0x99,0xff,0xff,0xff,0xff,0xff,0xff,0xff,0xff,0xff,0xff,0xff,0xff,0xff,0xff,0xff,0xff,0xff,0xff,0xff,0xff,0xff,0xff,0xff,0xff,0xff,0xff,0xff,0xff,0xff,0xff,0xff,0xff,0xff,0xff,0xff,0xff,0xff,0xff,0xff,0xff,0xff,0xff,0xff,0xff,0xff,0xff,0xff,0xff,0xff,0xff,0xff,0xff,0xff,0xff,0xff,0xff,0xff,0xff,0xff,0xff,0xff,0xff,0xff,0xff,0xff,0xff,0xff,0xff,0xff,0xff,0xff,0xff,0xff,0xff,0xff,0xff,0xff,0xff,0xff,0xff,0xff,0xff,0xff,0xff,0xff,0xff,0xff,0xff,0xff,0xff,0xff,0xff,0xff,0xff,0xff,0xff,0xff,0xff,0xff,0xff,0xff,0xff,0xff,0xff,0xff,0xff,0xff,0xff
,0xff,0xff,0xff,0xff,0xff,0xff,0xff,0xff,0xff,0xff,0xff,0xff,0xff,0xff,0xff,0xff,0xff,0xff,0xff,0xff,0xff,0xff,0xff,0xff,0xff,0xff,0xff,0xff,0xff,0xff,0xff,0xff,0xff,0xff,0xff,0xff,0x7c,0x0e,0x31,0xa5,0x29,0x44,0x10,0xa1,0x10,0xa2,0x29,0x64,0x42,0x06,0xd6,0x99,0xff,0xff,0xff,0xff,0xff,0xff,0xff,0xff,0xff,0xff,0xff,0xff,0xff,0xff,0xff,0xff,0xff,0xff,0xff,0xff,0xff,0xff,0xff,0xff,0xff,0xff,0xff,0xff,0xff,0xff,0xff,0xff,0xff,0xff,0xff,0xff,0xff,0xff,0xff,0xff,0xff,0xff,0xff,0xff,0xff,0xff,0xff,0xff,0xff,0xff,0xff,0xff,0xff,0xff,0xff,0xff,0xff,0xff,0xff,0xff,0xff,0xff,0xff,0xff,0xff,0xff,0xff,0xff,0xff,0xff,0xff,0xff,0xff,0xff,0xff,0xff,0xff,0xff,0xff,0xff,0xff,0xff,0xff,0xff,0xff,0xff,0xff,0xff,0xff,0xff,0xff,0xff,0xff,0xff,0xff,0xff,0xff,0xff,0xff,0xff,0xff,0xff,0xff,0xff,0xff,0xff,0xff,0xff
,0xff,0xff,0xff,0xff,0xff,0xff,0xff,0xff,0xff,0xff,0xff,0xff,0xff,0xff,0xff,0xff,0xff,0xff,0xff,0xff,0xff,0xff,0xff,0xff,0xff,0xff,0xff,0xff,0xff,0xff,0xff,0xff,0xff,0xff,0xff,0xff,0x8c,0x50,0x39,0xe6,0x31,0x85,0x18,0xe2,0x21,0x03,0x31,0xa5,0x4a,0x47,0xd6,0xba,0xff,0xff,0xff,0xff,0xff,0xff,0xff,0xff,0xff,0xff,0xff,0xff,0xff,0xff,0xff,0xff,0xff,0xff,0xff,0xff,0xff,0xff,0xff,0xff,0xff,0xff,0xff,0xff,0xff,0xff,0xff,0xff,0xff,0xff,0xff,0xff,0xff,0xff,0xff,0xff,0xff,0xff,0xff,0xff,0xff,0xff,0xff,0xff,0xff,0xff,0xff,0xff,0xff,0xff,0xff,0xff,0xff,0xff,0xff,0xff,0xff,0xff,0xff,0xff,0xff,0xff,0xff,0xff,0xff,0xff,0xff,0xff,0xff,0xff,0xff,0xff,0xff,0xff,0xff,0xff,0xff,0xff,0xff,0xff,0xff,0xff,0xff,0xff,0xff,0xff,0xff,0xff,0xff,0xff,0xff,0xff,0xff,0xff,0xff,0xff,0xff,0xff,0xff,0xff,0xff,0xff,0xff,0xff

};
/* USER CODE END 0 */

int main(void)
{

  /* MCU Configuration--------------------------------------------------------*/

  /* Reset of all peripherals, Initializes the Flash interface and the Systick. */
  HAL_Init();

  /* Configure the system clock */
  SystemClock_Config();

  /* Initialize all configured peripherals */
  MX_GPIO_Init();
  MX_DMA2D_Init();
  MX_FMC_Init();
  MX_I2C3_Init();
  MX_LTDC_Init();
  MX_SPI5_Init();
  /* USER CODE BEGIN 2 */
    //HAL_GPIO_WritePin(RST_GPIO_Port, RST_Pin, GPIO_PIN_RESET);
  	//HAL_Delay(10);
  	//HAL_GPIO_WritePin(RST_GPIO_Port, RST_Pin, GPIO_PIN_SET);

  	ILI9341_Init();
  	ILI9341_setRotation(3);

  	ILI9341_Fill(COLOR_WHITE);

  	//Draw and fill circle
  	ILI9341_drawCircle(50,50, 40, COLOR_GREEN);
  	ILI9341_fillCircle(110,190, 80, COLOR_RED);
  	//Print text
  	ILI9341_printText("HELLO", 60, 90, COLOR_YELLOW, COLOR_YELLOW, 5);
  	//Print-Fill triangle
  	ILI9341_fillTriangle(10, 160, 110, 160, 190, 300, COLOR_BLACK);

  	HAL_Delay(1000);

  	ILI9341_printImage(50, 50, 80, 130, myImage, sizeof(myImage));
  /* USER CODE END 2 */

  /* Infinite loop */
  while (1)
  {

  }
}

void SystemClock_Config(void)
{
  RCC_OscInitTypeDef RCC_OscInitStruct = {0};
  RCC_ClkInitTypeDef RCC_ClkInitStruct = {0};
  RCC_PeriphCLKInitTypeDef PeriphClkInitStruct = {0};

  /** Macro to configure the PLL multiplication factor
  */
  __HAL_RCC_PLL_PLLM_CONFIG(16);
  /** Macro to configure the PLL clock source
  */
  __HAL_RCC_PLL_PLLSOURCE_CONFIG(RCC_PLLSOURCE_HSI);
  /** Configure the main internal regulator output voltage
  */
  __HAL_RCC_PWR_CLK_ENABLE();
  __HAL_PWR_VOLTAGESCALING_CONFIG(PWR_REGULATOR_VOLTAGE_SCALE3);
  /** Initializes the RCC Oscillators according to the specified parameters
  * in the RCC_OscInitTypeDef structure.
  */
  RCC_OscInitStruct.OscillatorType = RCC_OSCILLATORTYPE_HSI;
  RCC_OscInitStruct.HSIState = RCC_HSI_ON;
  RCC_OscInitStruct.HSICalibrationValue = RCC_HSICALIBRATION_DEFAULT;
  RCC_OscInitStruct.PLL.PLLState = RCC_PLL_NONE;
  RCC_OscInitStruct.PLL.PLLSource = RCC_PLLSOURCE_HSI;
  if (HAL_RCC_OscConfig(&RCC_OscInitStruct) != HAL_OK)
  {
    Error_Handler();
  }
  /** Initializes the CPU, AHB and APB buses clocks
  */
  RCC_ClkInitStruct.ClockType = RCC_CLOCKTYPE_HCLK|RCC_CLOCKTYPE_SYSCLK
                              |RCC_CLOCKTYPE_PCLK1|RCC_CLOCKTYPE_PCLK2;
  RCC_ClkInitStruct.SYSCLKSource = RCC_SYSCLKSOURCE_HSI;
  RCC_ClkInitStruct.AHBCLKDivider = RCC_SYSCLK_DIV1;
  RCC_ClkInitStruct.APB1CLKDivider = RCC_HCLK_DIV1;
  RCC_ClkInitStruct.APB2CLKDivider = RCC_HCLK_DIV1;

  if (HAL_RCC_ClockConfig(&RCC_ClkInitStruct, FLASH_LATENCY_0) != HAL_OK)
  {
    Error_Handler();
  }
  PeriphClkInitStruct.PeriphClockSelection = RCC_PERIPHCLK_LTDC;
  PeriphClkInitStruct.PLLSAI.PLLSAIN = 432;
  PeriphClkInitStruct.PLLSAI.PLLSAIR = 2;
  PeriphClkInitStruct.PLLSAIDivR = RCC_PLLSAIDIVR_2;
  if (HAL_RCCEx_PeriphCLKConfig(&PeriphClkInitStruct) != HAL_OK)
  {
    Error_Handler();
  }
}

static void MX_DMA2D_Init(void)
{

  hdma2d.Instance = DMA2D;
  hdma2d.Init.Mode = DMA2D_M2M;
  hdma2d.Init.ColorMode = DMA2D_OUTPUT_RGB565;
  hdma2d.Init.OutputOffset = 0;
  hdma2d.LayerCfg[1].InputOffset = 0;
  hdma2d.LayerCfg[1].InputColorMode = DMA2D_INPUT_RGB565;
  hdma2d.LayerCfg[1].AlphaMode = DMA2D_NO_MODIF_ALPHA;
  hdma2d.LayerCfg[1].InputAlpha = 0;
  if (HAL_DMA2D_Init(&hdma2d) != HAL_OK)
  {
    Error_Handler();
  }
  if (HAL_DMA2D_ConfigLayer(&hdma2d, 1) != HAL_OK)
  {
    Error_Handler();
  }

}

static void MX_I2C3_Init(void)
{

  hi2c3.Instance = I2C3;
  hi2c3.Init.ClockSpeed = 100000;
  hi2c3.Init.DutyCycle = I2C_DUTYCYCLE_2;
  hi2c3.Init.OwnAddress1 = 0;
  hi2c3.Init.AddressingMode = I2C_ADDRESSINGMODE_7BIT;
  hi2c3.Init.DualAddressMode = I2C_DUALADDRESS_DISABLE;
  hi2c3.Init.OwnAddress2 = 0;
  hi2c3.Init.GeneralCallMode = I2C_GENERALCALL_DISABLE;
  hi2c3.Init.NoStretchMode = I2C_NOSTRETCH_DISABLE;
  if (HAL_I2C_Init(&hi2c3) != HAL_OK)
  {
    Error_Handler();
  }
  /** Configure Analogue filter
  */
  if (HAL_I2CEx_ConfigAnalogFilter(&hi2c3, I2C_ANALOGFILTER_ENABLE) != HAL_OK)
  {
    Error_Handler();
  }
  /** Configure Digital filter
  */
  if (HAL_I2CEx_ConfigDigitalFilter(&hi2c3, 0) != HAL_OK)
  {
    Error_Handler();
  }

}

static void MX_LTDC_Init(void)
{

  LTDC_LayerCfgTypeDef pLayerCfg = {0};
  LTDC_LayerCfgTypeDef pLayerCfg1 = {0};

  hltdc.Instance = LTDC;
  hltdc.Init.HSPolarity = LTDC_HSPOLARITY_AL;
  hltdc.Init.VSPolarity = LTDC_VSPOLARITY_AL;
  hltdc.Init.DEPolarity = LTDC_DEPOLARITY_AL;
  hltdc.Init.PCPolarity = LTDC_PCPOLARITY_IPC;
  hltdc.Init.HorizontalSync = 7;
  hltdc.Init.VerticalSync = 3;
  hltdc.Init.AccumulatedHBP = 14;
  hltdc.Init.AccumulatedVBP = 5;
  hltdc.Init.AccumulatedActiveW = 334;
  hltdc.Init.AccumulatedActiveH = 245;
  hltdc.Init.TotalWidth = 340;
  hltdc.Init.TotalHeigh = 247;
  hltdc.Init.Backcolor.Blue = 0;
  hltdc.Init.Backcolor.Green = 0;
  hltdc.Init.Backcolor.Red = 0;
  if (HAL_LTDC_Init(&hltdc) != HAL_OK)
  {
    Error_Handler();
  }
  pLayerCfg.WindowX0 = 0;
  pLayerCfg.WindowX1 = 0;
  pLayerCfg.WindowY0 = 0;
  pLayerCfg.WindowY1 = 0;
  pLayerCfg.PixelFormat = LTDC_PIXEL_FORMAT_ARGB8888;
  pLayerCfg.Alpha = 0;
  pLayerCfg.Alpha0 = 0;
  pLayerCfg.BlendingFactor1 = LTDC_BLENDING_FACTOR1_CA;
  pLayerCfg.BlendingFactor2 = LTDC_BLENDING_FACTOR2_CA;
  pLayerCfg.FBStartAdress = 0;
  pLayerCfg.ImageWidth = 0;
  pLayerCfg.ImageHeight = 0;
  pLayerCfg.Backcolor.Blue = 0;
  pLayerCfg.Backcolor.Green = 0;
  pLayerCfg.Backcolor.Red = 0;
  if (HAL_LTDC_ConfigLayer(&hltdc, &pLayerCfg, 0) != HAL_OK)
  {
    Error_Handler();
  }
  pLayerCfg1.WindowX0 = 0;
  pLayerCfg1.WindowX1 = 0;
  pLayerCfg1.WindowY0 = 0;
  pLayerCfg1.WindowY1 = 0;
  pLayerCfg1.PixelFormat = LTDC_PIXEL_FORMAT_ARGB8888;
  pLayerCfg1.Alpha = 0;
  pLayerCfg1.Alpha0 = 0;
  pLayerCfg1.BlendingFactor1 = LTDC_BLENDING_FACTOR1_CA;
  pLayerCfg1.BlendingFactor2 = LTDC_BLENDING_FACTOR2_CA;
  pLayerCfg1.FBStartAdress = 0;
  pLayerCfg1.ImageWidth = 0;
  pLayerCfg1.ImageHeight = 0;
  pLayerCfg1.Backcolor.Blue = 0;
  pLayerCfg1.Backcolor.Green = 0;
  pLayerCfg1.Backcolor.Red = 0;
  if (HAL_LTDC_ConfigLayer(&hltdc, &pLayerCfg1, 1) != HAL_OK)
  {
    Error_Handler();
  }

}

static void MX_SPI5_Init(void)
{

  /* SPI5 parameter configuration*/
  hspi5.Instance = SPI5;
  hspi5.Init.Mode = SPI_MODE_MASTER;
  hspi5.Init.Direction = SPI_DIRECTION_2LINES;
  hspi5.Init.DataSize = SPI_DATASIZE_8BIT;
  hspi5.Init.CLKPolarity = SPI_POLARITY_LOW;
  hspi5.Init.CLKPhase = SPI_PHASE_1EDGE;
  hspi5.Init.NSS = SPI_NSS_SOFT;
  hspi5.Init.BaudRatePrescaler = SPI_BAUDRATEPRESCALER_2;
  hspi5.Init.FirstBit = SPI_FIRSTBIT_MSB;
  hspi5.Init.TIMode = SPI_TIMODE_DISABLE;
  hspi5.Init.CRCCalculation = SPI_CRCCALCULATION_DISABLE;
  hspi5.Init.CRCPolynomial = 10;
  if (HAL_SPI_Init(&hspi5) != HAL_OK)
  {
    Error_Handler();
  }

}

/* FMC initialization function */
static void MX_FMC_Init(void)
{

  FMC_SDRAM_TimingTypeDef SdramTiming = {0};

  /** Perform the SDRAM1 memory initialization sequence
  */
  hsdram1.Instance = FMC_SDRAM_DEVICE;
  /* hsdram1.Init */
  hsdram1.Init.SDBank = FMC_SDRAM_BANK2;
  hsdram1.Init.ColumnBitsNumber = FMC_SDRAM_COLUMN_BITS_NUM_8;
  hsdram1.Init.RowBitsNumber = FMC_SDRAM_ROW_BITS_NUM_12;
  hsdram1.Init.MemoryDataWidth = FMC_SDRAM_MEM_BUS_WIDTH_16;
  hsdram1.Init.InternalBankNumber = FMC_SDRAM_INTERN_BANKS_NUM_4;
  hsdram1.Init.CASLatency = FMC_SDRAM_CAS_LATENCY_1;
  hsdram1.Init.WriteProtection = FMC_SDRAM_WRITE_PROTECTION_DISABLE;
  hsdram1.Init.SDClockPeriod = FMC_SDRAM_CLOCK_DISABLE;
  hsdram1.Init.ReadBurst = FMC_SDRAM_RBURST_DISABLE;
  hsdram1.Init.ReadPipeDelay = FMC_SDRAM_RPIPE_DELAY_0;
  /* SdramTiming */
  SdramTiming.LoadToActiveDelay = 16;
  SdramTiming.ExitSelfRefreshDelay = 16;
  SdramTiming.SelfRefreshTime = 16;
  SdramTiming.RowCycleDelay = 16;
  SdramTiming.WriteRecoveryTime = 16;
  SdramTiming.RPDelay = 16;
  SdramTiming.RCDDelay = 16;

  if (HAL_SDRAM_Init(&hsdram1, &SdramTiming) != HAL_OK)
  {
    Error_Handler( );
  }

}

static void MX_GPIO_Init(void)
{
  GPIO_InitTypeDef GPIO_InitStruct = {0};

  /* GPIO Ports Clock Enable */
  __HAL_RCC_GPIOF_CLK_ENABLE();
  __HAL_RCC_GPIOC_CLK_ENABLE();
  __HAL_RCC_GPIOA_CLK_ENABLE();
  __HAL_RCC_GPIOB_CLK_ENABLE();
  __HAL_RCC_GPIOG_CLK_ENABLE();
  __HAL_RCC_GPIOE_CLK_ENABLE();
  __HAL_RCC_GPIOD_CLK_ENABLE();

  /*Configure GPIO pin Output Level */
  HAL_GPIO_WritePin(GPIOD, GPIO_PIN_6, GPIO_PIN_RESET);

  /*Configure GPIO pin : PD6 */
  GPIO_InitStruct.Pin = GPIO_PIN_6;
  GPIO_InitStruct.Mode = GPIO_MODE_OUTPUT_PP;
  GPIO_InitStruct.Pull = GPIO_NOPULL;
  GPIO_InitStruct.Speed = GPIO_SPEED_FREQ_LOW;
  HAL_GPIO_Init(GPIOD, &GPIO_InitStruct);

  /*Configure GPIO pin : PD7 */
  GPIO_InitStruct.Pin = GPIO_PIN_7;
  GPIO_InitStruct.Mode = GPIO_MODE_INPUT;
  GPIO_InitStruct.Pull = GPIO_NOPULL;
  HAL_GPIO_Init(GPIOD, &GPIO_InitStruct);

}

void Error_Handler(void)
{
}

/************************ (C) COPYRIGHT STMicroelectronics *****END OF FILE****/
